VERSION ""

NS_ :

BS_:

BU_: RLPSU DPSU APSU PSB SHVU_RR vHS_B2 FCS EMCU SLB RCM CGW_CCU vDummy_HS_B ATS RLHV PFSU SGU ALBCU DSAU SWRC SHVU_FR RCS RRPSU BLTN_CAM SCM DLBCU OHCL RWPC RRHV WPC HOD ASAU

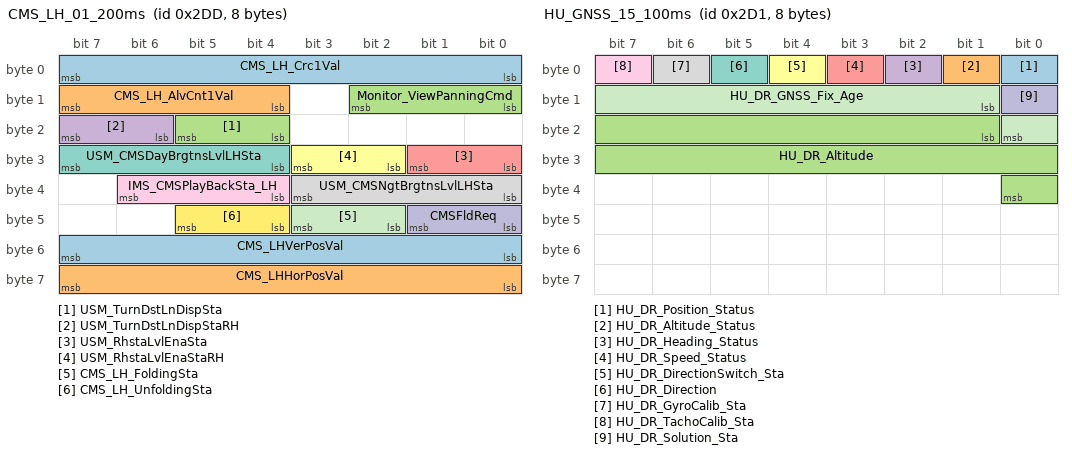
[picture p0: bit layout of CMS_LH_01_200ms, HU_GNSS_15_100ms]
BO_ 733 CMS_LH_01_200ms: 8 CGW_CCU
 SG_ CMS_LH_Crc1Val : 0|8@1+ (1,0) [0|0] ""  Vector__XXX
 SG_ CMS_LH_AlvCnt1Val : 12|4@1+ (1,0) [0|0] ""  Vector__XXX
 SG_ USM_TurnDstLnDispSta : 20|2@1+ (1,0) [0|0] ""  Vector__XXX
 SG_ USM_TurnDstLnDispStaRH : 22|2@1+ (1,0) [0|0] ""  Vector__XXX
 SG_ USM_RhstaLvlEnaSta : 24|2@1+ (1,0) [0|0] ""  Vector__XXX
 SG_ USM_RhstaLvlEnaStaRH : 26|2@1+ (1,0) [0|0] ""  Vector__XXX
 SG_ USM_CMSDayBrgtnsLvlLHSta : 28|4@1+ (1,0) [0|0] ""  Vector__XXX
 SG_ USM_CMSNgtBrgtnsLvlLHSta : 32|4@1+ (1,0) [0|0] ""  Vector__XXX
 SG_ IMS_CMSPlayBackSta_LH : 36|3@1+ (1,0) [0|0] ""  DPSU
 SG_ CMSFldReq : 40|2@1+ (1,0) [0|0] ""  Vector__XXX
 SG_ CMS_LH_FoldingSta : 42|2@1+ (1,0) [0|0] ""  Vector__XXX
 SG_ CMS_LH_UnfoldingSta : 44|2@1+ (1,0) [0|0] ""  Vector__XXX
 SG_ CMS_LHVerPosVal : 48|8@1+ (0.02,0) [0|0] "V"  Vector__XXX
 SG_ CMS_LHHorPosVal : 56|8@1+ (0.02,0) [0|0] "V"  Vector__XXX
 SG_ Monitor_ViewPanningCmd : 8|3@1+ (1,0) [0|0] ""  Vector__XXX

BO_ 721 HU_GNSS_15_100ms: 8 CGW_CCU
 SG_ HU_DR_Position_Status : 0|1@1+ (1,0) [0|0] ""  Vector__XXX
 SG_ HU_DR_Altitude_Status : 1|1@1+ (1,0) [0|0] ""  Vector__XXX
 SG_ HU_DR_Altitude : 17|16@1- (1,0) [0|0] "m"  BLTN_CAM
 SG_ HU_DR_Heading_Status : 2|1@1+ (1,0) [0|0] ""  Vector__XXX
 SG_ HU_DR_Speed_Status : 3|1@1+ (1,0) [0|0] ""  Vector__XXX
 SG_ HU_DR_DirectionSwitch_Sta : 4|1@1+ (1,0) [0|0] ""  Vector__XXX
 SG_ HU_DR_Direction : 5|1@1+ (1,0) [0|0] ""  Vector__XXX
 SG_ HU_DR_GyroCalib_Sta : 6|1@1+ (1,0) [0|0] ""  Vector__XXX
 SG_ HU_DR_TachoCalib_Sta : 7|1@1+ (1,0) [0|0] ""  Vector__XXX
 SG_ HU_DR_Solution_Sta : 8|1@1+ (1,0) [0|0] ""  Vector__XXX
 SG_ HU_DR_GNSS_Fix_Age : 9|8@1+ (1,0) [0|0] "Sec"  Vector__XXX

BO_ 722 HU_GNSS_16_100ms: 8 CGW_CCU
 SG_ HU_DR_Latitude : 0|32@1- (1,0) [0|0] "¢ª"  BLTN_CAM
 SG_ HU_DR_Longitude : 32|32@1- (1,0) [0|0] "¢ª"  BLTN_CAM

BO_ 723 HU_GNSS_17_100ms: 8 CGW_CCU
 SG_ HU_DR_Heading : 0|16@1+ (1,0) [0|0] "¢ª"  BLTN_CAM
 SG_ HU_DR_Speed : 16|16@1- (0.01,0) [0|0] "m/s"  Vector__XXX

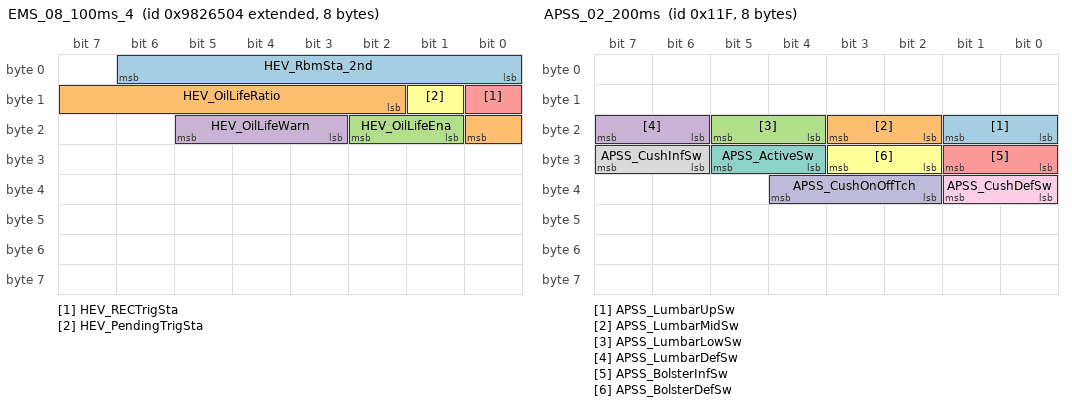
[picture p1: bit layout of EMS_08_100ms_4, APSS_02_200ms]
BO_ 2307024132 EMS_08_100ms_4: 8 CGW_CCU
 SG_ HEV_RbmSta_2nd : 0|7@1+ (1,0) [0|0] ""  Vector__XXX
 SG_ HEV_OilLifeRatio : 10|7@1+ (1,0) [0|0] "%"  Vector__XXX
 SG_ HEV_OilLifeEna : 17|2@1+ (1,0) [0|0] ""  Vector__XXX
 SG_ HEV_OilLifeWarn : 19|3@1+ (1,0) [0|0] ""  Vector__XXX
 SG_ HEV_RECTrigSta : 8|1@1+ (1,0) [0|0] ""  Vector__XXX
 SG_ HEV_PendingTrigSta : 9|1@1+ (1,0) [0|0] ""  Vector__XXX

BO_ 287 APSS_02_200ms: 8 APSU
 SG_ APSS_LumbarUpSw : 16|2@1+ (1,0) [0|0] ""  ALBCU,CGW_CCU
 SG_ APSS_LumbarMidSw : 18|2@1+ (1,0) [0|0] ""  ALBCU,CGW_CCU
 SG_ APSS_LumbarLowSw : 20|2@1+ (1,0) [0|0] ""  ALBCU,CGW_CCU
 SG_ APSS_LumbarDefSw : 22|2@1+ (1,0) [0|0] ""  ALBCU,CGW_CCU
 SG_ APSS_BolsterInfSw : 24|2@1+ (1,0) [0|0] ""  ALBCU,CGW_CCU
 SG_ APSS_BolsterDefSw : 26|2@1+ (1,0) [0|0] ""  ALBCU,CGW_CCU
 SG_ APSS_ActiveSw : 28|2@1+ (1,0) [0|0] ""  ALBCU
 SG_ APSS_CushInfSw : 30|2@1+ (1,0) [0|0] ""  ALBCU
 SG_ APSS_CushDefSw : 32|2@1+ (1,0) [0|0] ""  ALBCU
 SG_ APSS_CushOnOffTch : 34|3@1+ (1,0) [0|0] ""  ALBCU

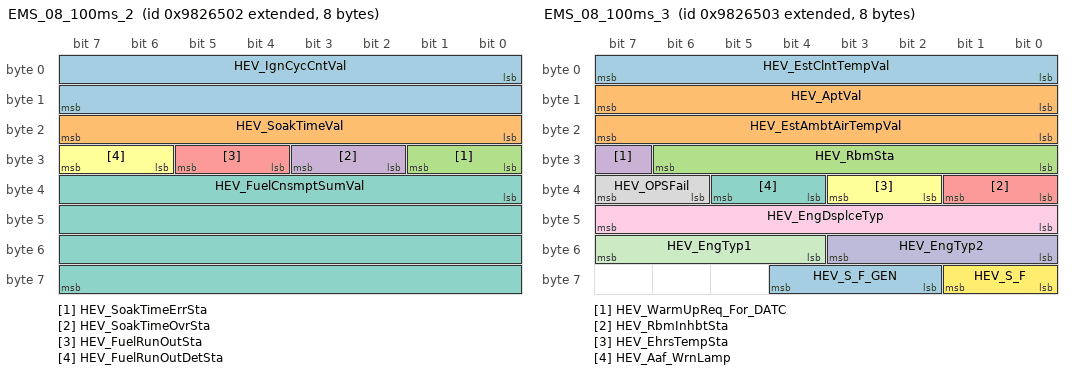
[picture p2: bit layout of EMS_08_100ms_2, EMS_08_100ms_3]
BO_ 2307024130 EMS_08_100ms_2: 8 CGW_CCU
 SG_ HEV_IgnCycCntVal : 0|16@1+ (1,0) [0|0] ""  Vector__XXX
 SG_ HEV_SoakTimeVal : 16|8@1+ (1,0) [0|0] "Min"  Vector__XXX
 SG_ HEV_SoakTimeErrSta : 24|2@1+ (1,0) [0|0] ""  Vector__XXX
 SG_ HEV_SoakTimeOvrSta : 26|2@1+ (1,0) [0|0] ""  Vector__XXX
 SG_ HEV_FuelRunOutSta : 28|2@1+ (1,0) [0|0] ""  Vector__XXX
 SG_ HEV_FuelRunOutDetSta : 30|2@1+ (1,0) [0|0] ""  Vector__XXX
 SG_ HEV_FuelCnsmptSumVal : 32|32@1+ (1.280018E-4,0) [0|0] "ml"  Vector__XXX

BO_ 2307024131 EMS_08_100ms_3: 8 CGW_CCU
 SG_ HEV_EstClntTempVal : 0|8@1+ (0.75,-48) [0|0] "¡É"  Vector__XXX
 SG_ HEV_EstAmbtAirTempVal : 16|8@1+ (0.75,-48) [0|0] "¡É"  Vector__XXX
 SG_ HEV_RbmSta : 24|7@1+ (1,0) [0|0] ""  Vector__XXX
 SG_ HEV_WarmUpReq_For_DATC : 31|1@1+ (1,0) [0|0] ""  Vector__XXX
 SG_ HEV_RbmInhbtSta : 32|2@1+ (1,0) [0|0] ""  Vector__XXX
 SG_ HEV_EhrsTempSta : 34|2@1+ (1,0) [0|0] ""  Vector__XXX
 SG_ HEV_Aaf_WrnLamp : 36|2@1+ (1,0) [0|0] ""  Vector__XXX
 SG_ HEV_OPSFail : 38|2@1+ (1,0) [0|0] ""  Vector__XXX
 SG_ HEV_EngDsplceTyp : 40|8@1+ (0.1,0) [0|0] "liter"  Vector__XXX
 SG_ HEV_EngTyp2 : 48|4@1+ (1,0) [0|0] ""  Vector__XXX
 SG_ HEV_EngTyp1 : 52|4@1+ (1,0) [0|0] ""  Vector__XXX
 SG_ HEV_S_F : 56|2@1+ (1,0) [0|0] ""  Vector__XXX
 SG_ HEV_S_F_GEN : 58|3@1+ (1,0) [0|0] ""  Vector__XXX
 SG_ HEV_AptVal : 8|8@1+ (2,0) [0|0] "PSI"  Vector__XXX

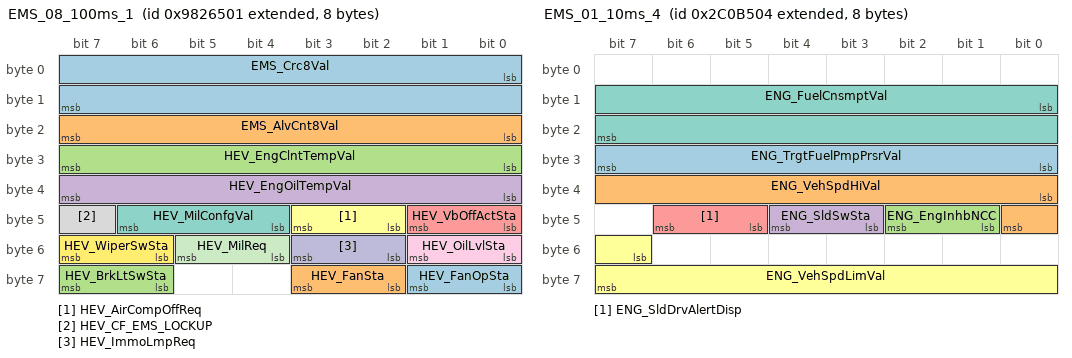
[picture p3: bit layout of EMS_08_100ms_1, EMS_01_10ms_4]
BO_ 2307024129 EMS_08_100ms_1: 8 CGW_CCU
 SG_ EMS_Crc8Val : 0|16@1+ (1,0) [0|0] ""  Vector__XXX
 SG_ EMS_AlvCnt8Val : 16|8@1+ (1,0) [0|0] ""  Vector__XXX
 SG_ HEV_EngClntTempVal : 24|8@1+ (0.75,-48) [0|0] "¡É"  Vector__XXX
 SG_ HEV_EngOilTempVal : 32|8@1+ (1,-40) [0|0] "¡É"  Vector__XXX
 SG_ HEV_VbOffActSta : 40|2@1+ (1,0) [0|0] ""  Vector__XXX
 SG_ HEV_AirCompOffReq : 42|2@1+ (1,0) [0|0] ""  Vector__XXX
 SG_ HEV_MilConfgVal : 44|3@1+ (1,0) [0|0] ""  Vector__XXX
 SG_ HEV_CF_EMS_LOCKUP : 47|1@1+ (1,0) [0|0] ""  Vector__XXX
 SG_ HEV_OilLvlSta : 48|2@1+ (1,0) [0|0] ""  Vector__XXX
 SG_ HEV_ImmoLmpReq : 50|2@1+ (1,0) [0|0] ""  Vector__XXX
 SG_ HEV_MilReq : 52|2@1+ (1,0) [0|0] ""  Vector__XXX
 SG_ HEV_WiperSwSta : 54|2@1+ (1,0) [0|0] ""  Vector__XXX
 SG_ HEV_FanOpSta : 56|2@1+ (1,0) [0|0] ""  Vector__XXX
 SG_ HEV_FanSta : 58|2@1+ (1,0) [0|0] ""  Vector__XXX
 SG_ HEV_BrkLtSwSta : 62|2@1+ (1,0) [0|0] ""  BLTN_CAM

BO_ 2193667332 EMS_01_10ms_4: 8 CGW_CCU
 SG_ ENG_TrgtFuelPmpPrsrVal : 24|8@1+ (3.137254902,0) [0|0] "kPa"  Vector__XXX
 SG_ ENG_VehSpdHiVal : 32|9@1+ (1,0) [0|0] "km/h"  Vector__XXX
 SG_ ENG_EngInhbNCC : 41|2@1+ (1,0) [0|0] ""  Vector__XXX
 SG_ ENG_SldSwSta : 43|2@1+ (1,0) [0|0] ""  Vector__XXX
 SG_ ENG_SldDrvAlertDisp : 45|2@1+ (1,0) [0|0] ""  Vector__XXX
 SG_ ENG_VehSpdLimVal : 55|9@1+ (1,0) [0|0] "km/h"  Vector__XXX
 SG_ ENG_FuelCnsmptVal : 8|16@1+ (0.128,0) [0|0] "ul"  Vector__XXX

BO_ 2193667331 EMS_01_10ms_3: 8 CGW_CCU
 SG_ ENG_TrgtIdleRpmVal : 0|8@1+ (10,0) [0|0] "rpm"  Vector__XXX
 SG_ ENG_GearShftDnDis : 10|2@1+ (1,0) [0|0] ""  Vector__XXX
 SG_ ENG_DsrGearPosDis : 12|4@1+ (1,0) [0|0] ""  Vector__XXX
 SG_ ENG_SldFuncSta : 16|2@1+ (1,0) [0|0] ""  Vector__XXX
 SG_ ENG_SldActnSta : 18|2@1+ (1,0) [0|0] ""  Vector__XXX
 SG_ ENG_FuelTnkPrsrSta : 20|2@1+ (1,0) [0|0] ""  Vector__XXX
 SG_ ENG_IsgBzrReq : 22|2@1+ (1,0) [0|0] ""  Vector__XXX
 SG_ ENG_IsgFuelCnsmptDis : 24|2@1+ (1,0) [0|0] ""  Vector__XXX
 SG_ ENG_FuelCapOpnSta : 26|2@1+ (1,0) [0|0] ""  Vector__XXX
 SG_ ENG_EcoDrvActvSta : 28|2@1+ (1,0) [0|0] ""  Vector__XXX
 SG_ ENG_EngRunSta : 30|2@1+ (1,0) [0|0] ""  Vector__XXX
 SG_ ENG_Isg2Sta : 32|2@1+ (2,0) [0|0] ""  Vector__XXX
 SG_ ENG_IgnOnSta : 34|2@1+ (1,0) [0|0] ""  Vector__XXX
 SG_ ENG_Ack4TcsSta : 36|2@1+ (1,0) [0|0] ""  Vector__XXX
 SG_ ENG_FuelCutOffSta : 38|2@1+ (1,0) [0|0] ""  Vector__XXX
 SG_ ENG_CrctTqSta : 40|2@1+ (1,0) [0|0] ""  Vector__XXX
 SG_ ENG_AirCompRlySta : 42|2@1+ (1,0) [0|0] ""  Vector__XXX
 SG_ ENG_LnchCntrlSta : 45|3@1+ (1,0) [0|0] ""  Vector__XXX
 SG_ ENG_EngSpdVal : 48|16@1+ (0.25,0) [0|0] "rpm"  EMCU
 SG_ ENG_GearShftUpDis : 8|2@1+ (1,0) [0|0] ""  Vector__XXX

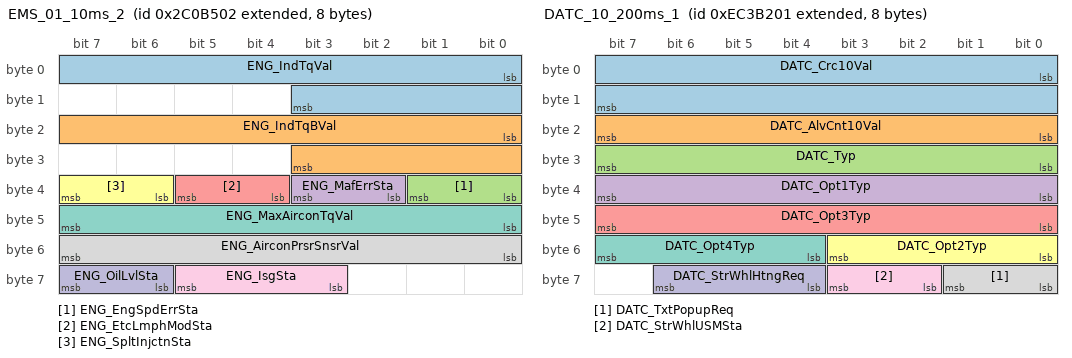
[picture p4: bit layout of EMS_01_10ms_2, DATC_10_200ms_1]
BO_ 2193667330 EMS_01_10ms_2: 8 CGW_CCU
 SG_ ENG_IndTqVal : 0|12@1- (1,0) [0|0] "Nm"  Vector__XXX
 SG_ ENG_IndTqBVal : 16|12@1- (1,0) [0|0] "Nm"  Vector__XXX
 SG_ ENG_EngSpdErrSta : 32|2@1+ (1,0) [0|0] ""  Vector__XXX
 SG_ ENG_MafErrSta : 34|2@1+ (1,0) [0|0] ""  Vector__XXX
 SG_ ENG_EtcLmphModSta : 36|2@1+ (1,0) [0|0] ""  Vector__XXX
 SG_ ENG_SpltInjctnSta : 38|2@1+ (1,0) [0|0] ""  Vector__XXX
 SG_ ENG_MaxAirconTqVal : 40|8@1+ (0.2,0) [0|0] "Nm"  Vector__XXX
 SG_ ENG_AirconPrsrSnsrVal : 48|8@1+ (125,0) [0|0] "hPa"  Vector__XXX
 SG_ ENG_IsgSta : 59|3@1+ (1,0) [0|0] ""  APSU,RLHV,RRHV,SHVU_FR,SHVU_RR,DPSU,RRPSU,RLPSU,EMCU
 SG_ ENG_OilLvlSta : 62|2@1+ (1,0) [0|0] ""  Vector__XXX

BO_ 2395189761 DATC_10_200ms_1: 8 CGW_CCU
 SG_ DATC_Crc10Val : 0|16@1+ (1,0) [0|0] ""  Vector__XXX
 SG_ DATC_AlvCnt10Val : 16|8@1+ (1,0) [0|0] ""  Vector__XXX
 SG_ DATC_Typ : 24|8@1+ (1,0) [0|0] ""  RLHV,RRHV,SHVU_FR,SHVU_RR,ATS
 SG_ DATC_Opt1Typ : 32|8@1+ (1,0) [0|0] ""  ATS
 SG_ DATC_Opt3Typ : 40|8@1+ (1,0) [0|0] ""  ATS
 SG_ DATC_Opt2Typ : 48|4@1+ (1,0) [0|0] ""  ATS
 SG_ DATC_Opt4Typ : 52|4@1+ (1,0) [0|0] ""  ATS
 SG_ DATC_TxtPopupReq : 56|2@1+ (1,0) [0|0] ""  Vector__XXX
 SG_ DATC_StrWhlUSMSta : 58|2@1+ (1,0) [0|0] ""  APSU
 SG_ DATC_StrWhlHtngReq : 60|3@1+ (1,0) [0|0] ""  Vector__XXX

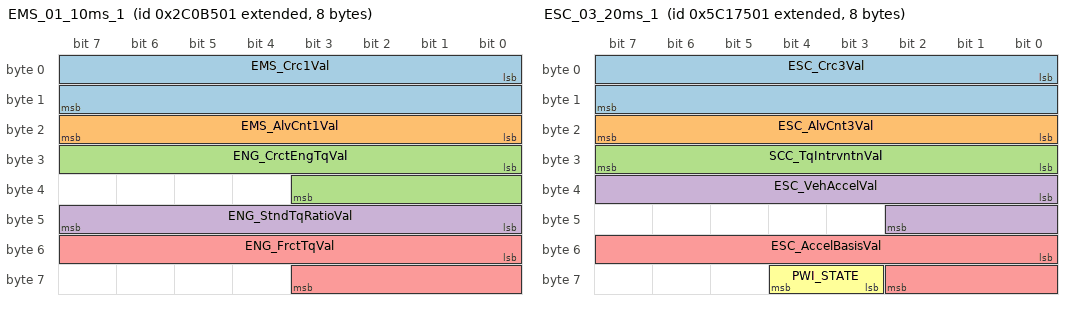
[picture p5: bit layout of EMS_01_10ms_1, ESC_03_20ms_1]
BO_ 2193667329 EMS_01_10ms_1: 8 CGW_CCU
 SG_ EMS_Crc1Val : 0|16@1+ (1,0) [0|0] ""  Vector__XXX
 SG_ EMS_AlvCnt1Val : 16|8@1+ (1,0) [0|0] ""  Vector__XXX
 SG_ ENG_CrctEngTqVal : 24|12@1- (1,0) [0|0] "Nm"  Vector__XXX
 SG_ ENG_StndTqRatioVal : 40|8@1+ (0.0078,0) [0|0] ""  Vector__XXX
 SG_ ENG_FrctTqVal : 48|12@1- (1,0) [0|0] "Nm"  Vector__XXX

BO_ 2214659332 EMS_07_10ms_4: 8 CGW_CCU

BO_ 2214659331 EMS_07_10ms_3: 8 CGW_CCU

BO_ 2244048129 ESC_03_20ms_1: 8 CGW_CCU
 SG_ ESC_Crc3Val : 0|16@1+ (1,0) [0|0] ""  Vector__XXX
 SG_ ESC_AlvCnt3Val : 16|8@1+ (1,0) [0|0] ""  Vector__XXX
 SG_ SCC_TqIntrvntnVal : 24|8@1+ (0.390625,0) [0|0] "%"  Vector__XXX
 SG_ ESC_VehAccelVal : 32|11@1+ (0.01,-10.23) [0|0] "m/s^2"  Vector__XXX
 SG_ ESC_AccelBasisVal : 48|11@1+ (0.01,-10.23) [0|0] "m/s^2"  Vector__XXX
 SG_ PWI_STATE : 59|2@1+ (1,0) [0|0] ""  Vector__XXX

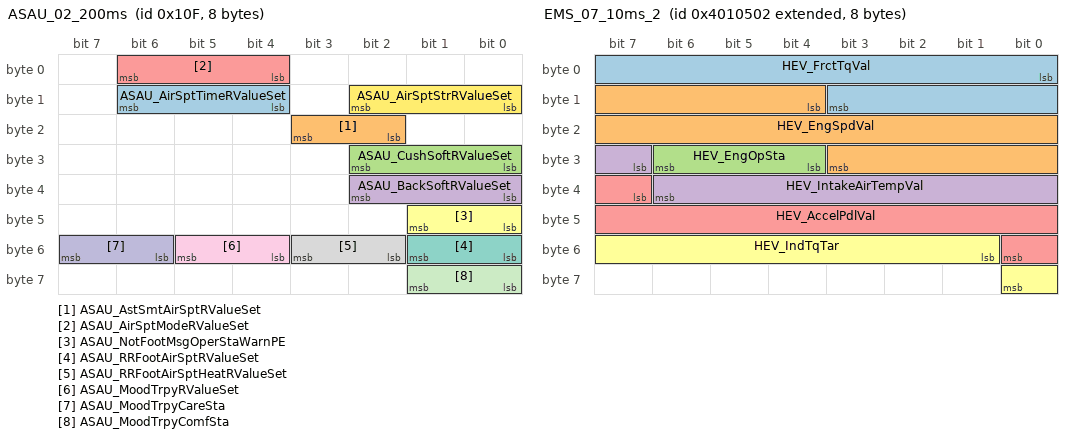
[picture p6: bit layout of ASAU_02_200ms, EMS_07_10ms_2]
BO_ 271 ASAU_02_200ms: 8 ASAU
 SG_ ASAU_AirSptTimeRValueSet : 12|3@1+ (1,0) [0|0] ""  CGW_CCU
 SG_ ASAU_AstSmtAirSptRValueSet : 18|2@1+ (1,0) [0|0] ""  CGW_CCU
 SG_ ASAU_CushSoftRValueSet : 24|3@1+ (1,0) [0|0] ""  CGW_CCU
 SG_ ASAU_BackSoftRValueSet : 32|3@1+ (1,0) [0|0] ""  CGW_CCU
 SG_ ASAU_AirSptModeRValueSet : 4|3@1+ (1,0) [0|0] ""  CGW_CCU
 SG_ ASAU_NotFootMsgOperStaWarnPE : 40|2@1+ (1,0) [0|0] ""  ATS
 SG_ ASAU_RRFootAirSptRValueSet : 48|2@1+ (1,0) [0|0] ""  ATS
 SG_ ASAU_RRFootAirSptHeatRValueSet : 50|2@1+ (1,0) [0|0] ""  ATS
 SG_ ASAU_MoodTrpyRValueSet : 52|2@1+ (1,0) [0|0] ""  CGW_CCU
 SG_ ASAU_MoodTrpyCareSta : 54|2@1+ (1,0) [0|0] ""  CGW_CCU
 SG_ ASAU_MoodTrpyComfSta : 56|2@1+ (1,0) [0|0] ""  CGW_CCU
 SG_ ASAU_AirSptStrRValueSet : 8|3@1+ (1,0) [0|0] ""  CGW_CCU

BO_ 2214659330 EMS_07_10ms_2: 8 CGW_CCU
 SG_ HEV_FrctTqVal : 0|12@1+ (0.1,0) [0|0] "Nm"  Vector__XXX
 SG_ HEV_EngSpdVal : 12|16@1+ (0.25,0) [0|0] "rpm"  Vector__XXX
 SG_ HEV_EngOpSta : 28|3@1+ (1,0) [0|0] ""  WPC,RWPC,PFSU
 SG_ HEV_IntakeAirTempVal : 31|8@1+ (0.75,-48) [0|0] "¡É"  Vector__XXX
 SG_ HEV_AccelPdlVal : 39|10@1+ (0.09784,0) [0|0] "%"  BLTN_CAM
 SG_ HEV_IndTqTar : 49|8@1+ (0.3906,0) [0|0] "%"  Vector__XXX

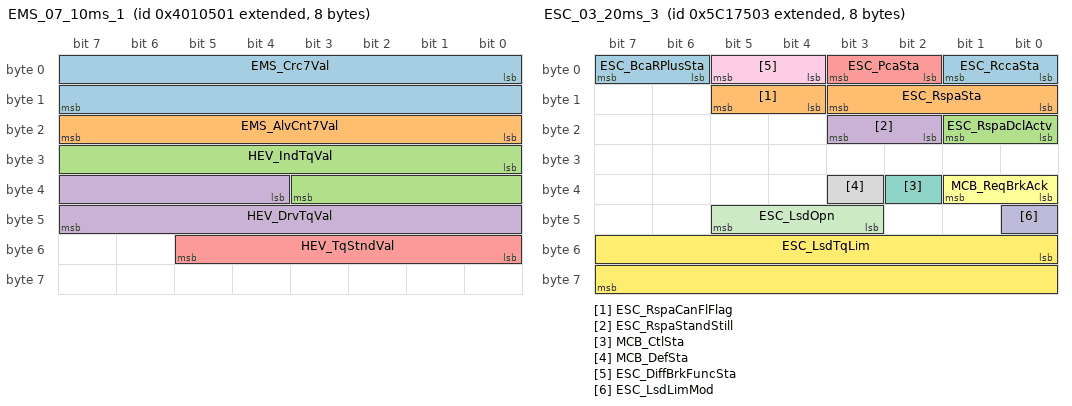
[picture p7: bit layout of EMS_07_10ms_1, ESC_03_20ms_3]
BO_ 2214659329 EMS_07_10ms_1: 8 CGW_CCU
 SG_ EMS_Crc7Val : 0|16@1+ (1,0) [0|0] ""  Vector__XXX
 SG_ EMS_AlvCnt7Val : 16|8@1+ (1,0) [0|0] ""  Vector__XXX
 SG_ HEV_IndTqVal : 24|12@1+ (0.1,0) [0|0] "Nm"  Vector__XXX
 SG_ HEV_DrvTqVal : 36|12@1+ (0.390625,0) [0|0] "%"  Vector__XXX
 SG_ HEV_TqStndVal : 48|6@1+ (10,0) [0|0] "Nm"  Vector__XXX

BO_ 2244048131 ESC_03_20ms_3: 8 CGW_CCU
 SG_ ESC_RccaSta : 0|2@1+ (1,0) [0|0] ""  Vector__XXX
 SG_ ESC_RspaCanFlFlag : 12|2@1+ (1,0) [0|0] ""  Vector__XXX
 SG_ ESC_RspaDclActv : 16|2@1+ (1,0) [0|0] ""  Vector__XXX
 SG_ ESC_RspaStandStill : 18|2@1+ (1,0) [0|0] ""  Vector__XXX
 SG_ ESC_PcaSta : 2|2@1+ (1,0) [0|0] ""  Vector__XXX
 SG_ MCB_ReqBrkAck : 32|2@1+ (1,0) [0|0] ""  Vector__XXX
 SG_ MCB_CtlSta : 34|1@1+ (1,0) [0|0] ""  Vector__XXX
 SG_ MCB_DefSta : 35|1@1+ (1,0) [0|0] ""  Vector__XXX
 SG_ ESC_DiffBrkFuncSta : 4|2@1+ (1,0) [0|0] ""  Vector__XXX
 SG_ ESC_LsdLimMod : 40|1@1+ (1,0) [0|0] ""  Vector__XXX
 SG_ ESC_LsdOpn : 43|3@1+ (1,0) [0|0] ""  Vector__XXX
 SG_ ESC_LsdTqLim : 48|16@1+ (1,0) [0|0] "Nm"  Vector__XXX
 SG_ ESC_BcaRPlusSta : 6|2@1+ (1,0) [0|0] ""  Vector__XXX
 SG_ ESC_RspaSta : 8|4@1+ (1,0) [0|0] ""  Vector__XXX

BO_ 2244048130 ESC_03_20ms_2: 8 CGW_CCU
 SG_ SCC_OptTyp : 0|2@1+ (1,0) [0|0] ""  Vector__XXX
 SG_ ESC_BrkLtReq : 10|2@1+ (1,0) [0|0] ""  Vector__XXX
 SG_ ESC_DclEnblReq : 12|2@1+ (1,0) [0|0] ""  Vector__XXX
 SG_ ESC_DrvOvrdSta : 16|2@1+ (1,0) [0|0] ""  Vector__XXX
 SG_ ESC_DrvBrkSta : 18|2@1+ (1,0) [0|0] ""  Vector__XXX
 SG_ SCC_EnblReq : 2|2@1+ (1,0) [0|0] ""  Vector__XXX
 SG_ ESC_DrvBrkActvSta : 20|2@1+ (1,0) [0|0] ""  Vector__XXX
 SG_ ESC_PrkBrkActvSta : 22|2@1+ (1,0) [0|0] ""  Vector__XXX
 SG_ ESC_HDP_FltMonSta : 24|3@1+ (1,0) [0|0] ""  PSB
 SG_ FCA_EquipSta : 32|2@1+ (1,0) [0|0] ""  Vector__XXX
 SG_ FCA_AvlblSta : 34|2@1+ (1,0) [0|0] ""  Vector__XXX
 SG_ ESC_FCA_ActvSta : 36|2@1+ (1,0) [0|0] ""  Vector__XXX
 SG_ ESC_DBS_ActvSta : 38|2@1+ (1,0) [0|0] ""  Vector__XXX
 SG_ SCC_TqReq : 4|2@1+ (1,0) [0|0] ""  Vector__XXX
 SG_ ESC_HDP_EgSta : 40|3@1+ (1,0) [0|0] ""  Vector__XXX
 SG_ ESC_HDP_EnblReq : 43|3@1+ (1,0) [0|0] ""  Vector__XXX
 SG_ ESC_BrkdFltStndstill : 56|2@1+ (1,0) [0|0] ""  Vector__XXX
 SG_ SCC_ReqLimSta : 6|2@1+ (1,0) [0|0] ""  Vector__XXX
 SG_ ESC_StdStillVal : 8|2@1+ (1,0) [0|0] ""  Vector__XXX

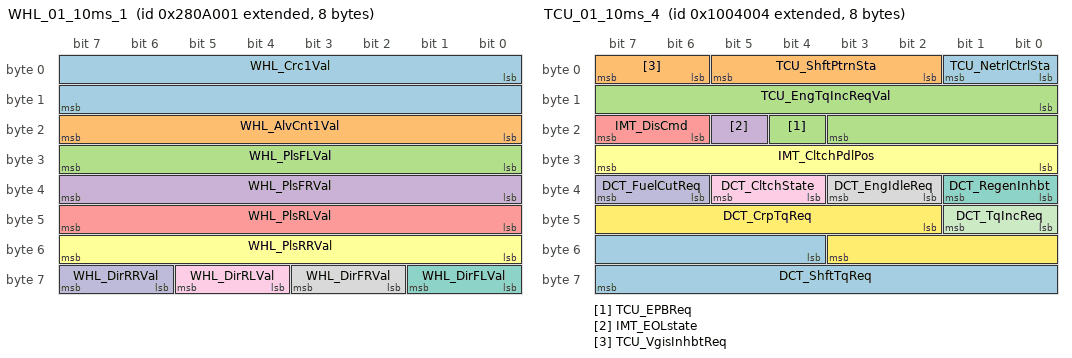
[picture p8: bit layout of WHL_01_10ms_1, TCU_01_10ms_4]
BO_ 2189467649 WHL_01_10ms_1: 8 CGW_CCU
 SG_ WHL_Crc1Val : 0|16@1+ (1,0) [0|0] ""  Vector__XXX
 SG_ WHL_AlvCnt1Val : 16|8@1+ (1,0) [0|0] ""  Vector__XXX
 SG_ WHL_PlsFLVal : 24|8@1+ (0.5,0) [0|0] "pulse count"  Vector__XXX
 SG_ WHL_PlsFRVal : 32|8@1+ (0.5,0) [0|0] "pulse count"  Vector__XXX
 SG_ WHL_PlsRLVal : 40|8@1+ (0.5,0) [0|0] "pulse count"  Vector__XXX
 SG_ WHL_PlsRRVal : 48|8@1+ (0.5,0) [0|0] "pulse count"  Vector__XXX
 SG_ WHL_DirFLVal : 56|2@1+ (1,0) [0|0] ""  Vector__XXX
 SG_ WHL_DirFRVal : 58|2@1+ (1,0) [0|0] ""  Vector__XXX
 SG_ WHL_DirRLVal : 60|2@1+ (1,0) [0|0] ""  Vector__XXX
 SG_ WHL_DirRRVal : 62|2@1+ (1,0) [0|0] ""  Vector__XXX

BO_ 2164277252 TCU_01_10ms_4: 8 CGW_CCU
 SG_ TCU_NetrlCtrlSta : 0|2@1+ (1,0) [0|0] ""  Vector__XXX
 SG_ TCU_ShftPtrnSta : 2|4@1+ (1,0) [0|0] ""  Vector__XXX
 SG_ TCU_EPBReq : 20|1@1+ (1,0) [0|0] ""  Vector__XXX
 SG_ IMT_EOLstate : 21|1@1+ (1,0) [0|0] ""  Vector__XXX
 SG_ IMT_DisCmd : 22|2@1+ (1,0) [0|0] ""  Vector__XXX
 SG_ IMT_CltchPdlPos : 24|8@1+ (0.390625,0) [0|0] "%"  Vector__XXX
 SG_ DCT_RegenInhbt : 32|2@1+ (1,0) [0|0] ""  Vector__XXX
 SG_ DCT_EngIdleReq : 34|2@1+ (1,0) [0|0] ""  Vector__XXX
 SG_ DCT_CltchState : 36|2@1+ (1,0) [0|0] ""  Vector__XXX
 SG_ DCT_FuelCutReq : 38|2@1+ (1,0) [0|0] ""  Vector__XXX
 SG_ DCT_TqIncReq : 40|2@1+ (1,0) [0|0] ""  Vector__XXX
 SG_ DCT_CrpTqReq : 42|10@1+ (1,-512) [0|0] "Nm"  Vector__XXX
 SG_ DCT_ShftTqReq : 52|12@1- (1,0) [0|0] "Nm"  Vector__XXX
 SG_ TCU_VgisInhbtReq : 6|2@1+ (1,0) [0|0] ""  Vector__XXX
 SG_ TCU_EngTqIncReqVal : 8|12@1- (1,0) [0|0] "Nm"  Vector__XXX

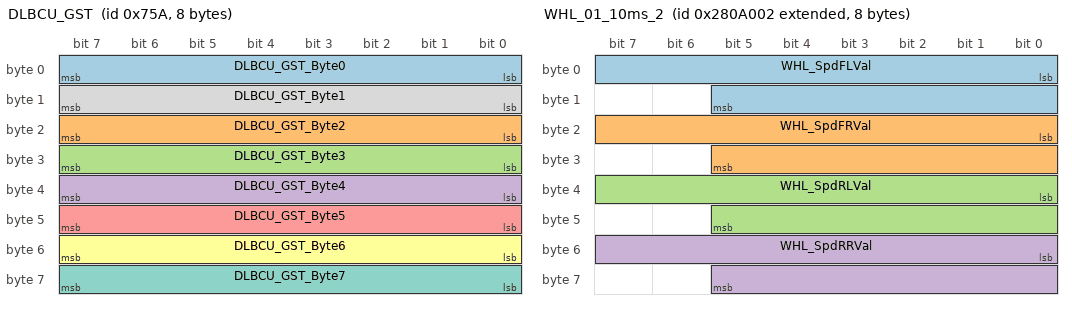
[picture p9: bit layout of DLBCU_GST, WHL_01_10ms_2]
BO_ 1882 DLBCU_GST: 8 DLBCU
 SG_ DLBCU_GST_Byte0 : 0|8@1+ (1,0) [0|0] ""  CGW_CCU
 SG_ DLBCU_GST_Byte2 : 16|8@1+ (1,0) [0|0] ""  CGW_CCU
 SG_ DLBCU_GST_Byte3 : 24|8@1+ (1,0) [0|0] ""  CGW_CCU
 SG_ DLBCU_GST_Byte4 : 32|8@1+ (1,0) [0|0] ""  CGW_CCU
 SG_ DLBCU_GST_Byte5 : 40|8@1+ (1,0) [0|0] ""  CGW_CCU
 SG_ DLBCU_GST_Byte6 : 48|8@1+ (1,0) [0|0] ""  CGW_CCU
 SG_ DLBCU_GST_Byte7 : 56|8@1+ (1,0) [0|0] ""  CGW_CCU
 SG_ DLBCU_GST_Byte1 : 8|8@1+ (1,0) [0|0] ""  CGW_CCU

BO_ 2189467650 WHL_01_10ms_2: 8 CGW_CCU
 SG_ WHL_SpdFLVal : 0|14@1+ (0.03125,0) [0|0] "km^h"  PSB
 SG_ WHL_SpdFRVal : 16|14@1+ (0.03125,0) [0|0] "km^h"  PSB
 SG_ WHL_SpdRLVal : 32|14@1+ (0.03125,0) [0|0] "km^h"  PSB,APSU
 SG_ WHL_SpdRRVal : 48|14@1+ (0.03125,0) [0|0] "km^h"  PSB,APSU

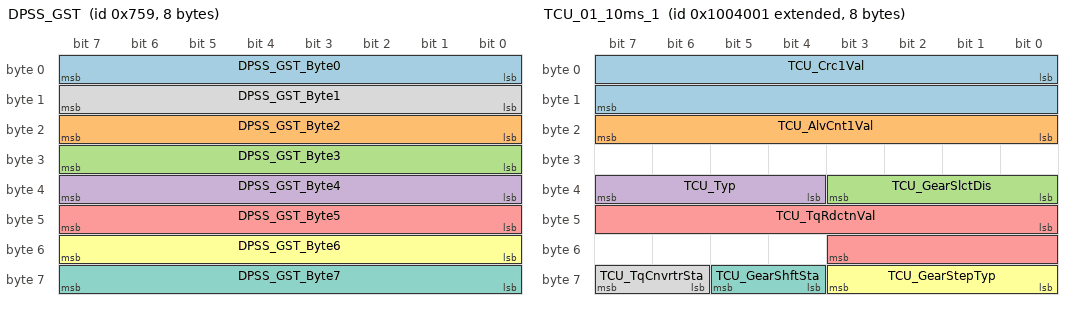
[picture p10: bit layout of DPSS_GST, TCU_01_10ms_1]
BO_ 1881 DPSS_GST: 8 DPSU
 SG_ DPSS_GST_Byte0 : 0|8@1+ (1,0) [0|0] ""  CGW_CCU
 SG_ DPSS_GST_Byte2 : 16|8@1+ (1,0) [0|0] ""  CGW_CCU
 SG_ DPSS_GST_Byte3 : 24|8@1+ (1,0) [0|0] ""  CGW_CCU
 SG_ DPSS_GST_Byte4 : 32|8@1+ (1,0) [0|0] ""  CGW_CCU
 SG_ DPSS_GST_Byte5 : 40|8@1+ (1,0) [0|0] ""  CGW_CCU
 SG_ DPSS_GST_Byte6 : 48|8@1+ (1,0) [0|0] ""  CGW_CCU
 SG_ DPSS_GST_Byte7 : 56|8@1+ (1,0) [0|0] ""  CGW_CCU
 SG_ DPSS_GST_Byte1 : 8|8@1+ (1,0) [0|0] ""  CGW_CCU

BO_ 2189467651 WHL_01_10ms_3: 8 CGW_CCU
 SG_ WHL_SpdCalParmtr : 8|9@1+ (0.5,200) [0|0] "mm"  Vector__XXX

BO_ 2164277249 TCU_01_10ms_1: 8 CGW_CCU
 SG_ TCU_Crc1Val : 0|16@1+ (1,0) [0|0] ""  Vector__XXX
 SG_ TCU_AlvCnt1Val : 16|8@1+ (1,0) [0|0] ""  EMCU
 SG_ TCU_GearSlctDis : 32|4@1+ (1,0) [0|0] ""  APSU,RLHV,RRHV,PFSU,RRPSU,RLPSU,BLTN_CAM
 SG_ TCU_Typ : 36|4@1+ (1,0) [0|0] ""  APSU,PFSU
 SG_ TCU_TqRdctnVal : 40|12@1- (1,0) [0|0] "Nm"  Vector__XXX
 SG_ TCU_GearStepTyp : 56|4@1+ (1,0) [0|0] ""  Vector__XXX
 SG_ TCU_GearShftSta : 60|2@1+ (1,0) [0|0] ""  Vector__XXX
 SG_ TCU_TqCnvrtrSta : 62|2@1+ (1,0) [0|0] ""  EMCU

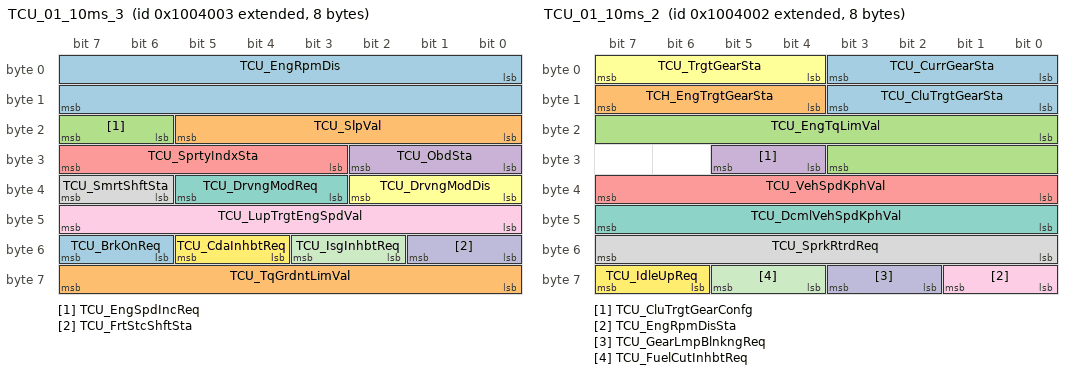
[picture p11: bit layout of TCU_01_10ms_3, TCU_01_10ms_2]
BO_ 2164277251 TCU_01_10ms_3: 8 CGW_CCU
 SG_ TCU_EngRpmDis : 0|16@1+ (0.25,0) [0|0] "rpm"  Vector__XXX
 SG_ TCU_SlpVal : 16|6@1+ (0.5,-16) [0|0] "%"  Vector__XXX
 SG_ TCU_EngSpdIncReq : 22|2@1+ (1,0) [0|0] ""  Vector__XXX
 SG_ TCU_ObdSta : 24|3@1+ (1,0) [0|0] ""  Vector__XXX
 SG_ TCU_SprtyIndxSta : 27|5@1+ (1,0) [0|0] ""  Vector__XXX
 SG_ TCU_DrvngModDis : 32|3@1+ (1,0) [0|0] ""  Vector__XXX
 SG_ TCU_DrvngModReq : 35|3@1+ (1,0) [0|0] ""  Vector__XXX
 SG_ TCU_SmrtShftSta : 38|2@1+ (1,0) [0|0] ""  Vector__XXX
 SG_ TCU_LupTrgtEngSpdVal : 40|8@1+ (10,500) [0|0] "rpm"  Vector__XXX
 SG_ TCU_FrtStcShftSta : 48|2@1+ (1,0) [0|0] ""  Vector__XXX
 SG_ TCU_IsgInhbtReq : 50|2@1+ (1,0) [0|0] ""  Vector__XXX
 SG_ TCU_CdaInhbtReq : 52|2@1+ (1,0) [0|0] ""  Vector__XXX
 SG_ TCU_BrkOnReq : 54|2@1+ (1,0) [0|0] ""  Vector__XXX
 SG_ TCU_TqGrdntLimVal : 56|8@1+ (10,0) [0|0] "Nm/s"  Vector__XXX

BO_ 2164277250 TCU_01_10ms_2: 8 CGW_CCU
 SG_ TCU_CurrGearSta : 0|4@1+ (1,0) [0|0] ""  EMCU
 SG_ TCH_EngTrgtGearSta : 12|4@1+ (1,0) [0|0] ""  Vector__XXX
 SG_ TCU_EngTqLimVal : 16|12@1- (1,0) [0|0] "Nm"  Vector__XXX
 SG_ TCU_CluTrgtGearConfg : 28|2@1+ (1,0) [0|0] ""  Vector__XXX
 SG_ TCU_VehSpdKphVal : 32|8@1+ (1,0) [0|0] "km/h"  Vector__XXX
 SG_ TCU_TrgtGearSta : 4|4@1+ (1,0) [0|0] ""  Vector__XXX
 SG_ TCU_DcmlVehSpdKphVal : 40|8@1+ (0.0078125,0) [0|0] "km/h"  Vector__XXX
 SG_ TCU_SprkRtrdReq : 48|8@1+ (0.375,-23.625) [0|0] "¢ª"  Vector__XXX
 SG_ TCU_EngRpmDisSta : 56|2@1+ (1,0) [0|0] ""  Vector__XXX
 SG_ TCU_GearLmpBlnkngReq : 58|2@1+ (1,0) [0|0] ""  Vector__XXX
 SG_ TCU_FuelCutInhbtReq : 60|2@1+ (1,0) [0|0] ""  Vector__XXX
 SG_ TCU_IdleUpReq : 62|2@1+ (1,0) [0|0] ""  Vector__XXX
 SG_ TCU_CluTrgtGearSta : 8|4@1+ (1,0) [0|0] ""  Vector__XXX

CM_ BO_ 287 "[PE] Periodic and On Event";
CM_ SG_ 287 APSS_LumbarUpSw "APSS_LumbarUpMoveSwitch";
CM_ SG_ 287 APSS_LumbarMidSw "APSS_LumbarMiddleSwitch";
CM_ SG_ 287 APSS_LumbarLowSw "APSS_LumbarLowerSwitch";
CM_ SG_ 287 APSS_LumbarDefSw "APSS_LumbarDeflationSwitch";
CM_ SG_ 287 APSS_BolsterInfSw "APSS_BolsterInflationSwitch";
CM_ SG_ 287 APSS_BolsterDefSw "APSS_BolsterDeflationSwitch";
CM_ SG_ 287 APSS_ActiveSw "APSS_ActiveSwitch";
CM_ SG_ 287 APSS_CushInfSw "APSS_Cush Support Inflation Switch";
CM_ SG_ 287 APSS_CushDefSw "APSS_Cush Support Deflation Switch";
CM_ SG_ 287 APSS_CushOnOffTch "APSS_CushOnOffTouch";
CM_ BO_ 271 "[PE] Periodic and On Event";
CM_ SG_ 271 ASAU_AirSptTimeRValueSet "Air Support Time(Massage Time) USM R Value";
CM_ SG_ 271 ASAU_AstSmtAirSptRValueSet "Seat Smart Air Support Function USM R Value";
CM_ SG_ 271 ASAU_CushSoftRValueSet "Cushion Soft R Value";
CM_ SG_ 271 ASAU_BackSoftRValueSet "Back Soft USM R Value";
CM_ SG_ 271 ASAU_AirSptModeRValueSet "Air Support Mode(Massage Mode) USM R Value";
CM_ SG_ 271 ASAU_NotFootMsgOperStaWarnPE "Passenger Foot Massage Operation Disable Mode";
CM_ SG_ 271 ASAU_RRFootAirSptRValueSet "Foot Air Support USM R Value";
CM_ SG_ 271 ASAU_RRFootAirSptHeatRValueSet "Foot Air Support Heat USM R Value";
CM_ SG_ 271 ASAU_MoodTrpyRValueSet "Passenger Seat Mood Therapy R Value";
CM_ SG_ 271 ASAU_MoodTrpyCareSta "Passenger Seat Mood Therapy Care Mode R Value";
CM_ SG_ 271 ASAU_MoodTrpyComfSta "Passenger Seat Mood Therapy Comfort Mode R Value";
CM_ SG_ 271 ASAU_AirSptStrRValueSet "Air Support Strenth(Massage Strenth) USM R Value";
CM_ BO_ 733 "[PE] Periodic and On Event";
CM_ SG_ 733 CMS_LH_Crc1Val "CMS_LH_CyclicRedundancyCheck1Value";
CM_ SG_ 733 CMS_LH_AlvCnt1Val "CMS_LH_AliveCounter1Value";
CM_ SG_ 733 CMS_LHVerPosVal "LH Outside Mirror Vertical Position sensor value";
CM_ SG_ 733 CMS_LHHorPosVal "LH Outside Mirror Horizontal Position Sensor Voltage";
CM_ SG_ 733 Monitor_ViewPanningCmd "Monitor_ViewPanningCommand";
CM_ BO_ 2395189761 "[PE] Periodic and On Event";
CM_ SG_ 2395189761 DATC_Crc10Val "DATC_CyclicRedundancyCheck10Value";
CM_ SG_ 2395189761 DATC_AlvCnt10Val "DATC_AliveCounter10Value";
CM_ SG_ 2395189761 DATC_Typ "DATC_Type";
CM_ SG_ 2395189761 DATC_Opt1Typ "DATC_Option1Type";
CM_ SG_ 2395189761 DATC_Opt3Typ "DATC_Option3Type";
CM_ SG_ 2395189761 DATC_Opt2Typ "DATC_Option2Type";
CM_ SG_ 2395189761 DATC_Opt4Typ "HTR CONTROL OPTION";
CM_ SG_ 2395189761 DATC_TxtPopupReq "DATC_TextPopupReq";
CM_ SG_ 2395189761 DATC_StrWhlUSMSta "DATC_SteeringWheelUSMState";
CM_ SG_ 2395189761 DATC_StrWhlHtngReq "DATC_SteeringWheelHeatReq";
CM_ BO_ 1882 "[TP] Transport Protocol";
CM_ BO_ 1881 "[TP] Transport Protocol";
CM_ BO_ 2193667329 "[P] Periodic";
CM_ SG_ 2193667329 EMS_Crc1Val "EMS_CyclicRedundancyCheck1Value";
CM_ SG_ 2193667329 EMS_AlvCnt1Val "EMS_AliveCounter1Value";
CM_ SG_ 2193667329 ENG_CrctEngTqVal "ENG_CorrectedEngineTorqueValue ##2G##EMS - EMS11 - TQI_ACOR";
CM_ SG_ 2193667329 ENG_StndTqRatioVal "ENG_StandardTorqueRatioValue ##2G##EMS - EMS11 - RATIO_TQI_BAS_MAX_STND";
CM_ SG_ 2193667329 ENG_FrctTqVal "ENG_FrictionTorqueValue ##2G##EMS - EMS11 - TQFR";
CM_ BO_ 2193667330 "[P] Periodic";
CM_ SG_ 2193667330 ENG_IndTqVal "ENG_IndicatedTorqueValue ##2G##EMS - EMS11 - TQI";
CM_ SG_ 2193667330 ENG_IndTqBVal "ENG_IndicatedTorqueBValue ##2G##EMS - EMS_H12 - TQI_B";
CM_ SG_ 2193667330 ENG_EngSpdErrSta "ENG_EngineSpeedErrorStatus ##2G##EMS - EMS11 - F_N_ENG";
CM_ SG_ 2193667330 ENG_MafErrSta "ENG_MassAirFlowErrorStatus ##2G##EMS - EMS11 - F_SUB_TQI";
CM_ SG_ 2193667330 ENG_EtcLmphModSta "ENG_EtcLimphomeModeStatus ##2G##EMS - EMS_H12 - CF_Ems_EtcLimpMod";
CM_ SG_ 2193667330 ENG_SpltInjctnSta "ENG_SplitInjectionStatus";
CM_ SG_ 2193667330 ENG_MaxAirconTqVal "ENG_MaximumAirconTorqueValue ##2G##EMS - EMS_H12 - R_TqAcnApvC";
CM_ SG_ 2193667330 ENG_AirconPrsrSnsrVal "ENG_AirconPressureSensorValue ##2G##EMS - EMS_H12 - R_PAcnC";
CM_ SG_ 2193667330 ENG_IsgSta "ENG_IsgStatus ##2G##EMS - EMS_H12 - CF_Ems_IsgStat";
CM_ SG_ 2193667330 ENG_OilLvlSta "ENG_OilLevelStatus ##2G##EMS - EMS_H12 - CF_Ems_OilChg";
CM_ BO_ 2193667331 "[P] Periodic";
CM_ SG_ 2193667331 ENG_TrgtIdleRpmVal "ENG_TargetIdleRpmValue ##2G##EMS - EMS_H12 - R_NEngIdlTgC";
CM_ SG_ 2193667331 ENG_GearShftDnDis "ENG_GearShiftDownDisplay ##2G##EMS - EMS_H12 - CF_Ems_DownTarGr";
CM_ SG_ 2193667331 ENG_DsrGearPosDis "ENG_DesirableGearPositionDisplay ##2G##EMS - EMS_H12 - CF_Ems_DesCurGr";
CM_ SG_ 2193667331 ENG_SldFuncSta "ENG_SpeedLimitFunctionStatus ##2G##EMS - EMS_H12 - CF_Ems_SldAct";
CM_ SG_ 2193667331 ENG_SldActnSta "ENG_SpeedLimitActionStatus ##2G##EMS - EMS_H12 - CF_Ems_SldPosAct";
CM_ SG_ 2193667331 ENG_FuelTnkPrsrSta "ENG_FuelTankPressureStatus ##2G##EMS - EMS_H12 - CF_Ems_HPresStat";
CM_ SG_ 2193667331 ENG_IsgBzrReq "ENG_IsgBuzzerRequest ##2G##EMS - EMS_H12 - CF_Ems_IsgBuz";
CM_ SG_ 2193667331 ENG_IsgFuelCnsmptDis "ENG_IsgFuelConsumptionDisplay ##2G##EMS - EMS_H12 - CF_Ems_IdlStpFCO";
CM_ SG_ 2193667331 ENG_FuelCapOpnSta "ENG_FuelCapOpenStatus ##2G##EMS - EMS_H12 - CF_Ems_FCopen";
CM_ SG_ 2193667331 ENG_EcoDrvActvSta "ENG_EcoDriveActiveStatus ##2G##EMS - EMS_H12 - CF_Ems_ActEcoAct";
CM_ SG_ 2193667331 ENG_EngRunSta "ENG_EngineRunningStatus ##2G##EMS - EMS_H12 - CF_Ems_EngRunNorm";
CM_ SG_ 2193667331 ENG_Isg2Sta "ENG_Isg2Status ##2G##EMS - EMS_H12 - CF_Ems_IsgStat2";
CM_ SG_ 2193667331 ENG_IgnOnSta "ENG_IgnitionOnStatus ##2G##EMS - EMS11 - SWI_IGK";
CM_ SG_ 2193667331 ENG_Ack4TcsSta "ENG_AcknowledgeForTcsStatus ##2G##EMS - EMS11 - ACK_TCS";
CM_ SG_ 2193667331 ENG_FuelCutOffSta "ENG_FuelCutOffStatus ##2G##EMS - EMS11 - PUC_STAT";
CM_ SG_ 2193667331 ENG_CrctTqSta "ENG_CorrectedTorqueStatus ##2G##EMS - EMS11 - TQ_COR_STAT";
CM_ SG_ 2193667331 ENG_AirCompRlySta "ENG_AirCompressorRelayStatus ##2G##EMS - EMS11 - RLY_AC";
CM_ SG_ 2193667331 ENG_LnchCntrlSta "ENG_LaunchControlStatus";
CM_ SG_ 2193667331 ENG_EngSpdVal "ENG_EngineSpeedValue ##2G##EMS - EMS11 - N";
CM_ SG_ 2193667331 ENG_GearShftUpDis "ENG_GearShiftUpDisplay ##2G##EMS - EMS_H12 - CF_Ems_UpTarGr";
CM_ BO_ 2193667332 "[P] Periodic";
CM_ SG_ 2193667332 ENG_TrgtFuelPmpPrsrVal "ENG_TargetFuelPumpPressureValue ##2G##EMS - EMS20 - CF_Ems_PumpTPres";
CM_ SG_ 2193667332 ENG_VehSpdHiVal "ENG_VehicleSpeedHighValue";
CM_ SG_ 2193667332 ENG_EngInhbNCC "This signal indicates the Inhibition of NCC MODE";
CM_ SG_ 2193667332 ENG_SldSwSta "The status of Speed limiter function.";
CM_ SG_ 2193667332 ENG_SldDrvAlertDisp "The status of No Sld Engaged or Sld Disengaged.";
CM_ SG_ 2193667332 ENG_VehSpdLimVal "ENG_VehicleSpeedLimitValue ##2G##EMS - EMS_H12 - SLD_VS, EMS20-SLD_VS_EXT";
CM_ SG_ 2193667332 ENG_FuelCnsmptVal "ENG_FuelConsumptionValue ##2G##EMS - EMS20 - FCO";
CM_ BO_ 2214659329 "[P] Periodic";
CM_ SG_ 2214659329 EMS_Crc7Val "EMS_CyclicRedundancyCheck7Value";
CM_ SG_ 2214659329 EMS_AlvCnt7Val "EMS_AliveCounter7Value";
CM_ SG_ 2214659329 HEV_IndTqVal "HEV_IndicatedTorqueValue";
CM_ SG_ 2214659329 HEV_DrvTqVal "HEV_DriverTorqueValue";
CM_ SG_ 2214659329 HEV_TqStndVal "HEV_TorqueStandardValue";
CM_ BO_ 2214659330 "[P] Periodic";
CM_ SG_ 2214659330 HEV_FrctTqVal "HEV_FrictionTorqueValue";
CM_ SG_ 2214659330 HEV_EngSpdVal "HEV_EngineSpeedValue";
CM_ SG_ 2214659330 HEV_EngOpSta "HEV_EngineOperatingStatus";
CM_ SG_ 2214659330 HEV_IntakeAirTempVal "HEV_IntakeAirTemperatureValue";
CM_ SG_ 2214659330 HEV_AccelPdlVal "HEV_AcceleratorPedalValue";
CM_ SG_ 2214659330 HEV_IndTqTar "HEV_IndicatedTorqueTarget";
CM_ BO_ 2214659331 "[P] Periodic";
CM_ BO_ 2214659332 "[P] Periodic";
CM_ BO_ 2307024129 "[P] Periodic";
CM_ SG_ 2307024129 EMS_Crc8Val "EMS_CyclicRedundancyCheck8Value";
CM_ SG_ 2307024129 EMS_AlvCnt8Val "EMS_AliveCounter8Value";
CM_ SG_ 2307024129 HEV_EngClntTempVal "HEV_EngineCoolantTemperatureValue";
CM_ SG_ 2307024129 HEV_EngOilTempVal "HEV_EngineOilTemperatureValue";
CM_ SG_ 2307024129 HEV_VbOffActSta "HEV_VbOffActStatus";
CM_ SG_ 2307024129 HEV_AirCompOffReq "HEV_AirCompressorOffRequest";
CM_ SG_ 2307024129 HEV_MilConfgVal "HEV_MilConfigurationValue";
CM_ SG_ 2307024129 HEV_CF_EMS_LOCKUP "Engine lock up mainentance request state";
CM_ SG_ 2307024129 HEV_OilLvlSta "HEV_OilLevelStatus";
CM_ SG_ 2307024129 HEV_ImmoLmpReq "HEV_ImmobilizerLampRequest";
CM_ SG_ 2307024129 HEV_MilReq "HEV_MalfunctionIndicationLampRequest";
CM_ SG_ 2307024129 HEV_WiperSwSta "HEV_WiperSwitchStatus";
CM_ SG_ 2307024129 HEV_FanOpSta "HEV_CoolingFanOperatingStatus";
CM_ SG_ 2307024129 HEV_FanSta "HEV_CoolingFanStatus";
CM_ SG_ 2307024129 HEV_BrkLtSwSta "HEV_BrakeLightSwitchStatus";
CM_ BO_ 2307024130 "[P] Periodic";
CM_ SG_ 2307024130 HEV_IgnCycCntVal "HEV_IgnitionCycleCounterValue";
CM_ SG_ 2307024130 HEV_SoakTimeVal "HEV_SoakTimeValue";
CM_ SG_ 2307024130 HEV_SoakTimeErrSta "HEV_SoakTimeErrorStatus";
CM_ SG_ 2307024130 HEV_SoakTimeOvrSta "HEV_SoakTimeOverStatus";
CM_ SG_ 2307024130 HEV_FuelRunOutSta "HEV_FuelRunOutStatus";
CM_ SG_ 2307024130 HEV_FuelRunOutDetSta "HEV_FuelRunOutDetectStatus";
CM_ SG_ 2307024130 HEV_FuelCnsmptSumVal "HEV_FuelConsumptionSumValue";
CM_ BO_ 2307024131 "[P] Periodic";
CM_ SG_ 2307024131 HEV_EstClntTempVal "HEV_EstimatedCoolantTemperatureValue";
CM_ SG_ 2307024131 HEV_EstAmbtAirTempVal "HEV_EstimatedAmbientAirTemperatureValue";
CM_ SG_ 2307024131 HEV_RbmSta "HEV_RateBasedMonitoringStatus";
CM_ SG_ 2307024131 HEV_WarmUpReq_For_DATC "HEV_WarmUpRequest";
CM_ SG_ 2307024131 HEV_RbmInhbtSta "HEV_RbmInhibitionStatus";
CM_ SG_ 2307024131 HEV_EhrsTempSta "HEV_EhrsTemperatureStatus";
CM_ SG_ 2307024131 HEV_Aaf_WrnLamp "Air Flap Warning Lamp/Message Request Signal indicates whether Warning Lamp/Message should be displayed in the display screen in order to warn AAF System failure to customer.";
CM_ SG_ 2307024131 HEV_OPSFail "Oil Pressure Warning Lamp Status";
CM_ SG_ 2307024131 HEV_EngDsplceTyp "HEV_EngineDisplacementType ##2G##EMS - EMS12 - ENG_VOL";
CM_ SG_ 2307024131 HEV_EngTyp2 "HEV_EngineType2 ##2G##EMS - EMS23 - ENG_TYPE";
CM_ SG_ 2307024131 HEV_EngTyp1 "HEV_EngineType1 ##2G##EMS - EMS12 - ENG_CHR";
CM_ SG_ 2307024131 HEV_S_F "AMS/ISG system type indicator";
CM_ SG_ 2307024131 HEV_S_F_GEN "system generation type indicator";
CM_ SG_ 2307024131 HEV_AptVal "HEV_AptValue";
CM_ BO_ 2307024132 "[P] Periodic";
CM_ SG_ 2307024132 HEV_RbmSta_2nd "HEV_RateBasedMonitoringStatus";
CM_ SG_ 2307024132 HEV_OilLifeRatio "Remaining engine oil life with % unit";
CM_ SG_ 2307024132 HEV_OilLifeEna "Enabling information if engine oil life monitoring from EMS is applied or not";
CM_ SG_ 2307024132 HEV_OilLifeWarn "Request to activate engine oil life warning";
CM_ SG_ 2307024132 HEV_RECTrigSta "VCRM trigger bit by REC";
CM_ SG_ 2307024132 HEV_PendingTrigSta "VCRM trigger bit by pending DTC";
CM_ BO_ 2244048129 "[P] Periodic";
CM_ SG_ 2244048129 ESC_Crc3Val "ESC_CyclicRedundancyCheck3Value";
CM_ SG_ 2244048129 ESC_AlvCnt3Val "ESC_AliveCounter3Value";
CM_ SG_ 2244048129 SCC_TqIntrvntnVal "SCC_TorqueInterventionValue ##2G##ESC - TCS13 - TQI_ACC";
CM_ SG_ 2244048129 ESC_VehAccelVal "ESC_VehicleAccelerationValue ##2G##ESC - TCS13 - ACCEL_REF_ACC";
CM_ SG_ 2244048129 ESC_AccelBasisVal "ESC_AccelerationBasisValue ##2G##ESC - TCS13 - aBasis";
CM_ BO_ 2244048130 "[P] Periodic";
CM_ SG_ 2244048130 SCC_OptTyp "SCC_OptionType ##2G##ESC - TCS13 - ACC_EQUIP";
CM_ SG_ 2244048130 ESC_BrkLtReq "ESC_BrakeLightRequest ##2G##ESC - TCS13 - BrakeLight";
CM_ SG_ 2244048130 ESC_DclEnblReq "ESC_DecelerationEnableRequest ##2G##ESC - TCS13 - DCEnable";
CM_ SG_ 2244048130 ESC_DrvOvrdSta "ESC_OverrideRequest ##2G##ESC - TCS13 - DriverOverride";
CM_ SG_ 2244048130 ESC_DrvBrkSta "ESC_DriverBrakingStatus ##2G##ESC - TCS13 - CF_DriBkeStat";
CM_ SG_ 2244048130 SCC_EnblReq "SCC_EnableRequest ##2G##ESC - TCS13 - ACCEnable";
CM_ SG_ 2244048130 ESC_DrvBrkActvSta "ESC_DriverBrakingActiveStatus ##2G##ESC - TCS13 - DriverBraking";
CM_ SG_ 2244048130 ESC_PrkBrkActvSta "ESC_ParkingBrakeActiveStatus ##2G##ESC - TCS13 - PBRAKE_ACT";
CM_ SG_ 2244048130 ESC_HDP_FltMonSta "ESC_HDP_FaultStatus";
CM_ SG_ 2244048130 FCA_EquipSta "FCA_EquipmentStatus ##2G##ESC - TCS13 - FCA_EQUIP";
CM_ SG_ 2244048130 FCA_AvlblSta "VSM_AvailableStatus ##2G##ESC - TCS13 - CF_VSM_Avail";
CM_ SG_ 2244048130 ESC_FCA_ActvSta "Status of control for FCA control request flag";
CM_ SG_ 2244048130 ESC_DBS_ActvSta "ESC_DBS_ActvSta ##2G## ESC - TCS11 - DBS_ACK";
CM_ SG_ 2244048130 SCC_TqReq "SCC_TorqueRequest ##2G##ESC - TCS13 - ACC_REQ";
CM_ SG_ 2244048130 ESC_HDP_EgSta "ESC_HDP_EngagedStatus";
CM_ SG_ 2244048130 ESC_HDP_EnblReq "ESC_HDP_EnableRequest";
CM_ SG_ 2244048130 ESC_BrkdFltStndstill "Detect Indication of braked, flatland and standstill state";
CM_ SG_ 2244048130 SCC_ReqLimSta "SCC_RequestLimitedStatus ##2G##ESC - TCS13 - ACCReqLim";
CM_ SG_ 2244048130 ESC_StdStillVal "ESC_StandStillValue ##2G##ESC - TCS13 - StandStill";
CM_ BO_ 2244048131 "[P] Periodic";
CM_ SG_ 2244048131 ESC_RccaSta "ESC_RccaStatus ##2G##ESC - ESP11 - ESP_RCCA_STAT";
CM_ SG_ 2244048131 ESC_RspaCanFlFlag "##2G##ESC - ESP11 - ESC_RspaCanfailflag";
CM_ SG_ 2244048131 ESC_RspaDclActv "##2G##ESC - ESP11 - ESC_RSPA_DEC_ACT";
CM_ SG_ 2244048131 ESC_RspaStandStill "##2G##ESC - ESP11 - ESC_RSPA_STANDSTILL";
CM_ SG_ 2244048131 ESC_PcaSta "ESC_PcaStatus";
CM_ SG_ 2244048131 MCB_ReqBrkAck "Acknowledge Status for MCB Brake Request";
CM_ SG_ 2244048131 MCB_CtlSta "Status for MCB Activation";
CM_ SG_ 2244048131 MCB_DefSta "Status for MCB defect";
CM_ SG_ 2244048131 ESC_DiffBrkFuncSta "ESC_DifferentialBrakeFunctionStatus ##2G##ESC - TCS13 - DF_BF_STAT";
CM_ SG_ 2244048131 ESC_LsdLimMod "eLSD torque limit mode ##2G##ESC - ESP_LSD11 - LSD_LIM_MODE";
CM_ SG_ 2244048131 ESC_LsdOpn "eLSD clutch open mode ##2G##ESC - ESP_LSD11 - LSD_OPEN";
CM_ SG_ 2244048131 ESC_LsdTqLim "value of the torquel limit of eLSD ##2G##ESC - ESP_LSD11 - LSD_TQC_LIM";
CM_ SG_ 2244048131 ESC_BcaRPlusSta "ESC_BcaRPlusStatus";
CM_ SG_ 2244048131 ESC_RspaSta "ESC_RspaStatus ##2G##ESC - ESP11 - ESP_RSPA_STAT";
CM_ BO_ 721 "[P] Periodic";
CM_ SG_ 721 HU_DR_Position_Status "DR Position status";
CM_ SG_ 721 HU_DR_Altitude_Status "DR Altitude Status";
CM_ SG_ 721 HU_DR_Altitude "range [-400,10000]";
CM_ SG_ 721 HU_DR_Heading_Status "DR Heading Status";
CM_ SG_ 721 HU_DR_Speed_Status "DR Speed status";
CM_ SG_ 721 HU_DR_DirectionSwitch_Sta "DR DirectionSwitch Status";
CM_ SG_ 721 HU_DR_Direction "DR Direction, Backward";
CM_ SG_ 721 HU_DR_GyroCalib_Sta "DR Gyro Calibration Status";
CM_ SG_ 721 HU_DR_TachoCalib_Sta "DR Tacho Calibration Status";
CM_ SG_ 721 HU_DR_GNSS_Fix_Age "Time since last GNSS fix";
CM_ BO_ 722 "[P] Periodic";
CM_ SG_ 722 HU_DR_Latitude "1sc(semi-cicle)= pi rad=180  /   unit : 2^-31sc  /  range [-1/2~1/2] sc";
CM_ SG_ 722 HU_DR_Longitude "1sc(semi-circle)=pi rad=180 / unit:2^-31sc / range:[-1, 1]sc";
CM_ BO_ 723 "[P] Periodic";
CM_ SG_ 723 HU_DR_Heading "1sc(semi-circle)=pi rad=180 / unit=2^-15sc / range:[0,2]SC";
CM_ SG_ 723 HU_DR_Speed "unit : 1cm/s";
CM_ BO_ 2164277249 "[P] Periodic";
CM_ SG_ 2164277249 TCU_Crc1Val "TCU_CyclicRedundancyCheck1Value";
CM_ SG_ 2164277249 TCU_AlvCnt1Val "TCU_AliveCounter1Value";
CM_ SG_ 2164277249 TCU_GearSlctDis "TCU_GearSelectDisplay";
CM_ SG_ 2164277249 TCU_Typ "TCU_Type";
CM_ SG_ 2164277249 TCU_TqRdctnVal "TCU_TorqueReductionValue";
CM_ SG_ 2164277249 TCU_GearStepTyp "TCU_GearStepType";
CM_ SG_ 2164277249 TCU_GearShftSta "TCU_GearShiftStatus";
CM_ SG_ 2164277249 TCU_TqCnvrtrSta "TCU_TorqueConverterStatus";
CM_ BO_ 2164277250 "[P] Periodic";
CM_ SG_ 2164277250 TCU_CurrGearSta "TCU_CurrentGearStatus";
CM_ SG_ 2164277250 TCH_EngTrgtGearSta "TCU_EngineTargetGear";
CM_ SG_ 2164277250 TCU_EngTqLimVal "TCU_EngineTorqueLimitValue";
CM_ SG_ 2164277250 TCU_CluTrgtGearConfg "Signal source Configuration of  Target gear for CLU";
CM_ SG_ 2164277250 TCU_VehSpdKphVal "TCU_VehicleSpeedKphValue";
CM_ SG_ 2164277250 TCU_TrgtGearSta "TCU_TargetGearStatus";
CM_ SG_ 2164277250 TCU_DcmlVehSpdKphVal "TCU_VehicleSpeedDecimalKphValue";
CM_ SG_ 2164277250 TCU_SprkRtrdReq "TCU_SparkRetardAngleValue";
CM_ SG_ 2164277250 TCU_EngRpmDisSta "TCU_EngineRpmDisplayStatus";
CM_ SG_ 2164277250 TCU_GearLmpBlnkngReq "TCU_GearLampBlinkingRequest";
CM_ SG_ 2164277250 TCU_FuelCutInhbtReq "TCU_FuelCutInhibitionRequest";
CM_ SG_ 2164277250 TCU_IdleUpReq "TCU_IdleUpRequest";
CM_ SG_ 2164277250 TCU_CluTrgtGearSta "TCU_ClusterTargetGear";
CM_ BO_ 2164277251 "[P] Periodic";
CM_ SG_ 2164277251 TCU_EngRpmDis "TCU_EngineRpmDisplay";
CM_ SG_ 2164277251 TCU_SlpVal "TCU_SlopeValue";
CM_ SG_ 2164277251 TCU_EngSpdIncReq "TCU_EngineSpeedIncreaseRequest";
CM_ SG_ 2164277251 TCU_ObdSta "TCU_ObdStatus";
CM_ SG_ 2164277251 TCU_SprtyIndxSta "TCU_SportyIndexStatus";
CM_ SG_ 2164277251 TCU_DrvngModDis "TCU_DrivingModeDisplay";
CM_ SG_ 2164277251 TCU_DrvngModReq "TCU_DrivingModeRequest";
CM_ SG_ 2164277251 TCU_SmrtShftSta "TCU_SmartShiftStatus";
CM_ SG_ 2164277251 TCU_LupTrgtEngSpdVal "TCU_LupTargetEngineSpeedValue";
CM_ SG_ 2164277251 TCU_FrtStcShftSta "TCU_FirstStaticShiftStatus";
CM_ SG_ 2164277251 TCU_IsgInhbtReq "TCU_IsgInhibitRequest";
CM_ SG_ 2164277251 TCU_CdaInhbtReq "TCU_CdaInhibitRequest";
CM_ SG_ 2164277251 TCU_BrkOnReq "TCU_BrakeOnRequest";
CM_ SG_ 2164277251 TCU_TqGrdntLimVal "TCU_TorqueGradientLimitationValue";
CM_ BO_ 2164277252 "[P] Periodic";
CM_ SG_ 2164277252 TCU_NetrlCtrlSta "TCU_NeutralControlStatus";
CM_ SG_ 2164277252 TCU_ShftPtrnSta "TCU_ShiftPatternStatus";
CM_ SG_ 2164277252 TCU_EPBReq "EPB Request signal for prevent P-D Shock on hill";
CM_ SG_ 2164277252 IMT_EOLstate "Gear Display for EOL mode to cluster. This signal is for IMT system only.";
CM_ SG_ 2164277252 IMT_DisCmd "Gear Display type command to cluster . this signal is for IMT system only.";
CM_ SG_ 2164277252 IMT_CltchPdlPos "Clutch Pedal Position. This signal is for IMT system only.";
CM_ SG_ 2164277252 DCT_RegenInhbt "The regen inhibit request from TCU";
CM_ SG_ 2164277252 DCT_EngIdleReq "Engine Idle Request";
CM_ SG_ 2164277252 DCT_CltchState "DCT clutch status";
CM_ SG_ 2164277252 DCT_FuelCutReq "TCU require ECU to perform ¡®Fuel Cut¡¯";
CM_ SG_ 2164277252 DCT_TqIncReq "Request for Torque Increase";
CM_ SG_ 2164277252 DCT_CrpTqReq "Pre-control torque for creeping";
CM_ SG_ 2164277252 DCT_ShftTqReq "Pre-control torque for shifting";
CM_ SG_ 2164277252 TCU_VgisInhbtReq "TCU_VgisInhibitionRequest";
CM_ SG_ 2164277252 TCU_EngTqIncReqVal "TCU_EngineTorqueIncreaseReqValue";
CM_ BO_ 2189467649 "[P] Periodic";
CM_ SG_ 2189467649 WHL_Crc1Val "WHL_CyclicRedundancyCheck1Value";
CM_ SG_ 2189467649 WHL_AlvCnt1Val "WHL_AliveCounter1Value";
CM_ SG_ 2189467649 WHL_PlsFLVal "WHL_PulseFrontLeftValue ##2G##ESC - WHL_PUL11 - WHL_PUL_FL";
CM_ SG_ 2189467649 WHL_PlsFRVal "WHL_PulseFrontRightValue ##2G##ESC - WHL_PUL11 - WHL_PUL_FR";
CM_ SG_ 2189467649 WHL_PlsRLVal "WHL_PulseRearLeftValue ##2G##ESC - WHL_PUL11 - WHL_PUL_RL";
CM_ SG_ 2189467649 WHL_PlsRRVal "WHL_PulseRearRightValue ##2G##ESC - WHL_PUL11 - WHL_PUL_RR";
CM_ SG_ 2189467649 WHL_DirFLVal "WHL_DirectionFrontLeftValue ##2G##ESC - WHL_PUL11 - WHL_DIR_FL";
CM_ SG_ 2189467649 WHL_DirFRVal "WHL_DirectionFrontRightValue ##2G##ESC - WHL_PUL11 - WHL_DIR_FR";
CM_ SG_ 2189467649 WHL_DirRLVal "WHL_DirectionRearLeftValue ##2G##ESC - WHL_PUL11 - WHL_DIR_RL";
CM_ SG_ 2189467649 WHL_DirRRVal "WHL_DirectionRearRightValue ##2G##ESC - WHL_PUL11 - WHL_DIR_RR";
CM_ BO_ 2189467650 "[P] Periodic";
CM_ SG_ 2189467650 WHL_SpdFLVal "WHL_SpeedFrontLeftValue ##2G##ESC - WHL_SPD11 - WHL_SPD_FL";
CM_ SG_ 2189467650 WHL_SpdFRVal "WHL_SpeedFrontRightValue ##2G##ESC - WHL_SPD11 - WHL_SPD_FR";
CM_ SG_ 2189467650 WHL_SpdRLVal "WHL_SpeedRearLeftValue ##2G##ESC - WHL_SPD11 - WHL_SPD_RL";
CM_ SG_ 2189467650 WHL_SpdRRVal "WHL_SpeedRearRightValue ##2G##ESC - WHL_SPD11 - WHL_SPD_RR";
CM_ BO_ 2189467651 "[P] Periodic";
CM_ SG_ 2189467651 WHL_SpdCalParmtr "WHL_SpeedCalculationParameter";
BA_DEF_ BO_ "DiagState" ENUM "No","Yes" ;
BA_DEF_ BO_ "DiagResponse" ENUM "No","Yes" ;
BA_DEF_ BO_ "DiagRequest" ENUM "No","Yes" ;
BA_DEF_ BO_ "TpMessage" ENUM "No","Yes" ;
BA_DEF_ BO_ "UsrMsgIDSforwardDeviation" INT 0 100 ;
BA_DEF_ BO_ "UsrMsgIDSbackwardDeviation" INT 50 1000 ;
BA_DEF_ BO_ "GenMsgCycleTime" INT 0 2000 ;
BA_DEF_ BO_ "GenMsgStartDelayTime" INT 0 2000 ;
BA_DEF_ BO_ "GenMsgSendType" ENUM "Cyclic","NoMsgSendType" ;
BA_DEF_ BO_ "GenMsgCycleTimeFast" INT 0 500 ;
BA_DEF_ BO_ "GenMsgDelayTime" INT 0 20 ;
BA_DEF_ BO_ "GenMsgILSupport" ENUM "No","Yes" ;
BA_DEF_ BO_ "GenMsgNrOfRepetition" INT 0 3 ;
BA_DEF_ BO_ "NmMessage" ENUM "No","Yes" ;
BA_DEF_ BO_ "NWM-Botschaft" ENUM "No","Yes" ;
BA_DEF_ BO_ "TpTxIndex" INT 0 255 ;
BA_DEF_ BO_ "VFrameFormat" ENUM "StandardCAN","ExtendedCAN","reserved","reserved","reserved","reserved","reserved","reserved","reserved","reserved","reserved","reserved","reserved","reserved","StandardCAN_FD","ExtendedCAN_FD" ;
BA_DEF_ SG_ "UserSigValidity" ENUM "B+","ACC","IG","IG1","IG2","IG3","IG1 or IG2","IG1 or IG3","Undef" ;
BA_DEF_ SG_ "TimeoutValue" STRING ;
BA_DEF_ SG_ "UsrSigPurpose" ENUM "Undef","FN","DIAG","DIAG(Req)","DIAG(Res)","DIAG(Phy)","DEV","CCP(Req)","CCP(Res)","NM","TP" ;
BA_DEF_ SG_ "GenSigStartValue" INT 0 1215752192 ;
BA_DEF_ SG_ "NetworkRequest" ENUM "Yes","No" ;
BA_DEF_ SG_ "NetworkRequestHoldingTime" INT 0 65535 ;
BA_DEF_ SG_ "Description" STRING ;
BA_DEF_ SG_ "Version" STRING ;
BA_DEF_ SG_ "GenSigEnvVarType" ENUM "Int","Float","Undef" ;
BA_DEF_ SG_ "GenSigSendType" ENUM "Cyclic","OnWrite","OnWriteWithRepetition","OnChange","OnChangeWithRepetition","IfActive","IfActiveWithRepetition","NoSigSendType","OnChangeAndIfActive","OnChangeAndIfActiveWithRepetition" ;
BA_DEF_ SG_ "GwSigLatencyTime" INT 0 65536 ;
BA_DEF_ SG_ "GwSigMissingSourceType" ENUM "Undef","OldValue","DefaultValue","InitialValue" ;
BA_DEF_ SG_ "NWM-WakeupAllowed" ENUM "<n.a.>" ;
BA_DEF_ SG_ "RoutingFactor" INT 1 1215752192 ;
BA_DEF_REL_ BU_SG_REL_ "GenSigTimeoutTime" INT 0 7000 ;
BA_DEF_DEF_ "DiagState" "No" ;
BA_DEF_DEF_ "DiagResponse" "No" ;
BA_DEF_DEF_ "DiagRequest" "No" ;
BA_DEF_DEF_ "TpMessage" "No" ;
BA_DEF_DEF_ "UsrMsgIDSforwardDeviation" 10 ;
BA_DEF_DEF_ "UsrMsgIDSbackwardDeviation" 100 ;
BA_DEF_DEF_ "GenMsgCycleTime" 200 ;
BA_DEF_DEF_ "GenMsgStartDelayTime" 0 ;
BA_DEF_DEF_ "GenMsgSendType" "NoMsgSendType" ;
BA_DEF_DEF_ "GenMsgCycleTimeFast" 40 ;
BA_DEF_DEF_ "GenMsgDelayTime" 20 ;
BA_DEF_DEF_ "GenMsgILSupport" "Yes" ;
BA_DEF_DEF_ "GenMsgNrOfRepetition" 3 ;
BA_DEF_DEF_ "NmMessage" "No" ;
BA_DEF_DEF_ "NWM-Botschaft" "No" ;
BA_DEF_DEF_ "TpTxIndex" 0 ;
BA_DEF_DEF_ "VFrameFormat" "StandardCAN" ;
BA_DEF_DEF_ "UserSigValidity" "IG" ;
BA_DEF_DEF_ "TimeoutValue" "" ;
BA_DEF_DEF_ "UsrSigPurpose" "FN" ;
BA_DEF_DEF_ "GenSigStartValue" 0 ;
BA_DEF_DEF_ "NetworkRequest" "No" ;
BA_DEF_DEF_ "NetworkRequestHoldingTime" 0 ;
BA_DEF_DEF_ "Description" "" ;
BA_DEF_DEF_ "Version" "" ;
BA_DEF_DEF_ "GenSigEnvVarType" "Undef" ;
BA_DEF_DEF_ "GenSigSendType" "NoSigSendType" ;
BA_DEF_DEF_ "GwSigLatencyTime" 40 ;
BA_DEF_DEF_ "GwSigMissingSourceType" "Undef" ;
BA_DEF_DEF_ "NWM-WakeupAllowed" "<n.a.>" ;
BA_DEF_DEF_ "RoutingFactor" 1 ;
BA_DEF_DEF_REL_ "GenSigTimeoutTime" 500 ;
BA_ "GenMsgSendType" BO_ 287 0;
BA_ "Description" SG_ 287 APSS_LumbarUpSw "APSS_LumbarUpMoveSwitch";
BA_ "GenSigSendType" SG_ 287 APSS_LumbarUpSw 4;
BA_ "UserSigValidity" SG_ 287 APSS_LumbarUpSw 0;
BA_REL_ "GenSigTimeoutTime" BU_SG_REL_ ALBCU SG_ 287 APSS_LumbarUpSw 1500;
BA_REL_ "GenSigTimeoutTime" BU_SG_REL_ CGW_CCU SG_ 287 APSS_LumbarUpSw 1500;
BA_ "NetworkRequest" SG_ 287 APSS_LumbarUpSw 0;
BA_ "NetworkRequestHoldingTime" SG_ 287 APSS_LumbarUpSw 5000;
BA_ "Version" SG_ 287 APSS_LumbarUpSw "19.11.06";
BA_ "Description" SG_ 287 APSS_LumbarMidSw "APSS_LumbarMiddleSwitch";
BA_ "GenSigSendType" SG_ 287 APSS_LumbarMidSw 4;
BA_ "UserSigValidity" SG_ 287 APSS_LumbarMidSw 0;
BA_REL_ "GenSigTimeoutTime" BU_SG_REL_ ALBCU SG_ 287 APSS_LumbarMidSw 1500;
BA_REL_ "GenSigTimeoutTime" BU_SG_REL_ CGW_CCU SG_ 287 APSS_LumbarMidSw 1500;
BA_ "NetworkRequest" SG_ 287 APSS_LumbarMidSw 0;
BA_ "NetworkRequestHoldingTime" SG_ 287 APSS_LumbarMidSw 5000;
BA_ "Version" SG_ 287 APSS_LumbarMidSw "19.11.06";
BA_ "Description" SG_ 287 APSS_LumbarLowSw "APSS_LumbarLowerSwitch";
BA_ "GenSigSendType" SG_ 287 APSS_LumbarLowSw 4;
BA_ "UserSigValidity" SG_ 287 APSS_LumbarLowSw 0;
BA_REL_ "GenSigTimeoutTime" BU_SG_REL_ ALBCU SG_ 287 APSS_LumbarLowSw 1500;
BA_REL_ "GenSigTimeoutTime" BU_SG_REL_ CGW_CCU SG_ 287 APSS_LumbarLowSw 1500;
BA_ "NetworkRequest" SG_ 287 APSS_LumbarLowSw 0;
BA_ "NetworkRequestHoldingTime" SG_ 287 APSS_LumbarLowSw 5000;
BA_ "Version" SG_ 287 APSS_LumbarLowSw "19.11.06";
BA_ "Description" SG_ 287 APSS_LumbarDefSw "APSS_LumbarDeflationSwitch";
BA_ "GenSigSendType" SG_ 287 APSS_LumbarDefSw 4;
BA_ "UserSigValidity" SG_ 287 APSS_LumbarDefSw 0;
BA_REL_ "GenSigTimeoutTime" BU_SG_REL_ ALBCU SG_ 287 APSS_LumbarDefSw 1500;
BA_REL_ "GenSigTimeoutTime" BU_SG_REL_ CGW_CCU SG_ 287 APSS_LumbarDefSw 1500;
BA_ "NetworkRequest" SG_ 287 APSS_LumbarDefSw 0;
BA_ "NetworkRequestHoldingTime" SG_ 287 APSS_LumbarDefSw 5000;
BA_ "Version" SG_ 287 APSS_LumbarDefSw "19.11.06";
BA_ "Description" SG_ 287 APSS_BolsterInfSw "APSS_BolsterInflationSwitch";
BA_ "GenSigSendType" SG_ 287 APSS_BolsterInfSw 4;
BA_ "UserSigValidity" SG_ 287 APSS_BolsterInfSw 0;
BA_REL_ "GenSigTimeoutTime" BU_SG_REL_ ALBCU SG_ 287 APSS_BolsterInfSw 1500;
BA_REL_ "GenSigTimeoutTime" BU_SG_REL_ CGW_CCU SG_ 287 APSS_BolsterInfSw 1500;
BA_ "NetworkRequest" SG_ 287 APSS_BolsterInfSw 0;
BA_ "NetworkRequestHoldingTime" SG_ 287 APSS_BolsterInfSw 5000;
BA_ "Version" SG_ 287 APSS_BolsterInfSw "19.11.06";
BA_ "Description" SG_ 287 APSS_BolsterDefSw "APSS_BolsterDeflationSwitch";
BA_ "GenSigSendType" SG_ 287 APSS_BolsterDefSw 4;
BA_ "UserSigValidity" SG_ 287 APSS_BolsterDefSw 0;
BA_REL_ "GenSigTimeoutTime" BU_SG_REL_ ALBCU SG_ 287 APSS_BolsterDefSw 1500;
BA_REL_ "GenSigTimeoutTime" BU_SG_REL_ CGW_CCU SG_ 287 APSS_BolsterDefSw 1500;
BA_ "NetworkRequest" SG_ 287 APSS_BolsterDefSw 0;
BA_ "NetworkRequestHoldingTime" SG_ 287 APSS_BolsterDefSw 5000;
BA_ "Version" SG_ 287 APSS_BolsterDefSw "19.11.06";
BA_ "Description" SG_ 287 APSS_ActiveSw "Á¶¼ö¼® Äí¼Ç º¼½ºÅÍ Á¶Àý ½ºÀ§Ä¡";
BA_ "GenSigSendType" SG_ 287 APSS_ActiveSw 4;
BA_ "UserSigValidity" SG_ 287 APSS_ActiveSw 0;
BA_REL_ "GenSigTimeoutTime" BU_SG_REL_ ALBCU SG_ 287 APSS_ActiveSw 1500;
BA_ "NetworkRequest" SG_ 287 APSS_ActiveSw 0;
BA_ "NetworkRequestHoldingTime" SG_ 287 APSS_ActiveSw 5000;
BA_ "Version" SG_ 287 APSS_ActiveSw "20.11.02";
BA_ "Description" SG_ 287 APSS_CushInfSw "Á¶¼ö¼® Äí¼Ç°ø¾ÐÁ¶Àý Èí±â ¹öÆ°";
BA_ "GenSigSendType" SG_ 287 APSS_CushInfSw 4;
BA_ "UserSigValidity" SG_ 287 APSS_CushInfSw 0;
BA_REL_ "GenSigTimeoutTime" BU_SG_REL_ ALBCU SG_ 287 APSS_CushInfSw 1500;
BA_ "NetworkRequest" SG_ 287 APSS_CushInfSw 0;
BA_ "NetworkRequestHoldingTime" SG_ 287 APSS_CushInfSw 5000;
BA_ "Version" SG_ 287 APSS_CushInfSw "20.11.02";
BA_ "Description" SG_ 287 APSS_CushDefSw "Á¶¼ö¼® Äí¼Ç °ø¾Ð Á¶Àý ¹è±â ¹öÆ°";
BA_ "GenSigSendType" SG_ 287 APSS_CushDefSw 4;
BA_ "UserSigValidity" SG_ 287 APSS_CushDefSw 0;
BA_REL_ "GenSigTimeoutTime" BU_SG_REL_ ALBCU SG_ 287 APSS_CushDefSw 1500;
BA_ "NetworkRequest" SG_ 287 APSS_CushDefSw 0;
BA_ "NetworkRequestHoldingTime" SG_ 287 APSS_CushDefSw 5000;
BA_ "Version" SG_ 287 APSS_CushDefSw "20.11.02";
BA_ "Description" SG_ 287 APSS_CushOnOffTch "ÅÍÄ¡ ½ºÀ§Ä¡ Á¤º¸";
BA_ "GenSigSendType" SG_ 287 APSS_CushOnOffTch 4;
BA_ "UserSigValidity" SG_ 287 APSS_CushOnOffTch 3;
BA_REL_ "GenSigTimeoutTime" BU_SG_REL_ ALBCU SG_ 287 APSS_CushOnOffTch 1500;
BA_ "NetworkRequest" SG_ 287 APSS_CushOnOffTch 0;
BA_ "NetworkRequestHoldingTime" SG_ 287 APSS_CushOnOffTch 5000;
BA_ "Version" SG_ 287 APSS_CushOnOffTch "20.11.02";
BA_ "GenMsgSendType" BO_ 271 0;
BA_ "Description" SG_ 271 ASAU_AirSptTimeRValueSet "Air Support Time(Massage Time) USM R Value";
BA_ "GenSigSendType" SG_ 271 ASAU_AirSptTimeRValueSet 4;
BA_ "UserSigValidity" SG_ 271 ASAU_AirSptTimeRValueSet 3;
BA_REL_ "GenSigTimeoutTime" BU_SG_REL_ CGW_CCU SG_ 271 ASAU_AirSptTimeRValueSet 1500;
BA_ "NetworkRequest" SG_ 271 ASAU_AirSptTimeRValueSet 0;
BA_ "NetworkRequestHoldingTime" SG_ 271 ASAU_AirSptTimeRValueSet 5000;
BA_ "Version" SG_ 271 ASAU_AirSptTimeRValueSet "19.11.06";
BA_ "Description" SG_ 271 ASAU_AstSmtAirSptRValueSet "Seat Smart Air Support Function USM R Value";
BA_ "GenSigSendType" SG_ 271 ASAU_AstSmtAirSptRValueSet 4;
BA_ "UserSigValidity" SG_ 271 ASAU_AstSmtAirSptRValueSet 3;
BA_REL_ "GenSigTimeoutTime" BU_SG_REL_ CGW_CCU SG_ 271 ASAU_AstSmtAirSptRValueSet 1500;
BA_ "NetworkRequest" SG_ 271 ASAU_AstSmtAirSptRValueSet 0;
BA_ "NetworkRequestHoldingTime" SG_ 271 ASAU_AstSmtAirSptRValueSet 5000;
BA_ "Version" SG_ 271 ASAU_AstSmtAirSptRValueSet "19.12.00";
BA_ "Description" SG_ 271 ASAU_CushSoftRValueSet "Cushion Soft R Value";
BA_ "GenSigSendType" SG_ 271 ASAU_CushSoftRValueSet 4;
BA_ "UserSigValidity" SG_ 271 ASAU_CushSoftRValueSet 3;
BA_REL_ "GenSigTimeoutTime" BU_SG_REL_ CGW_CCU SG_ 271 ASAU_CushSoftRValueSet 1500;
BA_ "NetworkRequest" SG_ 271 ASAU_CushSoftRValueSet 0;
BA_ "NetworkRequestHoldingTime" SG_ 271 ASAU_CushSoftRValueSet 5000;
BA_ "Version" SG_ 271 ASAU_CushSoftRValueSet "20.04.02";
BA_ "Description" SG_ 271 ASAU_BackSoftRValueSet "Back Soft USM R Value";
BA_ "GenSigSendType" SG_ 271 ASAU_BackSoftRValueSet 4;
BA_ "UserSigValidity" SG_ 271 ASAU_BackSoftRValueSet 3;
BA_REL_ "GenSigTimeoutTime" BU_SG_REL_ CGW_CCU SG_ 271 ASAU_BackSoftRValueSet 1500;
BA_ "NetworkRequest" SG_ 271 ASAU_BackSoftRValueSet 0;
BA_ "NetworkRequestHoldingTime" SG_ 271 ASAU_BackSoftRValueSet 5000;
BA_ "Version" SG_ 271 ASAU_BackSoftRValueSet "20.04.02";
BA_ "Description" SG_ 271 ASAU_AirSptModeRValueSet "Air Support Mode(Massage Mode) USM R Value";
BA_ "GenSigSendType" SG_ 271 ASAU_AirSptModeRValueSet 4;
BA_ "UserSigValidity" SG_ 271 ASAU_AirSptModeRValueSet 3;
BA_REL_ "GenSigTimeoutTime" BU_SG_REL_ CGW_CCU SG_ 271 ASAU_AirSptModeRValueSet 1500;
BA_ "NetworkRequest" SG_ 271 ASAU_AirSptModeRValueSet 0;
BA_ "NetworkRequestHoldingTime" SG_ 271 ASAU_AirSptModeRValueSet 5000;
BA_ "Version" SG_ 271 ASAU_AirSptModeRValueSet "19.11.06";
BA_ "Description" SG_ 271 ASAU_NotFootMsgOperStaWarnPE "Passenger Foot Massage Operation Disable Mode";
BA_ "GenSigSendType" SG_ 271 ASAU_NotFootMsgOperStaWarnPE 4;
BA_ "UserSigValidity" SG_ 271 ASAU_NotFootMsgOperStaWarnPE 3;
BA_REL_ "GenSigTimeoutTime" BU_SG_REL_ ATS SG_ 271 ASAU_NotFootMsgOperStaWarnPE 1500;
BA_ "NetworkRequest" SG_ 271 ASAU_NotFootMsgOperStaWarnPE 0;
BA_ "NetworkRequestHoldingTime" SG_ 271 ASAU_NotFootMsgOperStaWarnPE 5000;
BA_ "Version" SG_ 271 ASAU_NotFootMsgOperStaWarnPE "20.08.00";
BA_ "Description" SG_ 271 ASAU_RRFootAirSptRValueSet "Foot Air Support USM R Value";
BA_ "GenSigSendType" SG_ 271 ASAU_RRFootAirSptRValueSet 4;
BA_ "UserSigValidity" SG_ 271 ASAU_RRFootAirSptRValueSet 3;
BA_REL_ "GenSigTimeoutTime" BU_SG_REL_ ATS SG_ 271 ASAU_RRFootAirSptRValueSet 1500;
BA_ "NetworkRequest" SG_ 271 ASAU_RRFootAirSptRValueSet 0;
BA_ "NetworkRequestHoldingTime" SG_ 271 ASAU_RRFootAirSptRValueSet 5000;
BA_ "Version" SG_ 271 ASAU_RRFootAirSptRValueSet "19.12.00";
BA_ "Description" SG_ 271 ASAU_RRFootAirSptHeatRValueSet "Foot Air Support Heat USM R Value";
BA_ "GenSigSendType" SG_ 271 ASAU_RRFootAirSptHeatRValueSet 4;
BA_ "UserSigValidity" SG_ 271 ASAU_RRFootAirSptHeatRValueSet 3;
BA_REL_ "GenSigTimeoutTime" BU_SG_REL_ ATS SG_ 271 ASAU_RRFootAirSptHeatRValueSet 1500;
BA_ "NetworkRequest" SG_ 271 ASAU_RRFootAirSptHeatRValueSet 0;
BA_ "NetworkRequestHoldingTime" SG_ 271 ASAU_RRFootAirSptHeatRValueSet 5000;
BA_ "Version" SG_ 271 ASAU_RRFootAirSptHeatRValueSet "20.01.02";
BA_ "Description" SG_ 271 ASAU_MoodTrpyRValueSet "Passenger Seat Mood Therapy R Value";
BA_ "GenSigSendType" SG_ 271 ASAU_MoodTrpyRValueSet 4;
BA_ "UserSigValidity" SG_ 271 ASAU_MoodTrpyRValueSet 3;
BA_REL_ "GenSigTimeoutTime" BU_SG_REL_ CGW_CCU SG_ 271 ASAU_MoodTrpyRValueSet 1500;
BA_ "NetworkRequest" SG_ 271 ASAU_MoodTrpyRValueSet 0;
BA_ "NetworkRequestHoldingTime" SG_ 271 ASAU_MoodTrpyRValueSet 5000;
BA_ "Version" SG_ 271 ASAU_MoodTrpyRValueSet "20.07.03";
BA_ "Description" SG_ 271 ASAU_MoodTrpyCareSta "Passenger Seat Mood Therapy Care Mode R Value";
BA_ "GenSigSendType" SG_ 271 ASAU_MoodTrpyCareSta 4;
BA_ "UserSigValidity" SG_ 271 ASAU_MoodTrpyCareSta 3;
BA_REL_ "GenSigTimeoutTime" BU_SG_REL_ CGW_CCU SG_ 271 ASAU_MoodTrpyCareSta 1500;
BA_ "NetworkRequest" SG_ 271 ASAU_MoodTrpyCareSta 0;
BA_ "NetworkRequestHoldingTime" SG_ 271 ASAU_MoodTrpyCareSta 5000;
BA_ "Version" SG_ 271 ASAU_MoodTrpyCareSta "20.07.12";
BA_ "Description" SG_ 271 ASAU_MoodTrpyComfSta "Passenger Seat Mood Therapy Comfort Mode R Value";
BA_ "GenSigSendType" SG_ 271 ASAU_MoodTrpyComfSta 4;
BA_ "UserSigValidity" SG_ 271 ASAU_MoodTrpyComfSta 3;
BA_REL_ "GenSigTimeoutTime" BU_SG_REL_ CGW_CCU SG_ 271 ASAU_MoodTrpyComfSta 1500;
BA_ "NetworkRequest" SG_ 271 ASAU_MoodTrpyComfSta 0;
BA_ "NetworkRequestHoldingTime" SG_ 271 ASAU_MoodTrpyComfSta 5000;
BA_ "Version" SG_ 271 ASAU_MoodTrpyComfSta "20.07.12";
BA_ "Description" SG_ 271 ASAU_AirSptStrRValueSet "Air Support Strenth(Massage Strenth) USM R Value";
BA_ "GenSigSendType" SG_ 271 ASAU_AirSptStrRValueSet 4;
BA_ "UserSigValidity" SG_ 271 ASAU_AirSptStrRValueSet 3;
BA_REL_ "GenSigTimeoutTime" BU_SG_REL_ CGW_CCU SG_ 271 ASAU_AirSptStrRValueSet 1500;
BA_ "NetworkRequest" SG_ 271 ASAU_AirSptStrRValueSet 0;
BA_ "NetworkRequestHoldingTime" SG_ 271 ASAU_AirSptStrRValueSet 5000;
BA_ "Version" SG_ 271 ASAU_AirSptStrRValueSet "20.07.11";
BA_ "GenMsgSendType" BO_ 733 0;
BA_ "Description" SG_ 733 CMS_LH_Crc1Val "The data area for CRC calculation is based on the data length (DLC) of the message DB.

The CRC shall be calculated over the entire data block (excluding the CRC bytes) including the user data, alive counter and Data ID 

 

- CRC Polynomial (0x1D) , Initial Value : 0x00, XOR value : 0xFF, Data ID Mode : Both, Data ID : Message ID + 0xF800 

- The initial value is for CRC calculation and the message should be sent with the calculated result value. 

The mathematical expression to 8 bit CRC polynomial is given here. G(x) = x8 + x4 + x3 + x2 + 1";
BA_ "GenSigSendType" SG_ 733 CMS_LH_Crc1Val 4;
BA_ "GenSigStartValue" SG_ 733 CMS_LH_Crc1Val 255;
BA_ "UserSigValidity" SG_ 733 CMS_LH_Crc1Val 0;
BA_ "RoutingFactor" SG_ 733 CMS_LH_Crc1Val 0;
BA_ "Version" SG_ 733 CMS_LH_Crc1Val "19.09.06";
BA_ "Description" SG_ 733 CMS_LH_AlvCnt1Val "For the first transmission request for a data element the counter shall be initialized with 0 and shall be incremented by 1

for every subsequent send request. When the counter reaches the maximum value(0xE), then it shall restart with 0 for the next send request";
BA_ "GenSigSendType" SG_ 733 CMS_LH_AlvCnt1Val 4;
BA_ "UserSigValidity" SG_ 733 CMS_LH_AlvCnt1Val 0;
BA_ "RoutingFactor" SG_ 733 CMS_LH_AlvCnt1Val 0;
BA_ "Version" SG_ 733 CMS_LH_AlvCnt1Val "19.09.06";
BA_ "GenSigSendType" SG_ 733 USM_TurnDstLnDispSta 4;
BA_ "UserSigValidity" SG_ 733 USM_TurnDstLnDispSta 0;
BA_ "NetworkRequest" SG_ 733 USM_TurnDstLnDispSta 0;
BA_ "NetworkRequestHoldingTime" SG_ 733 USM_TurnDstLnDispSta 5;
BA_ "RoutingFactor" SG_ 733 USM_TurnDstLnDispSta 0;
BA_ "Version" SG_ 733 USM_TurnDstLnDispSta "19.12.00";
BA_ "GenSigSendType" SG_ 733 USM_TurnDstLnDispStaRH 4;
BA_ "UserSigValidity" SG_ 733 USM_TurnDstLnDispStaRH 0;
BA_ "NetworkRequest" SG_ 733 USM_TurnDstLnDispStaRH 0;
BA_ "NetworkRequestHoldingTime" SG_ 733 USM_TurnDstLnDispStaRH 5;
BA_ "RoutingFactor" SG_ 733 USM_TurnDstLnDispStaRH 0;
BA_ "Version" SG_ 733 USM_TurnDstLnDispStaRH "19.12.00";
BA_ "GenSigSendType" SG_ 733 USM_RhstaLvlEnaSta 4;
BA_ "UserSigValidity" SG_ 733 USM_RhstaLvlEnaSta 0;
BA_ "NetworkRequest" SG_ 733 USM_RhstaLvlEnaSta 0;
BA_ "NetworkRequestHoldingTime" SG_ 733 USM_RhstaLvlEnaSta 5;
BA_ "RoutingFactor" SG_ 733 USM_RhstaLvlEnaSta 0;
BA_ "Version" SG_ 733 USM_RhstaLvlEnaSta "19.12.00";
BA_ "GenSigSendType" SG_ 733 USM_RhstaLvlEnaStaRH 4;
BA_ "UserSigValidity" SG_ 733 USM_RhstaLvlEnaStaRH 0;
BA_ "NetworkRequest" SG_ 733 USM_RhstaLvlEnaStaRH 0;
BA_ "NetworkRequestHoldingTime" SG_ 733 USM_RhstaLvlEnaStaRH 5;
BA_ "RoutingFactor" SG_ 733 USM_RhstaLvlEnaStaRH 0;
BA_ "Version" SG_ 733 USM_RhstaLvlEnaStaRH "19.12.00";
BA_ "GenSigSendType" SG_ 733 USM_CMSDayBrgtnsLvlLHSta 4;
BA_ "GenSigStartValue" SG_ 733 USM_CMSDayBrgtnsLvlLHSta 5;
BA_ "UserSigValidity" SG_ 733 USM_CMSDayBrgtnsLvlLHSta 0;
BA_ "NetworkRequest" SG_ 733 USM_CMSDayBrgtnsLvlLHSta 0;
BA_ "NetworkRequestHoldingTime" SG_ 733 USM_CMSDayBrgtnsLvlLHSta 5;
BA_ "RoutingFactor" SG_ 733 USM_CMSDayBrgtnsLvlLHSta 0;
BA_ "Version" SG_ 733 USM_CMSDayBrgtnsLvlLHSta "19.12.00";
BA_ "GenSigSendType" SG_ 733 USM_CMSNgtBrgtnsLvlLHSta 4;
BA_ "GenSigStartValue" SG_ 733 USM_CMSNgtBrgtnsLvlLHSta 5;
BA_ "UserSigValidity" SG_ 733 USM_CMSNgtBrgtnsLvlLHSta 0;
BA_ "NetworkRequest" SG_ 733 USM_CMSNgtBrgtnsLvlLHSta 0;
BA_ "NetworkRequestHoldingTime" SG_ 733 USM_CMSNgtBrgtnsLvlLHSta 5;
BA_ "RoutingFactor" SG_ 733 USM_CMSNgtBrgtnsLvlLHSta 0;
BA_ "Version" SG_ 733 USM_CMSNgtBrgtnsLvlLHSta "19.12.00";
BA_ "GenSigSendType" SG_ 733 IMS_CMSPlayBackSta_LH 4;
BA_ "UserSigValidity" SG_ 733 IMS_CMSPlayBackSta_LH 0;
BA_REL_ "GenSigTimeoutTime" BU_SG_REL_ DPSU SG_ 733 IMS_CMSPlayBackSta_LH 1500;
BA_ "NetworkRequest" SG_ 733 IMS_CMSPlayBackSta_LH 0;
BA_ "NetworkRequestHoldingTime" SG_ 733 IMS_CMSPlayBackSta_LH 5;
BA_ "RoutingFactor" SG_ 733 IMS_CMSPlayBackSta_LH 0;
BA_ "Version" SG_ 733 IMS_CMSPlayBackSta_LH "20.08.07";
BA_ "GenSigSendType" SG_ 733 CMSFldReq 4;
BA_ "UserSigValidity" SG_ 733 CMSFldReq 0;
BA_ "NetworkRequest" SG_ 733 CMSFldReq 0;
BA_ "NetworkRequestHoldingTime" SG_ 733 CMSFldReq 5;
BA_ "RoutingFactor" SG_ 733 CMSFldReq 0;
BA_ "Version" SG_ 733 CMSFldReq "20.08.07";
BA_ "GenSigSendType" SG_ 733 CMS_LH_FoldingSta 4;
BA_ "UserSigValidity" SG_ 733 CMS_LH_FoldingSta 0;
BA_ "NetworkRequest" SG_ 733 CMS_LH_FoldingSta 0;
BA_ "NetworkRequestHoldingTime" SG_ 733 CMS_LH_FoldingSta 5000;
BA_ "RoutingFactor" SG_ 733 CMS_LH_FoldingSta 0;
BA_ "Version" SG_ 733 CMS_LH_FoldingSta "20.11.04";
BA_ "GenSigSendType" SG_ 733 CMS_LH_UnfoldingSta 4;
BA_ "UserSigValidity" SG_ 733 CMS_LH_UnfoldingSta 0;
BA_ "NetworkRequest" SG_ 733 CMS_LH_UnfoldingSta 0;
BA_ "NetworkRequestHoldingTime" SG_ 733 CMS_LH_UnfoldingSta 5000;
BA_ "RoutingFactor" SG_ 733 CMS_LH_UnfoldingSta 0;
BA_ "Version" SG_ 733 CMS_LH_UnfoldingSta "20.11.04";
BA_ "Description" SG_ 733 CMS_LHVerPosVal "This signal indicates LH Outside Mirror Vertical Position Sensor Voltage";
BA_ "GenSigSendType" SG_ 733 CMS_LHVerPosVal 4;
BA_ "UserSigValidity" SG_ 733 CMS_LHVerPosVal 0;
BA_ "NetworkRequest" SG_ 733 CMS_LHVerPosVal 0;
BA_ "NetworkRequestHoldingTime" SG_ 733 CMS_LHVerPosVal 5000;
BA_ "RoutingFactor" SG_ 733 CMS_LHVerPosVal 0;
BA_ "Version" SG_ 733 CMS_LHVerPosVal "20.08.07";
BA_ "Description" SG_ 733 CMS_LHHorPosVal "This signal indicates LH Outside Mirror Horizontal Position Sensor Voltage";
BA_ "GenSigSendType" SG_ 733 CMS_LHHorPosVal 4;
BA_ "UserSigValidity" SG_ 733 CMS_LHHorPosVal 0;
BA_ "NetworkRequest" SG_ 733 CMS_LHHorPosVal 0;
BA_ "NetworkRequestHoldingTime" SG_ 733 CMS_LHHorPosVal 5000;
BA_ "RoutingFactor" SG_ 733 CMS_LHHorPosVal 0;
BA_ "Version" SG_ 733 CMS_LHHorPosVal "20.08.07";
BA_ "GenSigSendType" SG_ 733 Monitor_ViewPanningCmd 4;
BA_ "UserSigValidity" SG_ 733 Monitor_ViewPanningCmd 0;
BA_ "NetworkRequest" SG_ 733 Monitor_ViewPanningCmd 0;
BA_ "NetworkRequestHoldingTime" SG_ 733 Monitor_ViewPanningCmd 5000;
BA_ "RoutingFactor" SG_ 733 Monitor_ViewPanningCmd 0;
BA_ "Version" SG_ 733 Monitor_ViewPanningCmd "19.09.06";
BA_ "GenMsgSendType" BO_ 2395189761 0;
BA_ "VFrameFormat" BO_ 2395189761 1;
BA_ "Description" SG_ 2395189761 DATC_Crc10Val "The data area for CRC calculation is based on the data length (DLC) of the message DB.

The CRC shall be calculated over the entire data block (excluding the CRC bytes) including the user data, alive counter and Data ID

 

- CRC Polynomial (0x1021) , Initial Value : 0xFFFF, XOR value : 0x0000, Data ID : Message ID + 0xF800 

- The initial value is for CRC calculation and the message should be sent with the calculated result value. 

- The mathematical expression to 16 bit CRC polynomial is given here. G(x) = x16 + x12 + x5 + 1";
BA_ "GenSigSendType" SG_ 2395189761 DATC_Crc10Val 4;
BA_ "GenSigStartValue" SG_ 2395189761 DATC_Crc10Val 65535;
BA_ "UserSigValidity" SG_ 2395189761 DATC_Crc10Val 3;
BA_ "Version" SG_ 2395189761 DATC_Crc10Val "18.11.08";
BA_ "Description" SG_ 2395189761 DATC_AlvCnt10Val "For the first transmission request for a data element the counter shall be initialized with 0 and shall be incremented by 1 for every subsequent send request. 

When the counter reaches the maximum value(0xFF), then it shall restart with 0 for the next send request";
BA_ "GenSigSendType" SG_ 2395189761 DATC_AlvCnt10Val 4;
BA_ "UserSigValidity" SG_ 2395189761 DATC_AlvCnt10Val 3;
BA_ "Version" SG_ 2395189761 DATC_AlvCnt10Val "18.11.08";
BA_ "Description" SG_ 2395189761 DATC_Typ "HTR CONTROL TYPE

Bit0 (FR Control) : 0 ? ATC / 1 ? MTC

Bit1~2 (Temp) : 0 ? Single / 1 ? Dual / 2 ? 3Zone / 3 ? 4Zone

Bit3~4 (Mode) : 0 ? Single / 1 ? Dual / 2 ? 3Zone / 3 ? 4Zone

Bit5 (Rear Control) : 0 ? None or MTC / 1- ATC

Bit6 (RHD) : 0 ? LHD / 1 ? RHD

Bit7 (EU) : 0 ? Others / 1 ? EU";
BA_ "GenSigSendType" SG_ 2395189761 DATC_Typ 4;
BA_ "UserSigValidity" SG_ 2395189761 DATC_Typ 3;
BA_REL_ "GenSigTimeoutTime" BU_SG_REL_ RLHV SG_ 2395189761 DATC_Typ 1500;
BA_REL_ "GenSigTimeoutTime" BU_SG_REL_ RRHV SG_ 2395189761 DATC_Typ 1500;
BA_REL_ "GenSigTimeoutTime" BU_SG_REL_ SHVU_FR SG_ 2395189761 DATC_Typ 1500;
BA_REL_ "GenSigTimeoutTime" BU_SG_REL_ SHVU_RR SG_ 2395189761 DATC_Typ 1500;
BA_REL_ "GenSigTimeoutTime" BU_SG_REL_ ATS SG_ 2395189761 DATC_Typ 1500;
BA_ "Version" SG_ 2395189761 DATC_Typ "20.03.01";
BA_ "Description" SG_ 2395189761 DATC_Opt1Typ "Bit0 : (ADS) : 0 - Non ADS / 1 - ADS

Bit1 : (AQS) : 0 - Non AQS / 1 ? AQS

Bit2 : (MAX AC) : 0 - Non MAX AC / 1 - MAX AC

Bit3 : (SYNC) : 0 - Non SYNC / 1 - SYNC

Bit4 : (DUST) : 0 - Non AIR PURIFIER / 1 - AIR PURIFIER

Bit5 : (Smart_Vent) : 0 - Non SMART VENT / 1 ? SMART VENT

Bit6 : (CO2) : 0 - Non CO2 / 1 - CO2

Bit7 : (REAR LOCK) : 0 - NON REAR LOCK / 1 - REAR LOCK

HTR CONTROL OPTION";
BA_ "GenSigSendType" SG_ 2395189761 DATC_Opt1Typ 4;
BA_ "UserSigValidity" SG_ 2395189761 DATC_Opt1Typ 3;
BA_REL_ "GenSigTimeoutTime" BU_SG_REL_ ATS SG_ 2395189761 DATC_Opt1Typ 1500;
BA_ "Version" SG_ 2395189761 DATC_Opt1Typ "18.05.00";
BA_ "Description" SG_ 2395189761 DATC_Opt3Typ "This signal indicates Option of HTR Control.



Bit0~1 (Button Type)  : 0 ? Not Display in AVN /

                              1 ? Single (Blower-Temp-Mode) /

                              2 ? Single (Temp-Mode-Blower) / 

                              3 ? Dual ¡¤ 3zone ¡¤ 4zone / 

Bit2 : 0 - Defogging USM Not Apply / 1 - Defogging USM Apply 

Bit3 : 0 - Automatic Ventilation USM Not Apply / 1 - Automatic Ventilation USM Apply

Bit4 : 0 ? Auto AirCleaningSystem USM Not Apply / 1 - Auto AirCleaningSystem USM Apply

Bit5 : 0 ? Washer fluid Control USM Not Apply / 1 - Washer fluid Control USM Apply

Bit6~7 : 0 - Haptic Intensity USM Not Apply 

              1 - Haptic Intensity USM Apply (3-Level)

              2 - Haptic Intensity USM Apply (5-Level)

              3 - Reserved

0xFF : Invalid";
BA_ "GenSigSendType" SG_ 2395189761 DATC_Opt3Typ 4;
BA_ "UserSigValidity" SG_ 2395189761 DATC_Opt3Typ 3;
BA_REL_ "GenSigTimeoutTime" BU_SG_REL_ ATS SG_ 2395189761 DATC_Opt3Typ 1500;
BA_ "Version" SG_ 2395189761 DATC_Opt3Typ "18.11.00";
BA_ "Description" SG_ 2395189761 DATC_Opt2Typ "Bit0 : (FRONT BLOWER) : 0 - SINGLE BLOWER / 1 ? DUAL BLOWER

Bit1 : (FRONT AUTO ZONE) : 0 - SINGLE AUTO / 1 - DUAL AUTO

Bit2 : (LCD / NON LCD TYPE) : 0 - NON LCD /  1 - LCD TYPE

Bit3 : (INDIRECT VENT) : 0 - NON INDIRECT VENT /  1 - INDIRECT VENT

HTR CONTROL OPTION";
BA_ "GenSigSendType" SG_ 2395189761 DATC_Opt2Typ 4;
BA_ "UserSigValidity" SG_ 2395189761 DATC_Opt2Typ 3;
BA_REL_ "GenSigTimeoutTime" BU_SG_REL_ ATS SG_ 2395189761 DATC_Opt2Typ 1500;
BA_ "Version" SG_ 2395189761 DATC_Opt2Typ "19.04.06";
BA_ "Description" SG_ 2395189761 DATC_Opt4Typ "This signal indicates Option of HTR Control.



Bit0 (Driver Only Button) :  0 ? NOT Apply / 1 ? Apply

Bit1 (HEAT Button) :  0 ? NOT Apply / 1 ? Apply

Bit2 (Multi-Air Mode) : 0 ? Not Apply / 1 - Apply

Bit3 : (Scheduled Ventilation) : 0 ? Not Apply / 1 ? Apply

0xF : invalid";
BA_ "GenSigSendType" SG_ 2395189761 DATC_Opt4Typ 4;
BA_ "UserSigValidity" SG_ 2395189761 DATC_Opt4Typ 7;
BA_REL_ "GenSigTimeoutTime" BU_SG_REL_ ATS SG_ 2395189761 DATC_Opt4Typ 1500;
BA_ "Version" SG_ 2395189761 DATC_Opt4Typ "19.08.08";
BA_ "Description" SG_ 2395189761 DATC_TxtPopupReq "DATC TEXT Pop-up";
BA_ "GenSigSendType" SG_ 2395189761 DATC_TxtPopupReq 4;
BA_ "UserSigValidity" SG_ 2395189761 DATC_TxtPopupReq 3;
BA_ "Version" SG_ 2395189761 DATC_TxtPopupReq "17.11.00";
BA_ "Description" SG_ 2395189761 DATC_StrWhlUSMSta "DATC and Steering Wheel heat Control Display request signal";
BA_ "GenSigSendType" SG_ 2395189761 DATC_StrWhlUSMSta 4;
BA_ "UserSigValidity" SG_ 2395189761 DATC_StrWhlUSMSta 3;
BA_REL_ "GenSigTimeoutTime" BU_SG_REL_ APSU SG_ 2395189761 DATC_StrWhlUSMSta 1500;
BA_ "Version" SG_ 2395189761 DATC_StrWhlUSMSta "18.03.05";
BA_ "Description" SG_ 2395189761 DATC_StrWhlHtngReq "Steering Wheel heat function on/off request";
BA_ "GenSigSendType" SG_ 2395189761 DATC_StrWhlHtngReq 4;
BA_ "UserSigValidity" SG_ 2395189761 DATC_StrWhlHtngReq 3;
BA_ "Version" SG_ 2395189761 DATC_StrWhlHtngReq "18.01.07";
BA_ "GenMsgCycleTime" BO_ 1882 0;
BA_ "GenMsgCycleTimeFast" BO_ 1882 0;
BA_ "GenMsgNrOfRepetition" BO_ 1882 0;
BA_ "DiagResponse" BO_ 1882 1;
BA_ "GenMsgILSupport" BO_ 1882 0;
BA_ "TpMessage" BO_ 1882 1;
BA_ "TpTxIndex" BO_ 1882 121;
BA_ "Description" SG_ 1882 DLBCU_GST_Byte0 "TP Index : 121";
BA_ "UsrSigPurpose" SG_ 1882 DLBCU_GST_Byte0 4;
BA_ "UserSigValidity" SG_ 1882 DLBCU_GST_Byte0 0;
BA_REL_ "GenSigTimeoutTime" BU_SG_REL_ CGW_CCU SG_ 1882 DLBCU_GST_Byte0 0;
BA_ "NetworkRequest" SG_ 1882 DLBCU_GST_Byte0 0;
BA_ "NetworkRequestHoldingTime" SG_ 1882 DLBCU_GST_Byte0 5000;
BA_ "Version" SG_ 1882 DLBCU_GST_Byte0 "21.02.04";
BA_ "Description" SG_ 1882 DLBCU_GST_Byte2 "TP Index : 121";
BA_ "UsrSigPurpose" SG_ 1882 DLBCU_GST_Byte2 4;
BA_ "UserSigValidity" SG_ 1882 DLBCU_GST_Byte2 0;
BA_REL_ "GenSigTimeoutTime" BU_SG_REL_ CGW_CCU SG_ 1882 DLBCU_GST_Byte2 0;
BA_ "NetworkRequest" SG_ 1882 DLBCU_GST_Byte2 0;
BA_ "NetworkRequestHoldingTime" SG_ 1882 DLBCU_GST_Byte2 5000;
BA_ "Version" SG_ 1882 DLBCU_GST_Byte2 "21.02.04";
BA_ "Description" SG_ 1882 DLBCU_GST_Byte3 "TP Index : 121";
BA_ "UsrSigPurpose" SG_ 1882 DLBCU_GST_Byte3 4;
BA_ "UserSigValidity" SG_ 1882 DLBCU_GST_Byte3 0;
BA_REL_ "GenSigTimeoutTime" BU_SG_REL_ CGW_CCU SG_ 1882 DLBCU_GST_Byte3 0;
BA_ "NetworkRequest" SG_ 1882 DLBCU_GST_Byte3 0;
BA_ "NetworkRequestHoldingTime" SG_ 1882 DLBCU_GST_Byte3 5000;
BA_ "Version" SG_ 1882 DLBCU_GST_Byte3 "21.02.04";
BA_ "Description" SG_ 1882 DLBCU_GST_Byte4 "TP Index : 121";
BA_ "UsrSigPurpose" SG_ 1882 DLBCU_GST_Byte4 4;
BA_ "UserSigValidity" SG_ 1882 DLBCU_GST_Byte4 0;
BA_REL_ "GenSigTimeoutTime" BU_SG_REL_ CGW_CCU SG_ 1882 DLBCU_GST_Byte4 0;
BA_ "NetworkRequest" SG_ 1882 DLBCU_GST_Byte4 0;
BA_ "NetworkRequestHoldingTime" SG_ 1882 DLBCU_GST_Byte4 5000;
BA_ "Version" SG_ 1882 DLBCU_GST_Byte4 "21.02.04";
BA_ "Description" SG_ 1882 DLBCU_GST_Byte5 "TP Index : 121";
BA_ "UsrSigPurpose" SG_ 1882 DLBCU_GST_Byte5 4;
BA_ "UserSigValidity" SG_ 1882 DLBCU_GST_Byte5 0;
BA_REL_ "GenSigTimeoutTime" BU_SG_REL_ CGW_CCU SG_ 1882 DLBCU_GST_Byte5 0;
BA_ "NetworkRequest" SG_ 1882 DLBCU_GST_Byte5 0;
BA_ "NetworkRequestHoldingTime" SG_ 1882 DLBCU_GST_Byte5 5000;
BA_ "Version" SG_ 1882 DLBCU_GST_Byte5 "21.02.04";
BA_ "Description" SG_ 1882 DLBCU_GST_Byte6 "TP Index : 121";
BA_ "UsrSigPurpose" SG_ 1882 DLBCU_GST_Byte6 4;
BA_ "UserSigValidity" SG_ 1882 DLBCU_GST_Byte6 0;
BA_REL_ "GenSigTimeoutTime" BU_SG_REL_ CGW_CCU SG_ 1882 DLBCU_GST_Byte6 0;
BA_ "NetworkRequest" SG_ 1882 DLBCU_GST_Byte6 0;
BA_ "NetworkRequestHoldingTime" SG_ 1882 DLBCU_GST_Byte6 5000;
BA_ "Version" SG_ 1882 DLBCU_GST_Byte6 "21.02.04";
BA_ "Description" SG_ 1882 DLBCU_GST_Byte7 "TP Index : 121";
BA_ "UsrSigPurpose" SG_ 1882 DLBCU_GST_Byte7 4;
BA_ "UserSigValidity" SG_ 1882 DLBCU_GST_Byte7 0;
BA_REL_ "GenSigTimeoutTime" BU_SG_REL_ CGW_CCU SG_ 1882 DLBCU_GST_Byte7 0;
BA_ "NetworkRequest" SG_ 1882 DLBCU_GST_Byte7 0;
BA_ "NetworkRequestHoldingTime" SG_ 1882 DLBCU_GST_Byte7 5000;
BA_ "Version" SG_ 1882 DLBCU_GST_Byte7 "21.02.04";
BA_ "Description" SG_ 1882 DLBCU_GST_Byte1 "TP Index : 121";
BA_ "UsrSigPurpose" SG_ 1882 DLBCU_GST_Byte1 4;
BA_ "UserSigValidity" SG_ 1882 DLBCU_GST_Byte1 0;
BA_REL_ "GenSigTimeoutTime" BU_SG_REL_ CGW_CCU SG_ 1882 DLBCU_GST_Byte1 0;
BA_ "NetworkRequest" SG_ 1882 DLBCU_GST_Byte1 0;
BA_ "NetworkRequestHoldingTime" SG_ 1882 DLBCU_GST_Byte1 5000;
BA_ "Version" SG_ 1882 DLBCU_GST_Byte1 "21.02.04";
BA_ "GenMsgCycleTime" BO_ 1881 0;
BA_ "GenMsgCycleTimeFast" BO_ 1881 0;
BA_ "GenMsgNrOfRepetition" BO_ 1881 0;
BA_ "DiagResponse" BO_ 1881 1;
BA_ "GenMsgILSupport" BO_ 1881 0;
BA_ "TpMessage" BO_ 1881 1;
BA_ "TpTxIndex" BO_ 1881 122;
BA_ "Description" SG_ 1881 DPSS_GST_Byte0 "TP Index : 122";
BA_ "UsrSigPurpose" SG_ 1881 DPSS_GST_Byte0 4;
BA_ "UserSigValidity" SG_ 1881 DPSS_GST_Byte0 0;
BA_REL_ "GenSigTimeoutTime" BU_SG_REL_ CGW_CCU SG_ 1881 DPSS_GST_Byte0 0;
BA_ "NetworkRequest" SG_ 1881 DPSS_GST_Byte0 0;
BA_ "NetworkRequestHoldingTime" SG_ 1881 DPSS_GST_Byte0 5000;
BA_ "Version" SG_ 1881 DPSS_GST_Byte0 "21.02.04";
BA_ "Description" SG_ 1881 DPSS_GST_Byte2 "TP Index : 122";
BA_ "UsrSigPurpose" SG_ 1881 DPSS_GST_Byte2 4;
BA_ "UserSigValidity" SG_ 1881 DPSS_GST_Byte2 0;
BA_REL_ "GenSigTimeoutTime" BU_SG_REL_ CGW_CCU SG_ 1881 DPSS_GST_Byte2 0;
BA_ "NetworkRequest" SG_ 1881 DPSS_GST_Byte2 0;
BA_ "NetworkRequestHoldingTime" SG_ 1881 DPSS_GST_Byte2 5000;
BA_ "Version" SG_ 1881 DPSS_GST_Byte2 "21.02.04";
BA_ "Description" SG_ 1881 DPSS_GST_Byte3 "TP Index : 122";
BA_ "UsrSigPurpose" SG_ 1881 DPSS_GST_Byte3 4;
BA_ "UserSigValidity" SG_ 1881 DPSS_GST_Byte3 0;
BA_REL_ "GenSigTimeoutTime" BU_SG_REL_ CGW_CCU SG_ 1881 DPSS_GST_Byte3 0;
BA_ "NetworkRequest" SG_ 1881 DPSS_GST_Byte3 0;
BA_ "NetworkRequestHoldingTime" SG_ 1881 DPSS_GST_Byte3 5000;
BA_ "Version" SG_ 1881 DPSS_GST_Byte3 "21.02.04";
BA_ "Description" SG_ 1881 DPSS_GST_Byte4 "TP Index : 122";
BA_ "UsrSigPurpose" SG_ 1881 DPSS_GST_Byte4 4;
BA_ "UserSigValidity" SG_ 1881 DPSS_GST_Byte4 0;
BA_REL_ "GenSigTimeoutTime" BU_SG_REL_ CGW_CCU SG_ 1881 DPSS_GST_Byte4 0;
BA_ "NetworkRequest" SG_ 1881 DPSS_GST_Byte4 0;
BA_ "NetworkRequestHoldingTime" SG_ 1881 DPSS_GST_Byte4 5000;
BA_ "Version" SG_ 1881 DPSS_GST_Byte4 "21.02.04";
BA_ "Description" SG_ 1881 DPSS_GST_Byte5 "TP Index : 122";
BA_ "UsrSigPurpose" SG_ 1881 DPSS_GST_Byte5 4;
BA_ "UserSigValidity" SG_ 1881 DPSS_GST_Byte5 0;
BA_REL_ "GenSigTimeoutTime" BU_SG_REL_ CGW_CCU SG_ 1881 DPSS_GST_Byte5 0;
BA_ "NetworkRequest" SG_ 1881 DPSS_GST_Byte5 0;
BA_ "NetworkRequestHoldingTime" SG_ 1881 DPSS_GST_Byte5 5000;
BA_ "Version" SG_ 1881 DPSS_GST_Byte5 "21.02.04";
BA_ "Description" SG_ 1881 DPSS_GST_Byte6 "TP Index : 122";
BA_ "UsrSigPurpose" SG_ 1881 DPSS_GST_Byte6 4;
BA_ "UserSigValidity" SG_ 1881 DPSS_GST_Byte6 0;
BA_REL_ "GenSigTimeoutTime" BU_SG_REL_ CGW_CCU SG_ 1881 DPSS_GST_Byte6 0;
BA_ "NetworkRequest" SG_ 1881 DPSS_GST_Byte6 0;
BA_ "NetworkRequestHoldingTime" SG_ 1881 DPSS_GST_Byte6 5000;
BA_ "Version" SG_ 1881 DPSS_GST_Byte6 "21.02.04";
BA_ "Description" SG_ 1881 DPSS_GST_Byte7 "TP Index : 122";
BA_ "UsrSigPurpose" SG_ 1881 DPSS_GST_Byte7 4;
BA_ "UserSigValidity" SG_ 1881 DPSS_GST_Byte7 0;
BA_REL_ "GenSigTimeoutTime" BU_SG_REL_ CGW_CCU SG_ 1881 DPSS_GST_Byte7 0;
BA_ "NetworkRequest" SG_ 1881 DPSS_GST_Byte7 0;
BA_ "NetworkRequestHoldingTime" SG_ 1881 DPSS_GST_Byte7 5000;
BA_ "Version" SG_ 1881 DPSS_GST_Byte7 "21.02.04";
BA_ "Description" SG_ 1881 DPSS_GST_Byte1 "TP Index : 122";
BA_ "UsrSigPurpose" SG_ 1881 DPSS_GST_Byte1 4;
BA_ "UserSigValidity" SG_ 1881 DPSS_GST_Byte1 0;
BA_REL_ "GenSigTimeoutTime" BU_SG_REL_ CGW_CCU SG_ 1881 DPSS_GST_Byte1 0;
BA_ "NetworkRequest" SG_ 1881 DPSS_GST_Byte1 0;
BA_ "NetworkRequestHoldingTime" SG_ 1881 DPSS_GST_Byte1 5000;
BA_ "Version" SG_ 1881 DPSS_GST_Byte1 "21.02.04";
BA_ "GenMsgSendType" BO_ 2193667329 0;
BA_ "GenMsgCycleTime" BO_ 2193667329 50;
BA_ "GenMsgCycleTimeFast" BO_ 2193667329 0;
BA_ "GenMsgNrOfRepetition" BO_ 2193667329 0;
BA_ "VFrameFormat" BO_ 2193667329 1;
BA_ "Description" SG_ 2193667329 EMS_Crc1Val "The data area for CRC calculation is based on the data length (DLC) of the message DB.

The CRC shall be calculated over the entire data block (excluding the CRC bytes) including the user data, alive counter and Data ID

 

- CRC Polynomial (0x1021) , Initial Value : 0xFFFF, XOR value : 0x0000, Data ID : Message ID + 0xF800 

- The initial value is for CRC calculation and the message should be sent with the calculated result value. 

- The mathematical expression to 16 bit CRC polynomial is given here. G(x) = x16 + x12 + x5 + 1";
BA_ "GenSigStartValue" SG_ 2193667329 EMS_Crc1Val 65535;
BA_ "UserSigValidity" SG_ 2193667329 EMS_Crc1Val 3;
BA_ "RoutingFactor" SG_ 2193667329 EMS_Crc1Val 5;
BA_ "Version" SG_ 2193667329 EMS_Crc1Val "18.11.08";
BA_ "Description" SG_ 2193667329 EMS_AlvCnt1Val "For the first transmission request for a data element the counter shall be initialized with 0 and shall be incremented by 1 for every subsequent send request. 

When the counter reaches the maximum value(0xFF), then it shall restart with 0 for the next send request";
BA_ "UserSigValidity" SG_ 2193667329 EMS_AlvCnt1Val 3;
BA_ "RoutingFactor" SG_ 2193667329 EMS_AlvCnt1Val 5;
BA_ "Version" SG_ 2193667329 EMS_AlvCnt1Val "18.11.08";
BA_ "Description" SG_ 2193667329 ENG_CrctEngTqVal "This signal comprises the actual indicated engine torque (determined by calculation within the engine management system) (lambda control, knock control, catalyst overheating prevention function, temperature influences, TCS, TCU torque intervention etc. being taken into account).



If MSB is 1, this signal is - value.

else, this signal is +value.

0~10bit is used for absolute value.";
BA_ "UserSigValidity" SG_ 2193667329 ENG_CrctEngTqVal 3;
BA_ "RoutingFactor" SG_ 2193667329 ENG_CrctEngTqVal 5;
BA_ "Version" SG_ 2193667329 ENG_CrctEngTqVal "18.01.03";
BA_ "Description" SG_ 2193667329 ENG_StndTqRatioVal "This factor is calculated inside the ECU to express the long-term changes of the engine torque capabilities due to special operating conditions. It takes into consideration mainly the ambient pressure, the ambient air temperature, and the fuel quality. It is defined as follows :



Torque reduction factor = Possible indicated torque for current conditions / Possible indicated torque at standard conditions 



It is used by the TCU to adapt the gearshift strategy.";
BA_ "GenSigStartValue" SG_ 2193667329 ENG_StndTqRatioVal 127;
BA_ "UserSigValidity" SG_ 2193667329 ENG_StndTqRatioVal 3;
BA_ "RoutingFactor" SG_ 2193667329 ENG_StndTqRatioVal 5;
BA_ "Version" SG_ 2193667329 ENG_StndTqRatioVal "17.12.00";
BA_ "Description" SG_ 2193667329 ENG_FrctTqVal "This signal identifies the current engine friction loss torque. It is stored as a function of 'EngClntTempVal' and 'EngSpdVal' (FrctTqVal = f(EngClntTempVal, EngSpdVal)) in terms of an index table.

The index table is corrected depending on the current load under idle conditions.

The signal comprises the following influencing variables:

- Engine friction = f(EngClntTempVal, EngSpdVal, m)

- m= friction coefficient = f(oil,...)

- Charge cycle work

- Valve actuator

- Air conditioner compressor - interference compensation (intermittent)

- Accessories (e.g. water pump, generator, power-steering pump).

The engine friction losses are dominant in conjunction with the following influencing variables.

Peak loads are not included in the calculation.

Consequently, the engine output torque (flywheel torque) is calculated as follows:

TQ = CrctEngTqVal - FrctTqVal



If MSB is 1, this signal is - value.

else, this signal is +value.

0~10bit is used for absolute value.";
BA_ "UserSigValidity" SG_ 2193667329 ENG_FrctTqVal 3;
BA_ "RoutingFactor" SG_ 2193667329 ENG_FrctTqVal 5;
BA_ "Version" SG_ 2193667329 ENG_FrctTqVal "18.01.01";
BA_ "GenMsgSendType" BO_ 2193667330 0;
BA_ "GenMsgCycleTime" BO_ 2193667330 50;
BA_ "GenMsgCycleTimeFast" BO_ 2193667330 0;
BA_ "GenMsgNrOfRepetition" BO_ 2193667330 0;
BA_ "VFrameFormat" BO_ 2193667330 1;
BA_ "Description" SG_ 2193667330 ENG_IndTqVal "1) In cars equipped with gasoline engines with ETC system, the signal TQI is determined on the driver¡¯s demand including cruise control and other functions and corresponds to the theoretical

engine torque. The signal comprises influences, such as the ambient temperature, the atmospheric pressure, knock control, the catalyst overheating prevention function and other corrections but it does not depend on TCS/ESC and TCU interventions realised due to reduction of airflow into the

engine cylinders and due to ignition angle adjustment or injection/cylinder shut off.



TQI = f (drivers demand [with the influence of cruise control and other functions without the

influence of TCS/ESC and TCU interventions], ignition angle [without the influence of TCS/

ESC and TCU interventions])



2) In cars equipped with gasoline engines without ETC system, the signal TQI is determined on the basis of the measured air mass flow (MAF) which corresponds to the theoretical engine. The signal comprises influences, such as the ambient temperature, atmospheric pressure, knock control, the catalyst overheating prevention function and other corrections but it does not depend on TCS/ESC and TCU interventions realised due to ignition angle adjustment or injection/cylinder shut off.



TQI = f (MAF, ignition angle [without the influence of TCS/ESC and TCU interventions])



3) In cars equipped with Diesel engines, the signal TQI is determined on the basis of the

driver¡¯s demanding injected Diesel amount including cruise control and other functions but does not including the influence of TCS/ESC and TCU interventions. It corresponds to the theoretical engine torque and comprises influences such as the ambient temperature, the atmospheric pressure and

other corrections.



TQI = f (injected Diesel amount [without TCS/ESC and TCU interventions])



In case of failures of the load signal (either MAF error or other errors depending on the system configuration), a backup value is generated from specific index tables. The backup value mode is identified by the signal F_SUB_TQI.



There is a specific phase relationship between the signals TQI and F_SUB_TQI.



If MSB is 1, this signal is - value.

else, this signal is +value.

0~10bit is used for absolute value.";
BA_ "UserSigValidity" SG_ 2193667330 ENG_IndTqVal 3;
BA_ "RoutingFactor" SG_ 2193667330 ENG_IndTqVal 5;
BA_ "Version" SG_ 2193667330 ENG_IndTqVal "18.01.01";
BA_ "Description" SG_ 2193667330 ENG_IndTqBVal "TQI_B = f (actual torque + with the influence of TCS/ESC [without the influence of TCU interventions])

In cars equipped with gasoline engines with ETC system, the signal TQI is determined on actual torque.

The signal comprises influences, such as the ambient temperature, the atmospheric pressure, knock control, the catalyst overheating prevention function and other corrections but it does not include TCU interventions realised due to reduction of airflow into the engine cylinders and due to ignition angle adjustment or injection/cylinder shut off. But the signal does include TCS/ESC interventions.



If MSB is 1, this signal is - value.

else, this signal is +value.

0~10bit is used for absolute value.";
BA_ "UserSigValidity" SG_ 2193667330 ENG_IndTqBVal 3;
BA_ "RoutingFactor" SG_ 2193667330 ENG_IndTqBVal 5;
BA_ "Version" SG_ 2193667330 ENG_IndTqBVal "18.01.01";
BA_ "Description" SG_ 2193667330 ENG_EngSpdErrSta "This signal identifies an error on searching for a long tooth or on engine speed sensing.

Note : in some cases a limp-home function can be activated in the ECU (the engine speed signal is then based on the camshaft signal), and the engine may run even if an error is present on the crankshaft signal.



There is a specific phase relationship between the signals EngSpdVal and EngSpdErrSta.";
BA_ "UserSigValidity" SG_ 2193667330 ENG_EngSpdErrSta 3;
BA_ "RoutingFactor" SG_ 2193667330 ENG_EngSpdErrSta 5;
BA_ "Version" SG_ 2193667330 ENG_EngSpdErrSta "17.12.00";
BA_ "Description" SG_ 2193667330 ENG_MafErrSta "This signal indicates error on MAF signal";
BA_ "UserSigValidity" SG_ 2193667330 ENG_MafErrSta 3;
BA_ "RoutingFactor" SG_ 2193667330 ENG_MafErrSta 5;
BA_ "Version" SG_ 2193667330 ENG_MafErrSta "17.12.00";
BA_ "Description" SG_ 2193667330 ENG_EtcLmphModSta "When ETC Mal-function occurred, EMS requests Cluster to indicate limphome mode driving and inform driver to go to AS center as soon as possible.

- In case of ETC malfunction, EMS finishes ETC control so that a vehicle goes to limphome mode driving (Forced idle). Since sudden vehicle speed decrease can cause uncomfortable feeling to driver, EMS needs to indicate limphome mode condition on Cluster to induce driver to go to AS center as soon as possible.";
BA_ "UserSigValidity" SG_ 2193667330 ENG_EtcLmphModSta 3;
BA_ "RoutingFactor" SG_ 2193667330 ENG_EtcLmphModSta 5;
BA_ "Version" SG_ 2193667330 ENG_EtcLmphModSta "17.12.00";
BA_ "Description" SG_ 2193667330 ENG_SpltInjctnSta "The signal Split_Stat identifies the split injection status. 

 * Note This message is for the GDI Delphi engine applied vehicle only.";
BA_ "UserSigValidity" SG_ 2193667330 ENG_SpltInjctnSta 3;
BA_ "RoutingFactor" SG_ 2193667330 ENG_SpltInjctnSta 5;
BA_ "Version" SG_ 2193667330 ENG_SpltInjctnSta "17.11.00";
BA_ "Description" SG_ 2193667330 ENG_MaxAirconTqVal "EMS defines the maximum allowed A/C compressor torque for drivability and engine safety.

This signal offered to A/C ECU unit only in case of the external variable A/C system installed vehicle.";
BA_ "UserSigValidity" SG_ 2193667330 ENG_MaxAirconTqVal 3;
BA_ "RoutingFactor" SG_ 2193667330 ENG_MaxAirconTqVal 5;
BA_ "Version" SG_ 2193667330 ENG_MaxAirconTqVal "17.12.00";
BA_ "Description" SG_ 2193667330 ENG_AirconPrsrSnsrVal "An EMS senses A/C pitot-tube pressure (between compressor & evaporator) directly with APT sensor.

This signal offered to A/C ECU only in case of the external variable A/C system installed vehicle.";
BA_ "UserSigValidity" SG_ 2193667330 ENG_AirconPrsrSnsrVal 3;
BA_ "RoutingFactor" SG_ 2193667330 ENG_AirconPrsrSnsrVal 5;
BA_ "Version" SG_ 2193667330 ENG_AirconPrsrSnsrVal "17.12.00";
BA_ "Description" SG_ 2193667330 ENG_IsgSta "1. ISG Status expressing CAN message divided by CF_EMS_IsgStat and CF_EMS_IsgStat2 

2. In EMS , CF_EMS_IsgStat and CF_EMS_IsgStat2 do not duplicate the output condition

(EX: If CF_EMS_IsgStat is 01h~07h, CF_EMS_IsgStat2 is 00h)



0x0:ISG is not operating Normal engine operating without ISG/0x1:Idle stop is activated Idle is stopped by ECU during driving/0x2:Automatically started by ECU Engine is automatically started by ECU regardless driver¡¯s volition during idle stop because the condition that ISG function to be prohibited is satisfied, for example SOC is too low./0x3:ISG is prohibited Driver prohibits to activate ISG in order to avoid start lag when he met traffic jam for example./0x4:Fault is existing in ISG There is fault, which is related with ISG. So, idle stop is prohibited and engine started automatically if it is idle stop condition. But for the vehicles that use CF_EMS_ISGStat2, the condition for not-activated battery sensor can be ignored./0x5:Idle stop is inhibited by system automatically for safety and  convenient condition related with battery SOC, brake vacuum pressure etc. ISG function check for EOL./0x6:Auto start is deactivated system automatically to keep safety, Such as door open, hood open and seat belt unlock./0x7:If driver shift gear N to D range without braking to make auto starting. (Economy ISG Only)";
BA_ "UserSigValidity" SG_ 2193667330 ENG_IsgSta 3;
BA_ "RoutingFactor" SG_ 2193667330 ENG_IsgSta 5;
BA_ "Version" SG_ 2193667330 ENG_IsgSta "17.12.02";
BA_ "Description" SG_ 2193667330 ENG_OilLvlSta "This signal indicates the replace time of engine oil.";
BA_ "UserSigValidity" SG_ 2193667330 ENG_OilLvlSta 3;
BA_ "RoutingFactor" SG_ 2193667330 ENG_OilLvlSta 5;
BA_ "Version" SG_ 2193667330 ENG_OilLvlSta "17.12.00";
BA_ "GenMsgSendType" BO_ 2193667331 0;
BA_ "GenMsgCycleTime" BO_ 2193667331 50;
BA_ "GenMsgCycleTimeFast" BO_ 2193667331 0;
BA_ "GenMsgNrOfRepetition" BO_ 2193667331 0;
BA_ "VFrameFormat" BO_ 2193667331 1;
BA_ "Description" SG_ 2193667331 ENG_TrgtIdleRpmVal "The stationary target speed depends principally of the engine coolant temperature.

There is a difference between the target speed for manual transmission MT and automatic transmission (AT) in ¡¯neutral¡¯ and AT in ¡¯drive¡¯. 

- Immediately after start the catalyst heating function may increase the target speed 

- The battery charge monitoring increase the target speed.

- For A/C use the target speed may be increased";
BA_ "UserSigValidity" SG_ 2193667331 ENG_TrgtIdleRpmVal 3;
BA_ "RoutingFactor" SG_ 2193667331 ENG_TrgtIdleRpmVal 5;
BA_ "Version" SG_ 2193667331 ENG_TrgtIdleRpmVal "17.12.00";
BA_ "Description" SG_ 2193667331 ENG_GearShftDnDis "This signal represents gear shift down display status. EMS transmits gear shift down status to the cluster.";
BA_ "UserSigValidity" SG_ 2193667331 ENG_GearShftDnDis 3;
BA_ "RoutingFactor" SG_ 2193667331 ENG_GearShftDnDis 5;
BA_ "Version" SG_ 2193667331 ENG_GearShftDnDis "17.12.00";
BA_ "Description" SG_ 2193667331 ENG_DsrGearPosDis "This signal represents desirable gear position of current driving condition.

EMS transmits desirable gear position to the cluster.";
BA_ "UserSigValidity" SG_ 2193667331 ENG_DsrGearPosDis 3;
BA_ "RoutingFactor" SG_ 2193667331 ENG_DsrGearPosDis 5;
BA_ "Version" SG_ 2193667331 ENG_DsrGearPosDis "17.12.00";
BA_ "Description" SG_ 2193667331 ENG_SldFuncSta "This signal indicates that if speed limiter function is active or not.

If the speed limiter function is activated then CF_Ems_SldAct = 1. Although ¡°SLD Main¡± switch is on, if the Speed limiter function is deactivated then CF_Ems_SldAct should be set to ¡®0¡¯.";
BA_ "UserSigValidity" SG_ 2193667331 ENG_SldFuncSta 3;
BA_ "RoutingFactor" SG_ 2193667331 ENG_SldFuncSta 5;
BA_ "Version" SG_ 2193667331 ENG_SldFuncSta "17.12.00";
BA_ "Description" SG_ 2193667331 ENG_SldActnSta "This signal indicates that if positive action of a driver at speed limiter function is active or not. If the positive action is activated then CF_Ems_SldPosAct = 1, which let the current vehicle speed to exceed the limit speed set from a driver.

If kick-down switch isn¡¯t connected to engine ECU directly, ECU can recognize the positive action of a driver from accel pedal position indirectly.

When current vehicle speed exceeds the limit speed, vehicle reaction should be distinguished (e.g. lamp reaction or audio warning signal reaction) depending on the status of ¡°CF_Ems_SldPosAct¡±";
BA_ "UserSigValidity" SG_ 2193667331 ENG_SldActnSta 3;
BA_ "RoutingFactor" SG_ 2193667331 ENG_SldActnSta 5;
BA_ "Version" SG_ 2193667331 ENG_SldActnSta "17.12.00";
BA_ "Description" SG_ 2193667331 ENG_FuelTnkPrsrSta "This signal indicates that if fuel tank is high Pressure or not.

If the fuel tank is in high pressure status then CF_Ems_HPresStat = ¡®1¡¯.

If the fuel tank isn¡¯t in high pressure status then CF_Ems_HPresStat should be set to ¡®0¡¯.";
BA_ "UserSigValidity" SG_ 2193667331 ENG_FuelTnkPrsrSta 3;
BA_ "RoutingFactor" SG_ 2193667331 ENG_FuelTnkPrsrSta 5;
BA_ "Version" SG_ 2193667331 ENG_FuelTnkPrsrSta "17.12.00";
BA_ "Description" SG_ 2193667331 ENG_IsgBzrReq "This signal is for Economy Type ISG. This signal is reminding for preventing sudden starting immediately just after engine restarted or driver shift gear N to D range without braking to make auto starting.

 It transfer first 3 times why if valid one is missing.



In the case of 0x1,

Cluster Action : Buzzer on";
BA_ "UserSigValidity" SG_ 2193667331 ENG_IsgBzrReq 3;
BA_ "RoutingFactor" SG_ 2193667331 ENG_IsgBzrReq 5;
BA_ "Version" SG_ 2193667331 ENG_IsgBzrReq "17.12.00";
BA_ "Description" SG_ 2193667331 ENG_IsgFuelCnsmptDis "This signal is the fuel consumption during Idle stop for display to cluster. 

It transfer first 3 times during 0.001L why if valid one is missing, other valid signals are used for extra signals. So, cluster displays 0.001L at only one among three signals.";
BA_ "UserSigValidity" SG_ 2193667331 ENG_IsgFuelCnsmptDis 3;
BA_ "RoutingFactor" SG_ 2193667331 ENG_IsgFuelCnsmptDis 5;
BA_ "Version" SG_ 2193667331 ENG_IsgFuelCnsmptDis "17.12.00";
BA_ "Description" SG_ 2193667331 ENG_FuelCapOpnSta "This signal indicates that if fuel cap is opened or not.

If the fuel cap is opened then CF_Ems_FCopen = 1.

If the fuel tank isn¡¯t opened then CF_Ems_FCopen should be set to ¡®0¡¯.";
BA_ "UserSigValidity" SG_ 2193667331 ENG_FuelCapOpnSta 3;
BA_ "RoutingFactor" SG_ 2193667331 ENG_FuelCapOpnSta 5;
BA_ "Version" SG_ 2193667331 ENG_FuelCapOpnSta "17.12.00";
BA_ "Description" SG_ 2193667331 ENG_EcoDrvActvSta "This signal indicates if Active Eco Drive function is active or not.

If Active Eco Drive function is active, then CF_Ems_ActEcoAct =1.";
BA_ "UserSigValidity" SG_ 2193667331 ENG_EcoDrvActvSta 3;
BA_ "RoutingFactor" SG_ 2193667331 ENG_EcoDrvActvSta 5;
BA_ "Version" SG_ 2193667331 ENG_EcoDrvActvSta "17.12.00";
BA_ "Description" SG_ 2193667331 ENG_EngRunSta "This signal is indicating normal engine running status. When engine is normal engine running state out of start, the signal turns to 1, otherwise 0 including engine stop & starting phase(cranking).";
BA_ "UserSigValidity" SG_ 2193667331 ENG_EngRunSta 3;
BA_ "RoutingFactor" SG_ 2193667331 ENG_EngRunSta 5;
BA_ "Version" SG_ 2193667331 ENG_EngRunSta "17.12.00";
BA_ "Description" SG_ 2193667331 ENG_Isg2Sta "1. ISG Status CAN message is divided by CF_EMS_IsgStat and CF_EMS_IsgStat2 

2. CF_EMS_IsgStat and CF_EMS_IsgStat2 do not duplicate the output condition

(EX: If CF_EMS_IsgStat2 is 01h~03h, CF_EMS_IsgStat is 00h)";
BA_ "UserSigValidity" SG_ 2193667331 ENG_Isg2Sta 3;
BA_ "RoutingFactor" SG_ 2193667331 ENG_Isg2Sta 5;
BA_ "Version" SG_ 2193667331 ENG_Isg2Sta "17.12.00";
BA_ "Description" SG_ 2193667331 ENG_IgnOnSta "Status of ignition lock.";
BA_ "GenSigStartValue" SG_ 2193667331 ENG_IgnOnSta 1;
BA_ "UserSigValidity" SG_ 2193667331 ENG_IgnOnSta 3;
BA_ "RoutingFactor" SG_ 2193667331 ENG_IgnOnSta 5;
BA_ "Version" SG_ 2193667331 ENG_IgnOnSta "17.12.00";
BA_ "Description" SG_ 2193667331 ENG_Ack4TcsSta "Monitoring of TCS message; the EMS checks whether at least one new message has been transferred within 500 ms, and whether there is no plausibility error in conjunction with a torque intervention. If this case occurs, the bit is set; otherwise it is reset.



Plausibility check - torque intervention:

- Test criteria:

TCS mode, criteria C1:

(TCS_REQ=1) & (TQI_TCS<FFH) & (MSR_C_REQ = 0) & (TQI_MSR = 00H)

MSR mode, criteria C2:

(TCS_REQ=0) & (TQI_TCS=1¡¯s complement of TQI_MSR) & (MSR_C_REQ = 1) & (TQI_MSR > 00H)

No intervention, criteria C3 :

(TCS_REQ=0) & (TQI_TCS=FFH) & (MSR_C_REQ = 0) & (TQI_MSR = 00H)



- Criterion for error setting:

C1 v C2 v C3 ¡Á 1 (none of C1,C2 and C3 is true) for n message transmissions TCS1 (n=10)



- Criterion for remedying an error:

Ignition OFF; transmission is re-started if plausibility is OK for at least one CAN transmission.";
BA_ "UserSigValidity" SG_ 2193667331 ENG_Ack4TcsSta 3;
BA_ "RoutingFactor" SG_ 2193667331 ENG_Ack4TcsSta 5;
BA_ "Version" SG_ 2193667331 ENG_Ack4TcsSta "17.12.00";
BA_ "Description" SG_ 2193667331 ENG_FuelCutOffSta "If the PUC_STAT - bit = 1 then the engine is in fuel cut off state, i.e. e. no injection is applied.";
BA_ "UserSigValidity" SG_ 2193667331 ENG_FuelCutOffSta 3;
BA_ "RoutingFactor" SG_ 2193667331 ENG_FuelCutOffSta 5;
BA_ "Version" SG_ 2193667331 ENG_FuelCutOffSta "17.12.00";
BA_ "Description" SG_ 2193667331 ENG_CrctTqSta "The information TQ_COR_STAT informs the TCS or the TCU whether and to which extent injection and ignition interventions are admitted.



0x0:The desired intervention regarding ignition angle retardation and cylinder shut-off is executed. (Default value)/0x1:The desired intervention regarding ignition angle retardation and cylinder shut-off is executed; however, the requested target torque can not be adjusted precisely (torque steps)/0x2:The torque reduction regarding the ignition angle retardation cannot be completely executed. A cylinder shut-off is not possible at this time. Therefore a remaining torque (as difference between TQI_ASR/GS_REQ and TQI_INTV) is present and cannot be reduced./0x3:Due to a failure detected by a diagnosis function of the engine management system, the desired torque intervention for TCS regarding the ignition angle and cylinder shut-off is no longer executed.The torque intervention is terminated, the engine management system resets the requested engine torque to the TQI value using a ramp.";
BA_ "UserSigValidity" SG_ 2193667331 ENG_CrctTqSta 3;
BA_ "RoutingFactor" SG_ 2193667331 ENG_CrctTqSta 5;
BA_ "Version" SG_ 2193667331 ENG_CrctTqSta "17.12.02";
BA_ "Description" SG_ 2193667331 ENG_AirCompRlySta "The signal RLY_AC identifies the activation of the air conditioner compressor relay.";
BA_ "UserSigValidity" SG_ 2193667331 ENG_AirCompRlySta 3;
BA_ "RoutingFactor" SG_ 2193667331 ENG_AirCompRlySta 5;
BA_ "Version" SG_ 2193667331 ENG_AirCompRlySta "17.12.00";
BA_ "Description" SG_ 2193667331 ENG_LnchCntrlSta "State of Launch Control";
BA_ "UserSigValidity" SG_ 2193667331 ENG_LnchCntrlSta 3;
BA_ "RoutingFactor" SG_ 2193667331 ENG_LnchCntrlSta 5;
BA_ "Version" SG_ 2193667331 ENG_LnchCntrlSta "17.11.00";
BA_ "Description" SG_ 2193667331 ENG_EngSpdVal "This signal is generated by crankshaft segment period measurement (in case of an six-cylinder engine, this corresponds to a crankshaft angle of 120¡Æ) and measured with a resolution of 4 us.

This signal is represented as a 16 bit value.



The signal is no";
BA_ "UserSigValidity" SG_ 2193667331 ENG_EngSpdVal 3;
BA_ "RoutingFactor" SG_ 2193667331 ENG_EngSpdVal 5;
BA_ "Version" SG_ 2193667331 ENG_EngSpdVal "17.12.00";
BA_ "Description" SG_ 2193667331 ENG_GearShftUpDis "This signal represents gear shift up display status. EMS transmits gear shift up status to the cluster.";
BA_ "UserSigValidity" SG_ 2193667331 ENG_GearShftUpDis 3;
BA_ "RoutingFactor" SG_ 2193667331 ENG_GearShftUpDis 5;
BA_ "Version" SG_ 2193667331 ENG_GearShftUpDis "17.12.00";
BA_ "GenMsgSendType" BO_ 2193667332 0;
BA_ "GenMsgCycleTime" BO_ 2193667332 50;
BA_ "GenMsgCycleTimeFast" BO_ 2193667332 0;
BA_ "GenMsgNrOfRepetition" BO_ 2193667332 0;
BA_ "VFrameFormat" BO_ 2193667332 1;
BA_ "Description" SG_ 2193667332 ENG_TrgtFuelPmpPrsrVal "This signal indicates the Target Pressure of Fuel Pump";
BA_ "UserSigValidity" SG_ 2193667332 ENG_TrgtFuelPmpPrsrVal 3;
BA_ "RoutingFactor" SG_ 2193667332 ENG_TrgtFuelPmpPrsrVal 5;
BA_ "Version" SG_ 2193667332 ENG_TrgtFuelPmpPrsrVal "17.12.00";
BA_ "Description" SG_ 2193667332 ENG_VehSpdHiVal "This signal provides the one wheel velocity with resolution of 1 km/h,

and have 9 bits lengh.

In case of failure of sheel speed sensor, the value 1FF is used as error identifier";
BA_ "UserSigValidity" SG_ 2193667332 ENG_VehSpdHiVal 3;
BA_ "RoutingFactor" SG_ 2193667332 ENG_VehSpdHiVal 5;
BA_ "Version" SG_ 2193667332 ENG_VehSpdHiVal "18.01.01";
BA_ "Description" SG_ 2193667332 ENG_EngInhbNCC "This signal indicates the Inhibition of NCC MODE";
BA_ "GenSigStartValue" SG_ 2193667332 ENG_EngInhbNCC 1;
BA_ "UserSigValidity" SG_ 2193667332 ENG_EngInhbNCC 3;
BA_ "RoutingFactor" SG_ 2193667332 ENG_EngInhbNCC 5;
BA_ "Version" SG_ 2193667332 ENG_EngInhbNCC "18.04.02";
BA_ "Description" SG_ 2193667332 ENG_SldSwSta "This signal indicates the status of Speed limiter function.";
BA_ "TimeoutValue" SG_ 2193667332 ENG_SldSwSta "0x0";
BA_ "UserSigValidity" SG_ 2193667332 ENG_SldSwSta 3;
BA_ "RoutingFactor" SG_ 2193667332 ENG_SldSwSta 5;
BA_ "Version" SG_ 2193667332 ENG_SldSwSta "19.12.08";
BA_ "Description" SG_ 2193667332 ENG_SldDrvAlertDisp "If EMS sends the No Sld engaged status or Sld Disengaged status, 

Cluster shall display the status of Sld.";
BA_ "TimeoutValue" SG_ 2193667332 ENG_SldDrvAlertDisp "0x0";
BA_ "UserSigValidity" SG_ 2193667332 ENG_SldDrvAlertDisp 3;
BA_ "RoutingFactor" SG_ 2193667332 ENG_SldDrvAlertDisp 5;
BA_ "Version" SG_ 2193667332 ENG_SldDrvAlertDisp "19.12.08";
BA_ "Description" SG_ 2193667332 ENG_VehSpdLimVal "The vehicle speed which is measured by the EMS has to be sent to CLUSTER. This value is used for limiting speed of EMS. 

EMS limite vehicle speed as this value.";
BA_ "UserSigValidity" SG_ 2193667332 ENG_VehSpdLimVal 3;
BA_ "RoutingFactor" SG_ 2193667332 ENG_VehSpdLimVal 5;
BA_ "Version" SG_ 2193667332 ENG_VehSpdLimVal "18.01.01";
BA_ "Description" SG_ 2193667332 ENG_FuelCnsmptVal "The EMS uses the signal 'FCO' (FUEL CONSUMPTION) to inform other ECUs about the current consumption.";
BA_ "UserSigValidity" SG_ 2193667332 ENG_FuelCnsmptVal 3;
BA_ "RoutingFactor" SG_ 2193667332 ENG_FuelCnsmptVal 5;
BA_ "Version" SG_ 2193667332 ENG_FuelCnsmptVal "17.12.00";
BA_ "GenMsgSendType" BO_ 2214659329 0;
BA_ "GenMsgCycleTime" BO_ 2214659329 50;
BA_ "GenMsgCycleTimeFast" BO_ 2214659329 0;
BA_ "GenMsgNrOfRepetition" BO_ 2214659329 0;
BA_ "VFrameFormat" BO_ 2214659329 1;
BA_ "Description" SG_ 2214659329 EMS_Crc7Val "The data area for CRC calculation is based on the data length (DLC) of the message DB.

The CRC shall be calculated over the entire data block (excluding the CRC bytes) including the user data, alive counter and Data ID

 

- CRC Polynomial (0x1021) , Initial Value : 0xFFFF, XOR value : 0x0000, Data ID : Message ID + 0xF800 

- The initial value is for CRC calculation and the message should be sent with the calculated result value. 

- The mathematical expression to 16 bit CRC polynomial is given here. G(x) = x16 + x12 + x5 + 1";
BA_ "GenSigStartValue" SG_ 2214659329 EMS_Crc7Val 65535;
BA_ "UserSigValidity" SG_ 2214659329 EMS_Crc7Val 3;
BA_ "RoutingFactor" SG_ 2214659329 EMS_Crc7Val 5;
BA_ "Version" SG_ 2214659329 EMS_Crc7Val "18.11.08";
BA_ "Description" SG_ 2214659329 EMS_AlvCnt7Val "For the first transmission request for a data element the counter shall be initialized with 0 and shall be incremented by 1 for every subsequent send request. 

When the counter reaches the maximum value(0xFF), then it shall restart with 0 for the next send request";
BA_ "UserSigValidity" SG_ 2214659329 EMS_AlvCnt7Val 3;
BA_ "RoutingFactor" SG_ 2214659329 EMS_AlvCnt7Val 5;
BA_ "Version" SG_ 2214659329 EMS_AlvCnt7Val "18.11.08";
BA_ "Description" SG_ 2214659329 HEV_IndTqVal "Indicated engine torque after torque coordination(intervention)";
BA_ "UserSigValidity" SG_ 2214659329 HEV_IndTqVal 3;
BA_ "RoutingFactor" SG_ 2214659329 HEV_IndTqVal 5;
BA_ "Version" SG_ 2214659329 HEV_IndTqVal "18.10.07";
BA_ "Description" SG_ 2214659329 HEV_DrvTqVal "Driver's demand torque";
BA_ "UserSigValidity" SG_ 2214659329 HEV_DrvTqVal 3;
BA_ "RoutingFactor" SG_ 2214659329 HEV_DrvTqVal 5;
BA_ "Version" SG_ 2214659329 HEV_DrvTqVal "18.05.04";
BA_ "Description" SG_ 2214659329 HEV_TqStndVal "Standard value for torque scaling in torque interface";
BA_ "UserSigValidity" SG_ 2214659329 HEV_TqStndVal 3;
BA_ "RoutingFactor" SG_ 2214659329 HEV_TqStndVal 5;
BA_ "Version" SG_ 2214659329 HEV_TqStndVal "18.05.04";
BA_ "GenMsgSendType" BO_ 2214659330 0;
BA_ "GenMsgCycleTime" BO_ 2214659330 50;
BA_ "GenMsgCycleTimeFast" BO_ 2214659330 0;
BA_ "GenMsgNrOfRepetition" BO_ 2214659330 0;
BA_ "VFrameFormat" BO_ 2214659330 1;
BA_ "Description" SG_ 2214659330 HEV_FrctTqVal "Friction Loss Torque";
BA_ "UserSigValidity" SG_ 2214659330 HEV_FrctTqVal 3;
BA_ "RoutingFactor" SG_ 2214659330 HEV_FrctTqVal 5;
BA_ "Version" SG_ 2214659330 HEV_FrctTqVal "18.10.07";
BA_ "Description" SG_ 2214659330 HEV_EngSpdVal "Engine Speed";
BA_ "UserSigValidity" SG_ 2214659330 HEV_EngSpdVal 3;
BA_ "RoutingFactor" SG_ 2214659330 HEV_EngSpdVal 5;
BA_ "Version" SG_ 2214659330 HEV_EngSpdVal "18.05.04";
BA_ "Description" SG_ 2214659330 HEV_EngOpSta "Engine Operating State";
BA_ "UserSigValidity" SG_ 2214659330 HEV_EngOpSta 3;
BA_ "RoutingFactor" SG_ 2214659330 HEV_EngOpSta 5;
BA_ "Version" SG_ 2214659330 HEV_EngOpSta "18.05.04";
BA_ "Description" SG_ 2214659330 HEV_IntakeAirTempVal "Intake air temperature";
BA_ "UserSigValidity" SG_ 2214659330 HEV_IntakeAirTempVal 3;
BA_ "RoutingFactor" SG_ 2214659330 HEV_IntakeAirTempVal 5;
BA_ "Version" SG_ 2214659330 HEV_IntakeAirTempVal "18.05.04";
BA_ "Description" SG_ 2214659330 HEV_AccelPdlVal "The signal is a measure of the Accelerator Pedal value.

The accelerator pedal value is determined via 2 pedal sensors, which are connected mechanically to the accelerator pedal. If the EMS-ECU recognizes that the accelerator pedal is not activated, then the value 00 H is carried over on the CAN. If the EMS-ECU detects that the accelerator pedal is fully activated, then 3FE H is carried over on the CAN bus.

If an error is detected on both pedal sensor channels, this is identified by the value 3FFH";
BA_ "UserSigValidity" SG_ 2214659330 HEV_AccelPdlVal 3;
BA_ "RoutingFactor" SG_ 2214659330 HEV_AccelPdlVal 5;
BA_ "Version" SG_ 2214659330 HEV_AccelPdlVal "19.11.11";
BA_ "Description" SG_ 2214659330 HEV_IndTqTar "Indicated Engine (Desired) Torque";
BA_ "UserSigValidity" SG_ 2214659330 HEV_IndTqTar 3;
BA_ "RoutingFactor" SG_ 2214659330 HEV_IndTqTar 5;
BA_ "Version" SG_ 2214659330 HEV_IndTqTar "18.05.04";
BA_ "GenMsgSendType" BO_ 2214659331 0;
BA_ "GenMsgCycleTime" BO_ 2214659331 50;
BA_ "GenMsgCycleTimeFast" BO_ 2214659331 0;
BA_ "GenMsgNrOfRepetition" BO_ 2214659331 0;
BA_ "VFrameFormat" BO_ 2214659331 1;
BA_ "GenMsgSendType" BO_ 2214659332 0;
BA_ "GenMsgCycleTime" BO_ 2214659332 50;
BA_ "GenMsgCycleTimeFast" BO_ 2214659332 0;
BA_ "GenMsgNrOfRepetition" BO_ 2214659332 0;
BA_ "VFrameFormat" BO_ 2214659332 1;
BA_ "GenMsgSendType" BO_ 2307024129 0;
BA_ "GenMsgCycleTimeFast" BO_ 2307024129 0;
BA_ "GenMsgNrOfRepetition" BO_ 2307024129 0;
BA_ "VFrameFormat" BO_ 2307024129 1;
BA_ "Description" SG_ 2307024129 EMS_Crc8Val "The data area for CRC calculation is based on the data length (DLC) of the message DB.

The CRC shall be calculated over the entire data block (excluding the CRC bytes) including the user data, alive counter and Data ID

 

- CRC Polynomial (0x1021) , Initial Value : 0xFFFF, XOR value : 0x0000, Data ID : Message ID + 0xF800 

- The initial value is for CRC calculation and the message should be sent with the calculated result value. 

- The mathematical expression to 16 bit CRC polynomial is given here. G(x) = x16 + x12 + x5 + 1";
BA_ "GenSigStartValue" SG_ 2307024129 EMS_Crc8Val 65535;
BA_ "UserSigValidity" SG_ 2307024129 EMS_Crc8Val 3;
BA_ "RoutingFactor" SG_ 2307024129 EMS_Crc8Val 2;
BA_ "Version" SG_ 2307024129 EMS_Crc8Val "18.11.08";
BA_ "Description" SG_ 2307024129 EMS_AlvCnt8Val "For the first transmission request for a data element the counter shall be initialized with 0 and shall be incremented by 1 for every subsequent send request. 

When the counter reaches the maximum value(0xFF), then it shall restart with 0 for the next send request";
BA_ "UserSigValidity" SG_ 2307024129 EMS_AlvCnt8Val 3;
BA_ "RoutingFactor" SG_ 2307024129 EMS_AlvCnt8Val 2;
BA_ "Version" SG_ 2307024129 EMS_AlvCnt8Val "18.11.08";
BA_ "Description" SG_ 2307024129 HEV_EngClntTempVal "Engine coolant temperature";
BA_ "UserSigValidity" SG_ 2307024129 HEV_EngClntTempVal 3;
BA_ "RoutingFactor" SG_ 2307024129 HEV_EngClntTempVal 2;
BA_ "Version" SG_ 2307024129 HEV_EngClntTempVal "17.11.00";
BA_ "Description" SG_ 2307024129 HEV_EngOilTempVal "Engine Oil Temperature";
BA_ "UserSigValidity" SG_ 2307024129 HEV_EngOilTempVal 3;
BA_ "RoutingFactor" SG_ 2307024129 HEV_EngOilTempVal 2;
BA_ "Version" SG_ 2307024129 HEV_EngOilTempVal "17.11.00";
BA_ "Description" SG_ 2307024129 HEV_VbOffActSta "ECU adaptive values and failure memory erase after battery disconnection";
BA_ "UserSigValidity" SG_ 2307024129 HEV_VbOffActSta 3;
BA_ "RoutingFactor" SG_ 2307024129 HEV_VbOffActSta 2;
BA_ "Version" SG_ 2307024129 HEV_VbOffActSta "17.11.00";
BA_ "Description" SG_ 2307024129 HEV_AirCompOffReq "air conditioner compressor off request";
BA_ "UserSigValidity" SG_ 2307024129 HEV_AirCompOffReq 3;
BA_ "RoutingFactor" SG_ 2307024129 HEV_AirCompOffReq 2;
BA_ "Version" SG_ 2307024129 HEV_AirCompOffReq "17.11.00";
BA_ "Description" SG_ 2307024129 HEV_MilConfgVal "Configuration of MIL handing and failure memory management";
BA_ "UserSigValidity" SG_ 2307024129 HEV_MilConfgVal 3;
BA_ "RoutingFactor" SG_ 2307024129 HEV_MilConfgVal 2;
BA_ "Version" SG_ 2307024129 HEV_MilConfgVal "17.11.00";
BA_ "Description" SG_ 2307024129 HEV_CF_EMS_LOCKUP "Engine lock up maintenance request state

0x0 : Engine doesn't require lock up maintenance

0x1 : Engine require lock up mainentance";
BA_ "UserSigValidity" SG_ 2307024129 HEV_CF_EMS_LOCKUP 3;
BA_ "RoutingFactor" SG_ 2307024129 HEV_CF_EMS_LOCKUP 2;
BA_ "Version" SG_ 2307024129 HEV_CF_EMS_LOCKUP "18.10.12";
BA_ "Description" SG_ 2307024129 HEV_OilLvlSta "This signal indicates the replace time of engine oil.";
BA_ "UserSigValidity" SG_ 2307024129 HEV_OilLvlSta 3;
BA_ "RoutingFactor" SG_ 2307024129 HEV_OilLvlSta 2;
BA_ "Version" SG_ 2307024129 HEV_OilLvlSta "20.12.04";
BA_ "Description" SG_ 2307024129 HEV_ImmoLmpReq "Immobilizer Lamp";
BA_ "UserSigValidity" SG_ 2307024129 HEV_ImmoLmpReq 3;
BA_ "RoutingFactor" SG_ 2307024129 HEV_ImmoLmpReq 2;
BA_ "Version" SG_ 2307024129 HEV_ImmoLmpReq "17.11.00";
BA_ "Description" SG_ 2307024129 HEV_MilReq "This signal indicates the status of MIL physical output.";
BA_ "UserSigValidity" SG_ 2307024129 HEV_MilReq 3;
BA_ "RoutingFactor" SG_ 2307024129 HEV_MilReq 2;
BA_ "Version" SG_ 2307024129 HEV_MilReq "17.11.00";
BA_ "Description" SG_ 2307024129 HEV_WiperSwSta "This signal indicates the status of a wiper switch.";
BA_ "UserSigValidity" SG_ 2307024129 HEV_WiperSwSta 3;
BA_ "RoutingFactor" SG_ 2307024129 HEV_WiperSwSta 2;
BA_ "Version" SG_ 2307024129 HEV_WiperSwSta "17.11.00";
BA_ "Description" SG_ 2307024129 HEV_FanOpSta "This signal indicates whether the cooling/condenser fan is operating or not.";
BA_ "UserSigValidity" SG_ 2307024129 HEV_FanOpSta 3;
BA_ "RoutingFactor" SG_ 2307024129 HEV_FanOpSta 2;
BA_ "Version" SG_ 2307024129 HEV_FanOpSta "17.11.00";
BA_ "Description" SG_ 2307024129 HEV_FanSta "This signal indicates the operating state of the cooling/condenser fan.";
BA_ "UserSigValidity" SG_ 2307024129 HEV_FanSta 3;
BA_ "RoutingFactor" SG_ 2307024129 HEV_FanSta 2;
BA_ "Version" SG_ 2307024129 HEV_FanSta "17.11.00";
BA_ "Description" SG_ 2307024129 HEV_BrkLtSwSta "Brake light Switch";
BA_ "UserSigValidity" SG_ 2307024129 HEV_BrkLtSwSta 3;
BA_REL_ "GenSigTimeoutTime" BU_SG_REL_ BLTN_CAM SG_ 2307024129 HEV_BrkLtSwSta 1500;
BA_ "RoutingFactor" SG_ 2307024129 HEV_BrkLtSwSta 2;
BA_ "Version" SG_ 2307024129 HEV_BrkLtSwSta "17.11.00";
BA_ "GenMsgSendType" BO_ 2307024130 0;
BA_ "GenMsgCycleTimeFast" BO_ 2307024130 0;
BA_ "GenMsgNrOfRepetition" BO_ 2307024130 0;
BA_ "VFrameFormat" BO_ 2307024130 1;
BA_ "Description" SG_ 2307024130 HEV_IgnCycCntVal "Number of driving cycle since first ECU power-up. The counter increases each time a driving cycle with engine running for a specified time duration is detected. This value is only initialized with 0 on saved RAM lost (or reprogramming).";
BA_ "UserSigValidity" SG_ 2307024130 HEV_IgnCycCntVal 3;
BA_ "RoutingFactor" SG_ 2307024130 HEV_IgnCycCntVal 2;
BA_ "Version" SG_ 2307024130 HEV_IgnCycCntVal "17.11.00";
BA_ "Description" SG_ 2307024130 HEV_SoakTimeVal "Engine soaking time";
BA_ "UserSigValidity" SG_ 2307024130 HEV_SoakTimeVal 3;
BA_ "RoutingFactor" SG_ 2307024130 HEV_SoakTimeVal 2;
BA_ "Version" SG_ 2307024130 HEV_SoakTimeVal "17.11.00";
BA_ "Description" SG_ 2307024130 HEV_SoakTimeErrSta "If the HEV_SoakTimeErrSta = 1 then the engine is in fuel cut off state, i.e. e. no injection is applied.";
BA_ "UserSigValidity" SG_ 2307024130 HEV_SoakTimeErrSta 3;
BA_ "RoutingFactor" SG_ 2307024130 HEV_SoakTimeErrSta 2;
BA_ "Version" SG_ 2307024130 HEV_SoakTimeErrSta "19.11.11";
BA_ "UserSigValidity" SG_ 2307024130 HEV_SoakTimeOvrSta 3;
BA_ "RoutingFactor" SG_ 2307024130 HEV_SoakTimeOvrSta 2;
BA_ "Version" SG_ 2307024130 HEV_SoakTimeOvrSta "18.12.01";
BA_ "UserSigValidity" SG_ 2307024130 HEV_FuelRunOutSta 3;
BA_ "RoutingFactor" SG_ 2307024130 HEV_FuelRunOutSta 2;
BA_ "Version" SG_ 2307024130 HEV_FuelRunOutSta "17.11.00";
BA_ "UserSigValidity" SG_ 2307024130 HEV_FuelRunOutDetSta 3;
BA_ "RoutingFactor" SG_ 2307024130 HEV_FuelRunOutDetSta 2;
BA_ "Version" SG_ 2307024130 HEV_FuelRunOutDetSta "17.11.00";
BA_ "Description" SG_ 2307024130 HEV_FuelCnsmptSumVal "Fuel Comsumption summed";
BA_ "UserSigValidity" SG_ 2307024130 HEV_FuelCnsmptSumVal 3;
BA_ "RoutingFactor" SG_ 2307024130 HEV_FuelCnsmptSumVal 2;
BA_ "Version" SG_ 2307024130 HEV_FuelCnsmptSumVal "17.11.00";
BA_ "GenMsgSendType" BO_ 2307024131 0;
BA_ "GenMsgCycleTimeFast" BO_ 2307024131 0;
BA_ "GenMsgNrOfRepetition" BO_ 2307024131 0;
BA_ "VFrameFormat" BO_ 2307024131 1;
BA_ "Description" SG_ 2307024131 HEV_EstClntTempVal "Estimated Engine Coolant Temperature";
BA_ "UserSigValidity" SG_ 2307024131 HEV_EstClntTempVal 3;
BA_ "RoutingFactor" SG_ 2307024131 HEV_EstClntTempVal 2;
BA_ "Version" SG_ 2307024131 HEV_EstClntTempVal "17.11.00";
BA_ "Description" SG_ 2307024131 HEV_EstAmbtAirTempVal "Estimated Ambient air temperature";
BA_ "GenSigStartValue" SG_ 2307024131 HEV_EstAmbtAirTempVal 91;
BA_ "UserSigValidity" SG_ 2307024131 HEV_EstAmbtAirTempVal 3;
BA_ "RoutingFactor" SG_ 2307024131 HEV_EstAmbtAirTempVal 2;
BA_ "Version" SG_ 2307024131 HEV_EstAmbtAirTempVal "17.11.00";
BA_ "Description" SG_ 2307024131 HEV_RbmSta "Status of rate-based monitoring



Value Description



Bit0 : minimum trip length condition 

Bit1 : vehicle speed condition 

Bit2 : continuous idle condition 

Bit3 : ambient temperature condition 

Bit4 : maximum altitude condition 

Bit5 : fuel engine operation

Bit6 : cold start condition for HEV";
BA_ "UserSigValidity" SG_ 2307024131 HEV_RbmSta 3;
BA_ "RoutingFactor" SG_ 2307024131 HEV_RbmSta 2;
BA_ "Version" SG_ 2307024131 HEV_RbmSta "19.11.11";
BA_ "Description" SG_ 2307024131 HEV_WarmUpReq_For_DATC "Flag indicating an EMS request not to stop the engine.

 * This signal is for reference on the DATC.

 * This signal is same as HEV_WarmUpReq (@EMS_09_10ms).";
BA_ "UserSigValidity" SG_ 2307024131 HEV_WarmUpReq_For_DATC 3;
BA_ "RoutingFactor" SG_ 2307024131 HEV_WarmUpReq_For_DATC 2;
BA_ "Version" SG_ 2307024131 HEV_WarmUpReq_For_DATC "19.09.04";
BA_ "Description" SG_ 2307024131 HEV_RbmInhbtSta "Inhibition of rate based monitoring";
BA_ "UserSigValidity" SG_ 2307024131 HEV_RbmInhbtSta 3;
BA_ "RoutingFactor" SG_ 2307024131 HEV_RbmInhbtSta 2;
BA_ "Version" SG_ 2307024131 HEV_RbmInhbtSta "17.11.00";
BA_ "Description" SG_ 2307024131 HEV_EhrsTempSta "The  signal is condition about EHRS' temperature";
BA_ "UserSigValidity" SG_ 2307024131 HEV_EhrsTempSta 3;
BA_ "RoutingFactor" SG_ 2307024131 HEV_EhrsTempSta 2;
BA_ "Version" SG_ 2307024131 HEV_EhrsTempSta "17.11.00";
BA_ "Description" SG_ 2307024131 HEV_Aaf_WrnLamp "Air Flap Warning Lamp/Message Request Signal indicates whether Warning Lamp/Message should be displayed in the display screen in order to warn AAF System failure to customer.";
BA_ "UserSigValidity" SG_ 2307024131 HEV_Aaf_WrnLamp 3;
BA_ "RoutingFactor" SG_ 2307024131 HEV_Aaf_WrnLamp 2;
BA_ "Version" SG_ 2307024131 HEV_Aaf_WrnLamp "19.11.11";
BA_ "Description" SG_ 2307024131 HEV_OPSFail "The signal indicates the status of the 'Oil Pressure Warning Lamp'";
BA_ "UserSigValidity" SG_ 2307024131 HEV_OPSFail 3;
BA_ "RoutingFactor" SG_ 2307024131 HEV_OPSFail 2;
BA_ "Version" SG_ 2307024131 HEV_OPSFail "18.05.04";
BA_ "Description" SG_ 2307024131 HEV_EngDsplceTyp "This signal indicates the engine displacement (volume).";
BA_ "UserSigValidity" SG_ 2307024131 HEV_EngDsplceTyp 3;
BA_ "RoutingFactor" SG_ 2307024131 HEV_EngDsplceTyp 2;
BA_ "Version" SG_ 2307024131 HEV_EngDsplceTyp "19.07.01";
BA_ "UserSigValidity" SG_ 2307024131 HEV_EngTyp2 3;
BA_ "RoutingFactor" SG_ 2307024131 HEV_EngTyp2 2;
BA_ "Version" SG_ 2307024131 HEV_EngTyp2 "19.07.01";
BA_ "UserSigValidity" SG_ 2307024131 HEV_EngTyp1 3;
BA_ "RoutingFactor" SG_ 2307024131 HEV_EngTyp1 2;
BA_ "Version" SG_ 2307024131 HEV_EngTyp1 "19.07.01";
BA_ "Description" SG_ 2307024131 HEV_S_F "AMS/ISG system type indicator";
BA_ "UserSigValidity" SG_ 2307024131 HEV_S_F 3;
BA_ "RoutingFactor" SG_ 2307024131 HEV_S_F 2;
BA_ "Version" SG_ 2307024131 HEV_S_F "19.07.01";
BA_ "Description" SG_ 2307024131 HEV_S_F_GEN "system generation type indicator";
BA_ "UserSigValidity" SG_ 2307024131 HEV_S_F_GEN 3;
BA_ "RoutingFactor" SG_ 2307024131 HEV_S_F_GEN 2;
BA_ "Version" SG_ 2307024131 HEV_S_F_GEN "19.07.01";
BA_ "Description" SG_ 2307024131 HEV_AptVal "APT Value";
BA_ "UserSigValidity" SG_ 2307024131 HEV_AptVal 3;
BA_ "RoutingFactor" SG_ 2307024131 HEV_AptVal 2;
BA_ "Version" SG_ 2307024131 HEV_AptVal "17.11.00";
BA_ "GenMsgSendType" BO_ 2307024132 0;
BA_ "GenMsgCycleTimeFast" BO_ 2307024132 0;
BA_ "GenMsgNrOfRepetition" BO_ 2307024132 0;
BA_ "VFrameFormat" BO_ 2307024132 1;
BA_ "Description" SG_ 2307024132 HEV_RbmSta_2nd "Status of rate-based monitoring



Value Description

Bit0 : cold start condition for PHEV

Bit1 : cold start inhibition condition for HEV/PHEV

Bit2 : reserved

Bit3 : reserved

Bit4 : reserved

Bit5 : reserved

Bit6 : reserved";
BA_ "UserSigValidity" SG_ 2307024132 HEV_RbmSta_2nd 3;
BA_ "RoutingFactor" SG_ 2307024132 HEV_RbmSta_2nd 2;
BA_ "Version" SG_ 2307024132 HEV_RbmSta_2nd "19.10.00";
BA_ "Description" SG_ 2307024132 HEV_OilLifeRatio "EMS calculates remaining engine oil life, and Cluster displays this information with % unit, in order to guide driver to change engine oil.";
BA_ "UserSigValidity" SG_ 2307024132 HEV_OilLifeRatio 3;
BA_ "RoutingFactor" SG_ 2307024132 HEV_OilLifeRatio 2;
BA_ "Version" SG_ 2307024132 HEV_OilLifeRatio "20.12.04";
BA_ "Description" SG_ 2307024132 HEV_OilLifeEna "Cluster displays engine oil life warning and life ratio signal if this enabling bit is true.";
BA_ "UserSigValidity" SG_ 2307024132 HEV_OilLifeEna 3;
BA_ "RoutingFactor" SG_ 2307024132 HEV_OilLifeEna 2;
BA_ "Version" SG_ 2307024132 HEV_OilLifeEna "20.12.04";
BA_ "Description" SG_ 2307024132 HEV_OilLifeWarn "This signal indicates status of engine oil life warning.";
BA_ "UserSigValidity" SG_ 2307024132 HEV_OilLifeWarn 3;
BA_ "RoutingFactor" SG_ 2307024132 HEV_OilLifeWarn 2;
BA_ "Version" SG_ 2307024132 HEV_OilLifeWarn "20.12.04";
BA_ "Description" SG_ 2307024132 HEV_RECTrigSta "Trigger signal(10 event) - when REC is occurred in the HEV ECU(Engine controller)";
BA_ "UserSigValidity" SG_ 2307024132 HEV_RECTrigSta 3;
BA_ "RoutingFactor" SG_ 2307024132 HEV_RECTrigSta 2;
BA_ "Version" SG_ 2307024132 HEV_RECTrigSta "20.02.02";
BA_ "Description" SG_ 2307024132 HEV_PendingTrigSta "Trigger signal(10 event) - when Pending DTC is occurred in the HEV ECU(Engine controller)";
BA_ "UserSigValidity" SG_ 2307024132 HEV_PendingTrigSta 3;
BA_ "RoutingFactor" SG_ 2307024132 HEV_PendingTrigSta 2;
BA_ "Version" SG_ 2307024132 HEV_PendingTrigSta "20.02.02";
BA_ "GenMsgSendType" BO_ 2244048129 0;
BA_ "GenMsgCycleTime" BO_ 2244048129 100;
BA_ "GenMsgCycleTimeFast" BO_ 2244048129 0;
BA_ "GenMsgNrOfRepetition" BO_ 2244048129 0;
BA_ "VFrameFormat" BO_ 2244048129 1;
BA_ "Description" SG_ 2244048129 ESC_Crc3Val "The data area for CRC calculation is based on the data length (DLC) of the message DB.

The CRC shall be calculated over the entire data block (excluding the CRC bytes) including the user data, alive counter and Data ID

 

- CRC Polynomial (0x1021) , Initial Value : 0xFFFF, XOR value : 0x0000, Data ID : Message ID + 0xF800 

- The initial value is for CRC calculation and the message should be sent with the calculated result value. 

- The mathematical expression to 16 bit CRC polynomial is given here. G(x) = x16 + x12 + x5 + 1";
BA_ "GenSigStartValue" SG_ 2244048129 ESC_Crc3Val 65535;
BA_ "UserSigValidity" SG_ 2244048129 ESC_Crc3Val 3;
BA_ "RoutingFactor" SG_ 2244048129 ESC_Crc3Val 5;
BA_ "Version" SG_ 2244048129 ESC_Crc3Val "18.11.08";
BA_ "Description" SG_ 2244048129 ESC_AlvCnt3Val "For the first transmission request for a data element the counter shall be initialized with 0 and shall be incremented by 1 for every subsequent send request. 

When the counter reaches the maximum value(0xFF), then it shall restart with 0 for the next send request";
BA_ "UserSigValidity" SG_ 2244048129 ESC_AlvCnt3Val 3;
BA_ "RoutingFactor" SG_ 2244048129 ESC_AlvCnt3Val 5;
BA_ "Version" SG_ 2244048129 ESC_AlvCnt3Val "18.11.08";
BA_ "Description" SG_ 2244048129 SCC_TqIntrvntnVal "The indicated torque command TQI_ACC is the basic control path to the engine power control. This command has the same priority in the torque-structure than the driver¡¯s demand torque. The maximum value of either TQI_ACC or the driver torque is selected fo";
BA_ "UserSigValidity" SG_ 2244048129 SCC_TqIntrvntnVal 3;
BA_ "RoutingFactor" SG_ 2244048129 SCC_TqIntrvntnVal 5;
BA_ "Version" SG_ 2244048129 SCC_TqIntrvntnVal "17.12.00";
BA_ "Description" SG_ 2244048129 ESC_VehAccelVal "The vehicle acceleration ACCEL_REF_ACC displays the feedback signal for the inner acceleration control loop since it is the SCC-internal acceleration command value. In addition this signal is used to calculate the target object acceleration. If the requirements demanded from this signal can¡¯t be guaranteed then SCC must be informed and SCC has to be switched off.

Alternatively SCC may calculate the vehicle acceleration itself. Then the wheel speed vxvTyrexx (or the wheel speed row signals vxvTyreRawxx and the wheel tolerances radTolxx of below diagram) should be

transmitted by TCS or ESC.";
BA_ "UserSigValidity" SG_ 2244048129 ESC_VehAccelVal 3;
BA_ "RoutingFactor" SG_ 2244048129 ESC_VehAccelVal 5;
BA_ "Version" SG_ 2244048129 ESC_VehAccelVal "17.12.00";
BA_ "Description" SG_ 2244048129 ESC_AccelBasisVal "This value is used to initialize the acceleration control when SCC is engaged or after driver override.";
BA_ "UserSigValidity" SG_ 2244048129 ESC_AccelBasisVal 3;
BA_ "RoutingFactor" SG_ 2244048129 ESC_AccelBasisVal 5;
BA_ "Version" SG_ 2244048129 ESC_AccelBasisVal "17.12.00";
BA_ "Description" SG_ 2244048129 PWI_STATE "This signal indicates brake pad wear state. If the brake pad is worn to the designted amount, this signal is used to indicate the alarm on the cluster";
BA_ "UserSigValidity" SG_ 2244048129 PWI_STATE 3;
BA_ "RoutingFactor" SG_ 2244048129 PWI_STATE 5;
BA_ "Version" SG_ 2244048129 PWI_STATE "21.04.02";
BA_ "GenMsgSendType" BO_ 2244048130 0;
BA_ "GenMsgCycleTime" BO_ 2244048130 100;
BA_ "GenMsgCycleTimeFast" BO_ 2244048130 0;
BA_ "GenMsgNrOfRepetition" BO_ 2244048130 0;
BA_ "VFrameFormat" BO_ 2244048130 1;
BA_ "Description" SG_ 2244048130 SCC_OptTyp "This value is used for SCC is equipped or not.

Do not recognize 0x3(Not Coded) as failure.";
BA_ "UserSigValidity" SG_ 2244048130 SCC_OptTyp 3;
BA_ "RoutingFactor" SG_ 2244048130 SCC_OptTyp 5;
BA_ "Version" SG_ 2244048130 SCC_OptTyp "18.12.04";
BA_ "Description" SG_ 2244048130 ESC_BrkLtReq "Flag from TCS which activates the illumination of the brake lights during automatic braking.";
BA_ "UserSigValidity" SG_ 2244048130 ESC_BrkLtReq 3;
BA_ "RoutingFactor" SG_ 2244048130 ESC_BrkLtReq 5;
BA_ "Version" SG_ 2244048130 ESC_BrkLtReq "17.12.00";
BA_ "Description" SG_ 2244048130 ESC_DclEnblReq "This signal enables the deceleration control to accept command values axvCv from SCC. This flag is complementary to the ACC_REQ flag if SCC is in active mode.";
BA_ "UserSigValidity" SG_ 2244048130 ESC_DclEnblReq 3;
BA_ "RoutingFactor" SG_ 2244048130 ESC_DclEnblReq 5;
BA_ "Version" SG_ 2244048130 ESC_DclEnblReq "17.12.00";
BA_ "Description" SG_ 2244048130 ESC_DrvOvrdSta "This signal indicates that acceleration or deceleration value of driver¡¯s requirement is greater than SCC setting value.";
BA_ "UserSigValidity" SG_ 2244048130 ESC_DrvOvrdSta 3;
BA_ "RoutingFactor" SG_ 2244048130 ESC_DrvOvrdSta 5;
BA_ "Version" SG_ 2244048130 ESC_DrvOvrdSta "17.12.00";
BA_ "Description" SG_ 2244048130 ESC_DrvBrkSta "This signal indicates flag from ESC to SCC to indicate the driver braking state";
BA_ "UserSigValidity" SG_ 2244048130 ESC_DrvBrkSta 3;
BA_ "RoutingFactor" SG_ 2244048130 ESC_DrvBrkSta 5;
BA_ "Version" SG_ 2244048130 ESC_DrvBrkSta "17.12.00";
BA_ "Description" SG_ 2244048130 SCC_EnblReq "This signal is set by the safety logic in the TCS/ESC. The safety logic shall monitor the following:

1. A temporary failure in the vehicle does not allow SCC (Brakes are overheated, etc¡¦). 

SCC is disabled reversible.

2. SCC communication failure (timeout";
BA_ "UserSigValidity" SG_ 2244048130 SCC_EnblReq 3;
BA_ "RoutingFactor" SG_ 2244048130 SCC_EnblReq 5;
BA_ "Version" SG_ 2244048130 SCC_EnblReq "17.12.00";
BA_ "Description" SG_ 2244048130 ESC_DrvBrkActvSta "This signal indicates that a driver is pressing the brake pedal or not.";
BA_ "UserSigValidity" SG_ 2244048130 ESC_DrvBrkActvSta 3;
BA_ "RoutingFactor" SG_ 2244048130 ESC_DrvBrkActvSta 5;
BA_ "Version" SG_ 2244048130 ESC_DrvBrkActvSta "17.12.00";
BA_ "Description" SG_ 2244048130 ESC_PrkBrkActvSta "This signal indicates whether the parking brake is activated or not.";
BA_ "UserSigValidity" SG_ 2244048130 ESC_PrkBrkActvSta 3;
BA_ "RoutingFactor" SG_ 2244048130 ESC_PrkBrkActvSta 5;
BA_ "Version" SG_ 2244048130 ESC_PrkBrkActvSta "17.12.00";
BA_ "Description" SG_ 2244048130 ESC_HDP_FltMonSta "ÀÌ ½ÅÈ£´Â IEB (ESC)°¡ HDP Á¦¾î±â(Main/Sub)ÀÇ »óÅÂ¸¦ ¸ð´ÏÅÍ¸µÇÑ °á°úÀÌ´Ù.

This signal is the result of the IEB (ESC) monitoring the state of the HDP controller (Main/Sub).";
BA_ "UserSigValidity" SG_ 2244048130 ESC_HDP_FltMonSta 3;
BA_REL_ "GenSigTimeoutTime" BU_SG_REL_ PSB SG_ 2244048130 ESC_HDP_FltMonSta 1500;
BA_ "RoutingFactor" SG_ 2244048130 ESC_HDP_FltMonSta 5;
BA_ "Version" SG_ 2244048130 ESC_HDP_FltMonSta "21.04.00";
BA_ "Description" SG_ 2244048130 FCA_EquipSta "FCA Equipment Status

Do not recognize 0x3(Not Coded) as failure.";
BA_ "UserSigValidity" SG_ 2244048130 FCA_EquipSta 3;
BA_ "RoutingFactor" SG_ 2244048130 FCA_EquipSta 5;
BA_ "Version" SG_ 2244048130 FCA_EquipSta "18.12.04";
BA_ "Description" SG_ 2244048130 FCA_AvlblSta "This signal indicates state signal from ESC to FCA which tells if ESC is 'Available', 'Temporarily not available', 'Permanently not available' or 'FCA Communication Error'.";
BA_ "UserSigValidity" SG_ 2244048130 FCA_AvlblSta 3;
BA_ "RoutingFactor" SG_ 2244048130 FCA_AvlblSta 5;
BA_ "Version" SG_ 2244048130 FCA_AvlblSta "18.02.00";
BA_ "Description" SG_ 2244048130 ESC_FCA_ActvSta "This signal specifies the status of control for FCA control request flag.

(FCA Á¦¾î ¿äÃ»¿¡ ´ëÇÑ Á¦µ¿ Á¦¾î±â ¼öÇà¿©ºÎ È®ÀÎÀ» À§ÇÑ Á¤º¸ ½ÅÈ£)";
BA_ "UserSigValidity" SG_ 2244048130 ESC_FCA_ActvSta 3;
BA_ "RoutingFactor" SG_ 2244048130 ESC_FCA_ActvSta 5;
BA_ "Version" SG_ 2244048130 ESC_FCA_ActvSta "19.11.02";
BA_ "Description" SG_ 2244048130 ESC_DBS_ActvSta "This signal specifies the status of control for DBS flag.

(DBS Á¦¾î ¿äÃ»¿¡ ´ëÇÑ Á¦µ¿ Á¦¾î±â ¼öÇà¿©ºÎ È®ÀÎ À§ÇÑ Á¤º¸ ½ÅÈ£)";
BA_ "UserSigValidity" SG_ 2244048130 ESC_DBS_ActvSta 3;
BA_ "RoutingFactor" SG_ 2244048130 ESC_DBS_ActvSta 5;
BA_ "Version" SG_ 2244048130 ESC_DBS_ActvSta "19.11.02";
BA_ "Description" SG_ 2244048130 SCC_TqReq "When it is set, the signal indicates that ESC requests engine torque control for SCC. When the signal is set, EMS should not conduct fuel-cut off control unless it is required to prevent the damage of the engine and the related components.";
BA_ "UserSigValidity" SG_ 2244048130 SCC_TqReq 3;
BA_ "RoutingFactor" SG_ 2244048130 SCC_TqReq 5;
BA_ "Version" SG_ 2244048130 SCC_TqReq "17.12.00";
BA_ "Description" SG_ 2244048130 ESC_HDP_EgSta "ÀÌ ½ÅÈ£´Â IEB (ESC) / RCU°¡ ¿¬°áµÈ HDP ÄÁÆ®·Ñ·¯ (¸ÞÀÎ / ¼­ºê)ÀÇ Á¤º¸ÀÔ´Ï´Ù.

This signal is the information which of the HDP controllers (Main/Sub) the IEB (ESC)/RCU is engaged.



IEB/RCU°¡ Main/Sub Á¦¾î±âÀÇ ÇùÁ¶Á¦¾î ´ëÀÀ»óÅÂ¸¦ ¾Ë·ÁÁÖ´Â ½ÅÈ£ (Engage)

0x0: Not engaged (HDP °ü·ÃÇÏ¿© ´ëÀÀÇÏÁö ¾Ê´Â »óÅÂ)

0x1: Engaged in main controller by IEB (ESC) (ADAS_DRV 2ÀÇ ½ÅÈ£¸¦ ¼ö½ÅÇÏ¿© ÀÛµ¿ÇÏ´Â »óÅÂ)

0x2: Engaged in sub controller by IEB (ESC) (FR_CMRÀÇ ½ÅÈ£¸¦ ¼ö½ÅÇÏ¿© ÀÛµ¿ÇÏ´Â »óÅÂ)

0x3: MRM with IEB (ESC) alone by IEB (ESC) (IEB ´Üµ¶ MRM ÀÛµ¿ »óÅÂ)

0x4: Engaged in main controller by RCU (ADAS_DRV 2ÀÇ ½ÅÈ£¸¦ ¼ö½ÅÇÏ¿© ÀÛµ¿ÇÏ´Â »óÅÂ)

0x5: Engaged in sub controller by RCU (FR_CMRÀÇ ½ÅÈ£¸¦ ¼ö½ÅÇÏ¿© ÀÛµ¿ÇÏ´Â »óÅÂ)

0x6: MRM with IEB (ESC) alone by RCU (RCU ´Üµ¶ MRM ÀÛµ¿ »óÅÂ)

0x7: Reserved";
BA_ "UserSigValidity" SG_ 2244048130 ESC_HDP_EgSta 3;
BA_ "RoutingFactor" SG_ 2244048130 ESC_HDP_EgSta 5;
BA_ "Version" SG_ 2244048130 ESC_HDP_EgSta "21.04.00";
BA_ "Description" SG_ 2244048130 ESC_HDP_EnblReq "ÀÌ ½ÅÈ£´Â HDP ±â´ÉÀ» ´ëÀÀÇÏ±â À§ÇÑ IEB (ESC)ÀÇ °íÀå»óÅÂÀÌ´Ù.

This signal is a fault state of the IEB (ESC) for the HDP function.



IEB/RCU°¡ ÀÚÃ¼ÀûÀ¸·Î HDP °ü·Ã °íÀåÀ» ÆÇ´ÜÇÏ¿© ´ëÀÀ °¡´É »óÅÂ¸¦ ¼¼ºÐÈ­ÇÏ¿© ¾Ë·ÁÁÖ´Â ½ÅÈ£

0x0: Á¤»óÀÛµ¿ »óÈ²

0x1: ÇùÁ¶Á¦¾î »ç¾ç¿¡ Á¤ÀÇµÈ ±â´ÉÀûÀÎ ÀÛµ¿À» Á¤»óÀûÀ¸·Î ¼öÇàÇÒ ¼ö ¾ø´Â °æ¿ì

0x2: ¿ä±¸°¡¼Óµµ ÃßÁ¾Á¦¾î ½Ã ÀÏºÎ ¼º´ÉÀúÇÏ°¡ ¹ß»ýÇÒ ¼ö ÀÖ´Â »óÈ²

0x3: ¿ä±¸°¡¼Óµµ ÃßÁ¾Á¦¾î¸¦ ¼öÇàÇÒ ¾øÁö¸¸ Á¦µ¿Á¦¾î´Â °¡´ÉÇÑ »óÈ²

0x4: ¿ä±¸°¡¼Óµµ ÃßÁ¾Á¦¾î ¹× Á¦µ¿Á¦¾î°¡ ºÒ°¡´ÉÇÑ »óÈ²

0x5: ¿ä±¸°¡¼Óµµ ÃßÁ¾Á¦¾î¸¦ ¼öÇàÇÒ ¼ö ÀÖÀ¸³ª ±¸µ¿Á¦¾î°¡ ºÒ°¡´ÉÇÑ »óÈ²

0x6~7: Reserved";
BA_ "UserSigValidity" SG_ 2244048130 ESC_HDP_EnblReq 3;
BA_ "RoutingFactor" SG_ 2244048130 ESC_HDP_EnblReq 5;
BA_ "Version" SG_ 2244048130 ESC_HDP_EnblReq "21.04.00";
BA_ "Description" SG_ 2244048130 ESC_BrkdFltStndstill "The signal indicates state when vehicle is braked, flatland and standstill";
BA_ "UserSigValidity" SG_ 2244048130 ESC_BrkdFltStndstill 3;
BA_ "RoutingFactor" SG_ 2244048130 ESC_BrkdFltStndstill 5;
BA_ "Version" SG_ 2244048130 ESC_BrkdFltStndstill "20.12.04";
BA_ "Description" SG_ 2244048130 SCC_ReqLimSta "Due to limitaion of the actuators the acceleration or deceleration request from SCC can not be processed or only partly. 



Examples:

1. SCC is requesting more acceleration than the engine can deliver.

2. SCC is requesting deceleration on a low ¥ì surface.";
BA_ "UserSigValidity" SG_ 2244048130 SCC_ReqLimSta 3;
BA_ "RoutingFactor" SG_ 2244048130 SCC_ReqLimSta 5;
BA_ "Version" SG_ 2244048130 SCC_ReqLimSta "17.12.00";
BA_ "Description" SG_ 2244048130 ESC_StdStillVal "If an ESC uses active wheel speed sensors, wheel speeds down to 0 Km/h can be measured. And at 0 Km/h a StandStill flag is set in the ESC. This signal is used in the offset determination of the yaw rate and shall indicate that the vehicle has come to a complete stop.";
BA_ "UserSigValidity" SG_ 2244048130 ESC_StdStillVal 3;
BA_ "RoutingFactor" SG_ 2244048130 ESC_StdStillVal 5;
BA_ "Version" SG_ 2244048130 ESC_StdStillVal "17.12.00";
BA_ "GenMsgSendType" BO_ 2244048131 0;
BA_ "GenMsgCycleTime" BO_ 2244048131 100;
BA_ "GenMsgCycleTimeFast" BO_ 2244048131 0;
BA_ "GenMsgNrOfRepetition" BO_ 2244048131 0;
BA_ "VFrameFormat" BO_ 2244048131 1;
BA_ "Description" SG_ 2244048131 ESC_RccaSta "RCCA Brake Function Status";
BA_ "UserSigValidity" SG_ 2244048131 ESC_RccaSta 3;
BA_ "RoutingFactor" SG_ 2244048131 ESC_RccaSta 5;
BA_ "Version" SG_ 2244048131 ESC_RccaSta "17.12.00";
BA_ "Description" SG_ 2244048131 ESC_RspaCanFlFlag "This signal indicates RSPA CAN failure value.

E.g. Timeout, CRC error, Alive counter error, out of range signal value¡¦";
BA_ "UserSigValidity" SG_ 2244048131 ESC_RspaCanFlFlag 3;
BA_ "RoutingFactor" SG_ 2244048131 ESC_RspaCanFlFlag 5;
BA_ "Version" SG_ 2244048131 ESC_RspaCanFlFlag "17.12.00";
BA_ "Description" SG_ 2244048131 ESC_RspaDclActv "This signal indicates the additional braking control is activated for RSPA.

ESC activate additional deceleration to minimize vehicle speed overshoot.";
BA_ "UserSigValidity" SG_ 2244048131 ESC_RspaDclActv 3;
BA_ "RoutingFactor" SG_ 2244048131 ESC_RspaDclActv 5;
BA_ "Version" SG_ 2244048131 ESC_RspaDclActv "17.12.00";
BA_ "Description" SG_ 2244048131 ESC_RspaStandStill "This signal indicates confirmation for standstill of the vehicle.";
BA_ "UserSigValidity" SG_ 2244048131 ESC_RspaStandStill 3;
BA_ "RoutingFactor" SG_ 2244048131 ESC_RspaStandStill 5;
BA_ "Version" SG_ 2244048131 ESC_RspaStandStill "17.12.00";
BA_ "Description" SG_ 2244048131 ESC_PcaSta "PCA-R Brake Status";
BA_ "UserSigValidity" SG_ 2244048131 ESC_PcaSta 3;
BA_ "RoutingFactor" SG_ 2244048131 ESC_PcaSta 5;
BA_ "Version" SG_ 2244048131 ESC_PcaSta "17.12.06";
BA_ "Description" SG_ 2244048131 MCB_ReqBrkAck "This signal is about communication with ACU. It is changed with ACU_ReqBrk_By_PCB signal value.

If ESC receive 0x1 or 0x2 value of ACU_ReqBrk_By_PCB, signal value of MCB_ReqBrkAck change to 0x1.

If ESC receive 0x0 value of ACU_ReqBrk_By_PCB, signal value of MCB_ReqBrkAck change to 0x0.";
BA_ "UserSigValidity" SG_ 2244048131 MCB_ReqBrkAck 3;
BA_ "RoutingFactor" SG_ 2244048131 MCB_ReqBrkAck 5;
BA_ "Version" SG_ 2244048131 MCB_ReqBrkAck "18.12.05";
BA_ "Description" SG_ 2244048131 MCB_CtlSta "This signal indicate MCB activation status.";
BA_ "UserSigValidity" SG_ 2244048131 MCB_CtlSta 3;
BA_ "RoutingFactor" SG_ 2244048131 MCB_CtlSta 5;
BA_ "Version" SG_ 2244048131 MCB_CtlSta "19.05.02";
BA_ "Description" SG_ 2244048131 MCB_DefSta "This signal indicate MCB defective status.";
BA_ "UserSigValidity" SG_ 2244048131 MCB_DefSta 3;
BA_ "RoutingFactor" SG_ 2244048131 MCB_DefSta 5;
BA_ "Version" SG_ 2244048131 MCB_DefSta "19.05.02";
BA_ "Description" SG_ 2244048131 ESC_DiffBrkFuncSta "This is ESC status for Differential brake function.";
BA_ "UserSigValidity" SG_ 2244048131 ESC_DiffBrkFuncSta 3;
BA_ "RoutingFactor" SG_ 2244048131 ESC_DiffBrkFuncSta 5;
BA_ "Version" SG_ 2244048131 ESC_DiffBrkFuncSta "17.12.00";
BA_ "Description" SG_ 2244048131 ESC_LsdLimMod "This signal indicates the request for eLSD torque limit mode.

0x0:Maximum limitation mode

0x1:Minimum limitation mode";
BA_ "UserSigValidity" SG_ 2244048131 ESC_LsdLimMod 3;
BA_ "RoutingFactor" SG_ 2244048131 ESC_LsdLimMod 5;
BA_ "Version" SG_ 2244048131 ESC_LsdLimMod "18.05.02";
BA_ "Description" SG_ 2244048131 ESC_LsdOpn "This signal indicates the command for eLSD clutch open mode.";
BA_ "UserSigValidity" SG_ 2244048131 ESC_LsdOpn 3;
BA_ "RoutingFactor" SG_ 2244048131 ESC_LsdOpn 5;
BA_ "Version" SG_ 2244048131 ESC_LsdOpn "20.08.05";
BA_ "Description" SG_ 2244048131 ESC_LsdTqLim "This signal indicates the request for the value of the torquel limit of eLSD.

0xFFFF : Error";
BA_ "GenSigStartValue" SG_ 2244048131 ESC_LsdTqLim 64255;
BA_ "UserSigValidity" SG_ 2244048131 ESC_LsdTqLim 3;
BA_ "RoutingFactor" SG_ 2244048131 ESC_LsdTqLim 5;
BA_ "Version" SG_ 2244048131 ESC_LsdTqLim "18.05.02";
BA_ "Description" SG_ 2244048131 ESC_BcaRPlusSta "BCA-R+ Brake Function Status";
BA_ "UserSigValidity" SG_ 2244048131 ESC_BcaRPlusSta 3;
BA_ "RoutingFactor" SG_ 2244048131 ESC_BcaRPlusSta 5;
BA_ "Version" SG_ 2244048131 ESC_BcaRPlusSta "17.12.07";
BA_ "Description" SG_ 2244048131 ESC_RspaSta "This signal indicates RSPA assistant control mode of ESC";
BA_ "GenSigStartValue" SG_ 2244048131 ESC_RspaSta 1;
BA_ "UserSigValidity" SG_ 2244048131 ESC_RspaSta 3;
BA_ "RoutingFactor" SG_ 2244048131 ESC_RspaSta 5;
BA_ "Version" SG_ 2244048131 ESC_RspaSta "17.12.00";
BA_ "GenMsgSendType" BO_ 721 0;
BA_ "GenMsgCycleTime" BO_ 721 100;
BA_ "GenMsgCycleTimeFast" BO_ 721 0;
BA_ "GenMsgNrOfRepetition" BO_ 721 0;
BA_ "Description" SG_ 721 HU_DR_Position_Status "0x1:Valid";
BA_ "UserSigValidity" SG_ 721 HU_DR_Position_Status 1;
BA_ "Version" SG_ 721 HU_DR_Position_Status "21.08.01";
BA_ "Description" SG_ 721 HU_DR_Altitude_Status "0x1=Valid";
BA_ "UserSigValidity" SG_ 721 HU_DR_Altitude_Status 1;
BA_ "Version" SG_ 721 HU_DR_Altitude_Status "21.08.01";
BA_ "Description" SG_ 721 HU_DR_Altitude "MSL";
BA_ "UserSigValidity" SG_ 721 HU_DR_Altitude 1;
BA_REL_ "GenSigTimeoutTime" BU_SG_REL_ BLTN_CAM SG_ 721 HU_DR_Altitude 1500;
BA_ "Version" SG_ 721 HU_DR_Altitude "21.08.01";
BA_ "Description" SG_ 721 HU_DR_Heading_Status "0x1=Valid";
BA_ "UserSigValidity" SG_ 721 HU_DR_Heading_Status 1;
BA_ "Version" SG_ 721 HU_DR_Heading_Status "21.08.01";
BA_ "Description" SG_ 721 HU_DR_Speed_Status "0x1=Valid";
BA_ "UserSigValidity" SG_ 721 HU_DR_Speed_Status 1;
BA_ "Version" SG_ 721 HU_DR_Speed_Status "21.08.01";
BA_ "Description" SG_ 721 HU_DR_DirectionSwitch_Sta "0x1=valid";
BA_ "UserSigValidity" SG_ 721 HU_DR_DirectionSwitch_Sta 1;
BA_ "Version" SG_ 721 HU_DR_DirectionSwitch_Sta "21.08.01";
BA_ "Description" SG_ 721 HU_DR_Direction "0x1=Backward";
BA_ "UserSigValidity" SG_ 721 HU_DR_Direction 1;
BA_ "Version" SG_ 721 HU_DR_Direction "21.08.01";
BA_ "Description" SG_ 721 HU_DR_GyroCalib_Sta "0x1=Calibrated";
BA_ "UserSigValidity" SG_ 721 HU_DR_GyroCalib_Sta 1;
BA_ "Version" SG_ 721 HU_DR_GyroCalib_Sta "21.08.01";
BA_ "Description" SG_ 721 HU_DR_TachoCalib_Sta "0x1=Calibrated";
BA_ "UserSigValidity" SG_ 721 HU_DR_TachoCalib_Sta 1;
BA_ "Version" SG_ 721 HU_DR_TachoCalib_Sta "21.08.01";
BA_ "Description" SG_ 721 HU_DR_Solution_Sta "0x1 : Dr is fully calibrated and DR position is valid";
BA_ "UserSigValidity" SG_ 721 HU_DR_Solution_Sta 1;
BA_ "Version" SG_ 721 HU_DR_Solution_Sta "21.08.01";
BA_ "Description" SG_ 721 HU_DR_GNSS_Fix_Age "0-254 = Time since last GNSS fix

255= No GNSS fix yet";
BA_ "UserSigValidity" SG_ 721 HU_DR_GNSS_Fix_Age 1;
BA_ "Version" SG_ 721 HU_DR_GNSS_Fix_Age "21.08.01";
BA_ "GenMsgSendType" BO_ 722 0;
BA_ "GenMsgCycleTime" BO_ 722 100;
BA_ "GenMsgCycleTimeFast" BO_ 722 0;
BA_ "GenMsgNrOfRepetition" BO_ 722 0;
BA_ "UserSigValidity" SG_ 722 HU_DR_Latitude 1;
BA_REL_ "GenSigTimeoutTime" BU_SG_REL_ BLTN_CAM SG_ 722 HU_DR_Latitude 1500;
BA_ "Version" SG_ 722 HU_DR_Latitude "21.08.01";
BA_ "UserSigValidity" SG_ 722 HU_DR_Longitude 1;
BA_REL_ "GenSigTimeoutTime" BU_SG_REL_ BLTN_CAM SG_ 722 HU_DR_Longitude 1500;
BA_ "Version" SG_ 722 HU_DR_Longitude "21.08.01";
BA_ "GenMsgSendType" BO_ 723 0;
BA_ "GenMsgCycleTime" BO_ 723 100;
BA_ "GenMsgCycleTimeFast" BO_ 723 0;
BA_ "GenMsgNrOfRepetition" BO_ 723 0;
BA_ "UserSigValidity" SG_ 723 HU_DR_Heading 1;
BA_REL_ "GenSigTimeoutTime" BU_SG_REL_ BLTN_CAM SG_ 723 HU_DR_Heading 1500;
BA_ "Version" SG_ 723 HU_DR_Heading "21.08.01";
BA_ "Description" SG_ 723 HU_DR_Speed "negative if the direction is backward.";
BA_ "UserSigValidity" SG_ 723 HU_DR_Speed 1;
BA_ "Version" SG_ 723 HU_DR_Speed "21.08.01";
BA_ "GenMsgSendType" BO_ 2164277249 0;
BA_ "GenMsgCycleTime" BO_ 2164277249 50;
BA_ "GenMsgCycleTimeFast" BO_ 2164277249 0;
BA_ "GenMsgNrOfRepetition" BO_ 2164277249 0;
BA_ "VFrameFormat" BO_ 2164277249 1;
BA_ "Description" SG_ 2164277249 TCU_Crc1Val "The data area for CRC calculation is based on the data length (DLC) of the message DB.

The CRC shall be calculated over the entire data block (excluding the CRC bytes) including the user data, alive counter and Data ID

 

- CRC Polynomial (0x1021) , Initial Value : 0xFFFF, XOR value : 0x0000, Data ID : Message ID + 0xF800 

- The initial value is for CRC calculation and the message should be sent with the calculated result value. 

- The mathematical expression to 16 bit CRC polynomial is given here. G(x) = x16 + x12 + x5 + 1";
BA_ "GenSigStartValue" SG_ 2164277249 TCU_Crc1Val 65535;
BA_ "UserSigValidity" SG_ 2164277249 TCU_Crc1Val 3;
BA_ "RoutingFactor" SG_ 2164277249 TCU_Crc1Val 5;
BA_ "Version" SG_ 2164277249 TCU_Crc1Val "18.11.08";
BA_ "Description" SG_ 2164277249 TCU_AlvCnt1Val "For the first transmission request for a data element the counter shall be initialized with 0 and shall be incremented by 1 for every subsequent send request. 

When the counter reaches the maximum value(0xFF), then it shall restart with 0 for the next send request";
BA_ "UserSigValidity" SG_ 2164277249 TCU_AlvCnt1Val 3;
BA_ "RoutingFactor" SG_ 2164277249 TCU_AlvCnt1Val 5;
BA_ "Version" SG_ 2164277249 TCU_AlvCnt1Val "18.11.08";
BA_ "Description" SG_ 2164277249 TCU_GearSlctDis "Position (P, R, N..), which was identified by the gear selector.

In case the gear selector is in a intermediate position, the last clear recognized position is used.

There is no specific phase relationship between the output and any other signal.";
BA_ "GenSigStartValue" SG_ 2164277249 TCU_GearSlctDis 9;
BA_ "UserSigValidity" SG_ 2164277249 TCU_GearSlctDis 3;
BA_ "RoutingFactor" SG_ 2164277249 TCU_GearSlctDis 5;
BA_ "Version" SG_ 2164277249 TCU_GearSlctDis "17.11.00";
BA_ "Description" SG_ 2164277249 TCU_Typ "Information regarding the type of transmission - Step A/T or CVT or DCT / AMT / eClutch";
BA_ "UserSigValidity" SG_ 2164277249 TCU_Typ 3;
BA_ "RoutingFactor" SG_ 2164277249 TCU_Typ 5;
BA_ "Version" SG_ 2164277249 TCU_Typ "18.12.02";
BA_ "Description" SG_ 2164277249 TCU_TqRdctnVal "The TCU requests a torque reduction via this signal to the EMS. 



If MSB is 1, this signal is - value.

else, this signal is +value.

0~10bit is used for absolute value.";
BA_ "GenSigStartValue" SG_ 2164277249 TCU_TqRdctnVal 2047;
BA_ "UserSigValidity" SG_ 2164277249 TCU_TqRdctnVal 3;
BA_ "RoutingFactor" SG_ 2164277249 TCU_TqRdctnVal 5;
BA_ "Version" SG_ 2164277249 TCU_TqRdctnVal "20.03.05";
BA_ "Description" SG_ 2164277249 TCU_GearStepTyp "This signal indicates number of gear steps of step type automatic transmission(A/T) or Dual Clutch Transmission(DCT). A vehicle can have A/T or DCT variant according to its option, for example 4-speed A/T or 5-speed A/T can be equipped in the same kind of vehicles and other control systems (e.g. ESC, TCS, ¡¦) can need this information to apply appropriate control logic.



The CVT (Continuously Variable Transmission) should set this signal to 00H.";
BA_ "UserSigValidity" SG_ 2164277249 TCU_GearStepTyp 3;
BA_ "RoutingFactor" SG_ 2164277249 TCU_GearStepTyp 5;
BA_ "Version" SG_ 2164277249 TCU_GearStepTyp "19.02.07";
BA_ "Description" SG_ 2164277249 TCU_GearShftSta "SWI_GS indicates whether a gear change is being executed in the gearbox.



Note : Gear change means a gear shift at D-range and Garage shift(PRND).";
BA_ "UserSigValidity" SG_ 2164277249 TCU_GearShftSta 3;
BA_ "RoutingFactor" SG_ 2164277249 TCU_GearShftSta 5;
BA_ "Version" SG_ 2164277249 TCU_GearShftSta "17.11.00";
BA_ "Description" SG_ 2164277249 TCU_TqCnvrtrSta "Status converter clutch



There is no specific phase relationship between the output and any other signal.";
BA_ "UserSigValidity" SG_ 2164277249 TCU_TqCnvrtrSta 3;
BA_ "RoutingFactor" SG_ 2164277249 TCU_TqCnvrtrSta 5;
BA_ "Version" SG_ 2164277249 TCU_TqCnvrtrSta "17.11.00";
BA_ "GenMsgSendType" BO_ 2164277250 0;
BA_ "GenMsgCycleTime" BO_ 2164277250 50;
BA_ "GenMsgCycleTimeFast" BO_ 2164277250 0;
BA_ "GenMsgNrOfRepetition" BO_ 2164277250 0;
BA_ "VFrameFormat" BO_ 2164277250 1;
BA_ "Description" SG_ 2164277250 TCU_CurrGearSta "CUR_GR indicates the gear speed which is currently engaged in the gearbox.";
BA_ "UserSigValidity" SG_ 2164277250 TCU_CurrGearSta 3;
BA_ "RoutingFactor" SG_ 2164277250 TCU_CurrGearSta 5;
BA_ "Version" SG_ 2164277250 TCU_CurrGearSta "17.11.00";
BA_ "Description" SG_ 2164277250 TCH_EngTrgtGearSta "TCH_EngTrgtGearSta informs about target gear of SS timing 

(For indicating Paddle shift or Manual mode on cluster)";
BA_ "UserSigValidity" SG_ 2164277250 TCH_EngTrgtGearSta 3;
BA_ "RoutingFactor" SG_ 2164277250 TCH_EngTrgtGearSta 5;
BA_ "Version" SG_ 2164277250 TCH_EngTrgtGearSta "17.11.00";
BA_ "Description" SG_ 2164277250 TCU_EngTqLimVal "The TCU requests a engine torque limit(ETL) from the EMS. 

There is no time limitation of the intervention.

TCU requests engine torque limit below the TCU requesting torque.

The engine torque request signal means the absolute torque limitation.

TCU sends it through CAN system and makes it change every moment.

In any non-requesting situations, TCU sends the maximum value of CAN message.



If MSB is 1, this signal is - value.

else, this signal is +value.

0~10bit is used for absolute value.";
BA_ "GenSigStartValue" SG_ 2164277250 TCU_EngTqLimVal 2047;
BA_ "UserSigValidity" SG_ 2164277250 TCU_EngTqLimVal 3;
BA_ "RoutingFactor" SG_ 2164277250 TCU_EngTqLimVal 5;
BA_ "Version" SG_ 2164277250 TCU_EngTqLimVal "20.03.05";
BA_ "Description" SG_ 2164277250 TCU_CluTrgtGearConfg "This signal indicates the signal source configuration of target gear for CLU";
BA_ "UserSigValidity" SG_ 2164277250 TCU_CluTrgtGearConfg 3;
BA_ "RoutingFactor" SG_ 2164277250 TCU_CluTrgtGearConfg 5;
BA_ "Version" SG_ 2164277250 TCU_CluTrgtGearConfg "18.08.01";
BA_ "Description" SG_ 2164277250 TCU_VehSpdKphVal "The vehicle speed calculated by TCU is transferred. 

If a vehicle has no vehicle speed sensor, no wheel speed sensor and no ABS(TCS/ESC) then it is impossible for an EMS to calculate veficle speed. In this case a TCU should calculate vehicle speed and send to other ECUs.

The calculation can be done with output speed of gearbox, final gear ratio and actual radius of a tire. 

In case of failure the value FFH is used as error identifier.";
BA_ "UserSigValidity" SG_ 2164277250 TCU_VehSpdKphVal 3;
BA_ "RoutingFactor" SG_ 2164277250 TCU_VehSpdKphVal 5;
BA_ "Version" SG_ 2164277250 TCU_VehSpdKphVal "17.11.00";
BA_ "Description" SG_ 2164277250 TCU_TrgtGearSta "CF_Tcu_TarGr informs about the speed, which is currently engaged in the gearbox, or, in case of a gear change (SWI_GS), which speed is reached.



Note: Gear changes covering more than one speed are also possible.

In the P and N positions, the frictional connection is interrupted hydraulically.

Depending on the type of error, the 3rd or 4th (forward) speed, and the R (reverse) speed are engaged in the limp home program.";
BA_ "UserSigValidity" SG_ 2164277250 TCU_TrgtGearSta 3;
BA_ "RoutingFactor" SG_ 2164277250 TCU_TrgtGearSta 5;
BA_ "Version" SG_ 2164277250 TCU_TrgtGearSta "17.11.00";
BA_ "Description" SG_ 2164277250 TCU_DcmlVehSpdKphVal "The signal VS_TCU_DECIAMAL means the value which is below decimal point of the vehicle speed.

For instance, if a vehicle speed is 13.75Km/h, VS_TCU means 13Km/h and VS_TCU_DECIMAL means 0.75Km/h.



Example)   VS_TCU = 13,  VS_TCU_DECIAMAL  = 96

Vehicle speed  = VS_TCU + ( VS_TCU_DECIMAL / 128 )

= 13 + ( 96 / 128 ) = 13.75 [Km/h]";
BA_ "UserSigValidity" SG_ 2164277250 TCU_DcmlVehSpdKphVal 3;
BA_ "RoutingFactor" SG_ 2164277250 TCU_DcmlVehSpdKphVal 5;
BA_ "Version" SG_ 2164277250 TCU_DcmlVehSpdKphVal "17.11.00";
BA_ "Description" SG_ 2164277250 TCU_SprkRtrdReq "The TCU requests a spark angle retard via the signal SPK_RTD_TCU to the EMS for torque reduction during the gear engage condition.



(PH) = ((HEX) - 3FH) * 0.375 (Advance) (PH) = (3FH - (HEX)) * (-0.375) (Retard)

-15¢ª  ... 0¢ª= 17H .. 3FH (Retard)

0.375¢ª. 15¢ª= 40H .. 67H (Advance)";
BA_ "GenSigStartValue" SG_ 2164277250 TCU_SprkRtrdReq 255;
BA_ "UserSigValidity" SG_ 2164277250 TCU_SprkRtrdReq 3;
BA_ "RoutingFactor" SG_ 2164277250 TCU_SprkRtrdReq 5;
BA_ "Version" SG_ 2164277250 TCU_SprkRtrdReq "17.11.00";
BA_ "Description" SG_ 2164277250 TCU_EngRpmDisSta "Flag for Engine RPM(from TCU) Display on Cluster, Only when this flag is set to 1, Cluster shall display the Engine RPM from TCU";
BA_ "UserSigValidity" SG_ 2164277250 TCU_EngRpmDisSta 3;
BA_ "RoutingFactor" SG_ 2164277250 TCU_EngRpmDisSta 5;
BA_ "Version" SG_ 2164277250 TCU_EngRpmDisSta "17.11.00";
BA_ "Description" SG_ 2164277250 TCU_GearLmpBlnkngReq "Cluster controls blinking of Gear lamp receiving the request signal from TCU.";
BA_ "UserSigValidity" SG_ 2164277250 TCU_GearLmpBlnkngReq 3;
BA_ "RoutingFactor" SG_ 2164277250 TCU_GearLmpBlnkngReq 5;
BA_ "Version" SG_ 2164277250 TCU_GearLmpBlnkngReq "17.11.00";
BA_ "Description" SG_ 2164277250 TCU_FuelCutInhbtReq "During coast down shifting, EMS may cut off fuel injection and as a result, a driver can feel bad shift feeling. In this case, to enhance shift quality, TCU needs inhibition of fuel cut off control.

This signal indicates inhibition of engine fuel cut off control.";
BA_ "UserSigValidity" SG_ 2164277250 TCU_FuelCutInhbtReq 3;
BA_ "RoutingFactor" SG_ 2164277250 TCU_FuelCutInhbtReq 5;
BA_ "Version" SG_ 2164277250 TCU_FuelCutInhbtReq "17.11.00";
BA_ "Description" SG_ 2164277250 TCU_IdleUpReq "When ATF(Automatic Transmission Fluid) rises in high temperauture, the TCU requests engine idle RPM up via the signal IDLE_UP_TCU to the EMS for reduction of gearshift time form Neutral to Reverse.



THIS SIGNAL IS FOR ¡°LAMBDA ENGINE¡± SYSTEM ONLY.";
BA_ "UserSigValidity" SG_ 2164277250 TCU_IdleUpReq 3;
BA_ "RoutingFactor" SG_ 2164277250 TCU_IdleUpReq 5;
BA_ "Version" SG_ 2164277250 TCU_IdleUpReq "17.11.00";
BA_ "Description" SG_ 2164277250 TCU_CluTrgtGearSta "TCH_CluTrgtGearSta informs about target gear of SS timing 

(For indicating Paddle shift or Manual mode on cluster)";
BA_ "UserSigValidity" SG_ 2164277250 TCU_CluTrgtGearSta 3;
BA_ "RoutingFactor" SG_ 2164277250 TCU_CluTrgtGearSta 5;
BA_ "Version" SG_ 2164277250 TCU_CluTrgtGearSta "17.11.00";
BA_ "GenMsgSendType" BO_ 2164277251 0;
BA_ "GenMsgCycleTime" BO_ 2164277251 50;
BA_ "GenMsgCycleTimeFast" BO_ 2164277251 0;
BA_ "GenMsgNrOfRepetition" BO_ 2164277251 0;
BA_ "VFrameFormat" BO_ 2164277251 1;
BA_ "Description" SG_ 2164277251 TCU_EngRpmDis "Engine RPM from TCU (Only for the display on Cluster)";
BA_ "UserSigValidity" SG_ 2164277251 TCU_EngRpmDis 3;
BA_ "RoutingFactor" SG_ 2164277251 TCU_EngRpmDis 5;
BA_ "Version" SG_ 2164277251 TCU_EngRpmDis "17.11.00";
BA_ "Description" SG_ 2164277251 TCU_SlpVal "This signal is used to avoid busy shifting during uphill driving.

It is calculated using engine torque, turbine torque and gearbox torque so on.

It has some restrictions like the following sentences

- No slope calculation during shifting, braking, 1st gear, or at low oil temperature (Under 10 degree).

- The slope calculation is inaccurate at low vehicle speed (under 30 KPH).

- Slope is calculated according to (CVW + 180Kg). It means that if the vehicle weight increases more than it, then the calculated slope value increases.

If calculated road gradient is less than -16%, SLOPE_TCU should be set to 00h, and if calculated road gradient is more than 15.5%, SLOPE_TCU should be set to 3Fh.";
BA_ "GenSigStartValue" SG_ 2164277251 TCU_SlpVal 32;
BA_ "UserSigValidity" SG_ 2164277251 TCU_SlpVal 3;
BA_ "RoutingFactor" SG_ 2164277251 TCU_SlpVal 5;
BA_ "Version" SG_ 2164277251 TCU_SlpVal "17.11.00";
BA_ "Description" SG_ 2164277251 TCU_EngSpdIncReq "This signal is a target engine speed requirement start flag signal by TCU, 

which is sent to ECU. It is synchronized to the signal engine speed increasing target speed value.";
BA_ "UserSigValidity" SG_ 2164277251 TCU_EngSpdIncReq 3;
BA_ "RoutingFactor" SG_ 2164277251 TCU_EngSpdIncReq 5;
BA_ "Version" SG_ 2164277251 TCU_EngSpdIncReq "17.11.00";
BA_ "Description" SG_ 2164277251 TCU_ObdSta "The signal TCU_OBD is used to inform the OBD master (EMS-ECU) in case a OBD relevant fault is detected. According to the OBD regulations the TCU could request MIL on. If a freeze frame request by the TCU has not been acknowledged (OBD_FRF_ACK) within 2 seconds, this request has to be canceled.

-> Related signal : See ¡°EngFrzFrm¡± message

Bit0 : Reserved

Bit1 : Failure information of TCU

Bit2 : MIL on request



The exact meaning of this signals and under which conditions they are used has to be defined by the TCU supplier (in accordance with the OBD II regulations).";
BA_ "UserSigValidity" SG_ 2164277251 TCU_ObdSta 3;
BA_ "RoutingFactor" SG_ 2164277251 TCU_ObdSta 5;
BA_ "Version" SG_ 2164277251 TCU_ObdSta "19.02.07";
BA_ "Description" SG_ 2164277251 TCU_SprtyIndxSta "Sporty index based on the driver's driving behaviour";
BA_ "UserSigValidity" SG_ 2164277251 TCU_SprtyIndxSta 3;
BA_ "RoutingFactor" SG_ 2164277251 TCU_SprtyIndxSta 5;
BA_ "Version" SG_ 2164277251 TCU_SprtyIndxSta "17.11.00";
BA_ "Description" SG_ 2164277251 TCU_DrvngModDis "Driving mode display by TCU";
BA_ "UserSigValidity" SG_ 2164277251 TCU_DrvngModDis 3;
BA_ "RoutingFactor" SG_ 2164277251 TCU_DrvngModDis 5;
BA_ "Version" SG_ 2164277251 TCU_DrvngModDis "17.11.00";
BA_ "Description" SG_ 2164277251 TCU_DrvngModReq "Driving mode request with Normal, Eco, Eco+, Sport, Sport+

and Snow only TCU automode is on, otherwise, inactive";
BA_ "UserSigValidity" SG_ 2164277251 TCU_DrvngModReq 3;
BA_ "RoutingFactor" SG_ 2164277251 TCU_DrvngModReq 5;
BA_ "Version" SG_ 2164277251 TCU_DrvngModReq "17.11.00";
BA_ "Description" SG_ 2164277251 TCU_SmrtShftSta "Information of SmartShift";
BA_ "UserSigValidity" SG_ 2164277251 TCU_SmrtShftSta 3;
BA_ "RoutingFactor" SG_ 2164277251 TCU_SmrtShftSta 5;
BA_ "Version" SG_ 2164277251 TCU_SmrtShftSta "17.11.00";
BA_ "Description" SG_ 2164277251 TCU_LupTrgtEngSpdVal "This signal is a target engine speed requested by TCU, which is sent to ECU. 

It is intended for OFF-SLIP to be more successful in triggering fuel cut-off under more various driving conditions.";
BA_ "GenSigStartValue" SG_ 2164277251 TCU_LupTrgtEngSpdVal 255;
BA_ "UserSigValidity" SG_ 2164277251 TCU_LupTrgtEngSpdVal 3;
BA_ "RoutingFactor" SG_ 2164277251 TCU_LupTrgtEngSpdVal 5;
BA_ "Version" SG_ 2164277251 TCU_LupTrgtEngSpdVal "17.11.00";
BA_ "Description" SG_ 2164277251 TCU_FrtStcShftSta "Status of fisrt static shift";
BA_ "UserSigValidity" SG_ 2164277251 TCU_FrtStcShftSta 3;
BA_ "RoutingFactor" SG_ 2164277251 TCU_FrtStcShftSta 5;
BA_ "Version" SG_ 2164277251 TCU_FrtStcShftSta "17.11.00";
BA_ "Description" SG_ 2164277251 TCU_IsgInhbtReq "TCU requests ECU to inhibit the ISG function when ISG start condition of AT is not met (oil temp is too low , AT ISG system malfunction, etc ¡¦ )";
BA_ "UserSigValidity" SG_ 2164277251 TCU_IsgInhbtReq 3;
BA_ "RoutingFactor" SG_ 2164277251 TCU_IsgInhbtReq 5;
BA_ "Version" SG_ 2164277251 TCU_IsgInhbtReq "17.11.00";
BA_ "Description" SG_ 2164277251 TCU_CdaInhbtReq "TCU requests ECU to prohibit the CDA transition during gear shifting or lock-up clutch operation in the automatic transmission in order to prevent a shock on the vehicle. Without gear shifting and lock-up clutch operation, CDA transition can be performed.";
BA_ "UserSigValidity" SG_ 2164277251 TCU_CdaInhbtReq 3;
BA_ "RoutingFactor" SG_ 2164277251 TCU_CdaInhbtReq 5;
BA_ "Version" SG_ 2164277251 TCU_CdaInhbtReq "17.11.00";
BA_ "Description" SG_ 2164277251 TCU_BrkOnReq "The TCU request the ESC to activate the Brake.

The ESC holds the Brake ON during the TCU¡¯s Brake ON Request.";
BA_ "UserSigValidity" SG_ 2164277251 TCU_BrkOnReq 3;
BA_ "RoutingFactor" SG_ 2164277251 TCU_BrkOnReq 5;
BA_ "Version" SG_ 2164277251 TCU_BrkOnReq "17.11.00";
BA_ "Description" SG_ 2164277251 TCU_TqGrdntLimVal "TCU requests EMS to perform the engine torque gradient limitation control with a rate of Nm per second(Nm/sec).



Downshift : The engine torque gradient limitation for downshift will be a function of pedal and shift-time. 

Upshift : The engine torque gradient limitation for upshift will be a function of shift-time.";
BA_ "UserSigValidity" SG_ 2164277251 TCU_TqGrdntLimVal 3;
BA_ "RoutingFactor" SG_ 2164277251 TCU_TqGrdntLimVal 5;
BA_ "Version" SG_ 2164277251 TCU_TqGrdntLimVal "17.11.00";
BA_ "GenMsgSendType" BO_ 2164277252 0;
BA_ "GenMsgCycleTime" BO_ 2164277252 50;
BA_ "GenMsgCycleTimeFast" BO_ 2164277252 0;
BA_ "GenMsgNrOfRepetition" BO_ 2164277252 0;
BA_ "VFrameFormat" BO_ 2164277252 1;
BA_ "Description" SG_ 2164277252 TCU_NetrlCtrlSta "This signal indicates the status of Neutral Control.";
BA_ "UserSigValidity" SG_ 2164277252 TCU_NetrlCtrlSta 3;
BA_ "RoutingFactor" SG_ 2164277252 TCU_NetrlCtrlSta 5;
BA_ "Version" SG_ 2164277252 TCU_NetrlCtrlSta "17.11.00";
BA_ "Description" SG_ 2164277252 TCU_ShftPtrnSta "It is an ID of current shift pattern which is being used by TCU.

The ID is assigned for each TCU.";
BA_ "UserSigValidity" SG_ 2164277252 TCU_ShftPtrnSta 3;
BA_ "RoutingFactor" SG_ 2164277252 TCU_ShftPtrnSta 5;
BA_ "Version" SG_ 2164277252 TCU_ShftPtrnSta "17.11.00";
BA_ "Description" SG_ 2164277252 TCU_EPBReq "This is EPB Request signal for prevent P-D Shift shock on the hill";
BA_ "UserSigValidity" SG_ 2164277252 TCU_EPBReq 3;
BA_ "RoutingFactor" SG_ 2164277252 TCU_EPBReq 5;
BA_ "Version" SG_ 2164277252 TCU_EPBReq "19.03.09";
BA_ "Description" SG_ 2164277252 IMT_EOLstate "If this signal is set, Cluster should display gear info using alphabet 'E' regardless the signal 'TCU_GearSlctDis'";
BA_ "UserSigValidity" SG_ 2164277252 IMT_EOLstate 3;
BA_ "RoutingFactor" SG_ 2164277252 IMT_EOLstate 5;
BA_ "Version" SG_ 2164277252 IMT_EOLstate "19.02.06";
BA_ "Description" SG_ 2164277252 IMT_DisCmd "This signal is used for cluster to change gear display type. 

Always Display / Not Display / Blinking";
BA_ "UserSigValidity" SG_ 2164277252 IMT_DisCmd 3;
BA_ "RoutingFactor" SG_ 2164277252 IMT_DisCmd 5;
BA_ "Version" SG_ 2164277252 IMT_DisCmd "19.02.06";
BA_ "Description" SG_ 2164277252 IMT_CltchPdlPos "Clutch Position Sensor value for 3 pedal IMT system.

This value is not supported by 2 pedal IMT system.



0% means pedal off 

99.21875% (0xFE) means pedal fully pressed

99.609375 (0xFF) means  error";
BA_ "UserSigValidity" SG_ 2164277252 IMT_CltchPdlPos 3;
BA_ "RoutingFactor" SG_ 2164277252 IMT_CltchPdlPos 5;
BA_ "Version" SG_ 2164277252 IMT_CltchPdlPos "19.02.06";
BA_ "Description" SG_ 2164277252 DCT_RegenInhbt "The regen inhibit request from TCU.

ECU is received regen inhibit flag from TCU, then ECU is limited the regen state.";
BA_ "UserSigValidity" SG_ 2164277252 DCT_RegenInhbt 3;
BA_ "RoutingFactor" SG_ 2164277252 DCT_RegenInhbt 5;
BA_ "Version" SG_ 2164277252 DCT_RegenInhbt "18.08.02";
BA_ "Description" SG_ 2164277252 DCT_EngIdleReq "Engine Idle Request from TCU";
BA_ "UserSigValidity" SG_ 2164277252 DCT_EngIdleReq 3;
BA_ "RoutingFactor" SG_ 2164277252 DCT_EngIdleReq 5;
BA_ "Version" SG_ 2164277252 DCT_EngIdleReq "18.08.02";
BA_ "Description" SG_ 2164277252 DCT_CltchState "Status of DCT clutches. This signal gives information about the frictional connection between the engine and the drive train.";
BA_ "UserSigValidity" SG_ 2164277252 DCT_CltchState 3;
BA_ "RoutingFactor" SG_ 2164277252 DCT_CltchState 5;
BA_ "Version" SG_ 2164277252 DCT_CltchState "18.08.02";
BA_ "Description" SG_ 2164277252 DCT_FuelCutReq "Fuel Cut request bit signal to let EMS perform ¡®Fuel Cut torque intervention¡¯ during shift";
BA_ "UserSigValidity" SG_ 2164277252 DCT_FuelCutReq 3;
BA_ "RoutingFactor" SG_ 2164277252 DCT_FuelCutReq 5;
BA_ "Version" SG_ 2164277252 DCT_FuelCutReq "18.08.02";
BA_ "Description" SG_ 2164277252 DCT_TqIncReq "An Identifier of a DCT TCU controller for increasing torque intervention. 

This bit is to prevent the triggering of unintended DCT TCU interventions.



In the case of a torque increase, following conditions must be fulfilled.

DCT_TqIncReq = 1 and TCU_EngTqIncReqVal > 00H.";
BA_ "UserSigValidity" SG_ 2164277252 DCT_TqIncReq 3;
BA_ "RoutingFactor" SG_ 2164277252 DCT_TqIncReq 5;
BA_ "Version" SG_ 2164277252 DCT_TqIncReq "18.08.02";
BA_ "Description" SG_ 2164277252 DCT_CrpTqReq "During creep mode (engine in idle, brake pedal not pressed, gear engaged) clutch torque will be applied. In order to support the engine¡¯s idle controller DCT_CrpTqReq gives the information how much clutch torque will be applied within the next 50 ms.";
BA_ "GenSigStartValue" SG_ 2164277252 DCT_CrpTqReq 512;
BA_ "UserSigValidity" SG_ 2164277252 DCT_CrpTqReq 3;
BA_ "RoutingFactor" SG_ 2164277252 DCT_CrpTqReq 5;
BA_ "Version" SG_ 2164277252 DCT_CrpTqReq "18.08.02";
BA_ "Description" SG_ 2164277252 DCT_ShftTqReq "To ensure a torque increasing during gear shift within short time, ECU needs to build up a torque reserve determined by the pre-control torque. 

Open throttle valve (more air) and automatic ignition angle reduction (within limited range based on engine characteristic) to ensure constant torque level.

The DCT TCU informs a pre-control torque via the signal DCT_ShftTqReq to the EMS.



If MSB is 1, this signal is - value. else, this signal is +value.

0~10bit is used for absolute value.";
BA_ "UserSigValidity" SG_ 2164277252 DCT_ShftTqReq 3;
BA_ "RoutingFactor" SG_ 2164277252 DCT_ShftTqReq 5;
BA_ "Version" SG_ 2164277252 DCT_ShftTqReq "20.03.05";
BA_ "Description" SG_ 2164277252 TCU_VgisInhbtReq "TCU requests ECU to inhibit the VGIS fuction from changing its status.";
BA_ "UserSigValidity" SG_ 2164277252 TCU_VgisInhbtReq 3;
BA_ "RoutingFactor" SG_ 2164277252 TCU_VgisInhbtReq 5;
BA_ "Version" SG_ 2164277252 TCU_VgisInhbtReq "17.11.00";
BA_ "Description" SG_ 2164277252 TCU_EngTqIncReqVal "The TCU requests the engine torque increase via this signal to the EMS.



If MSB is 1, this signal is - value.

else, this signal is +value.

0~10bit is used for absolute value.";
BA_ "UserSigValidity" SG_ 2164277252 TCU_EngTqIncReqVal 3;
BA_ "RoutingFactor" SG_ 2164277252 TCU_EngTqIncReqVal 5;
BA_ "Version" SG_ 2164277252 TCU_EngTqIncReqVal "20.03.05";
BA_ "GenMsgSendType" BO_ 2189467649 0;
BA_ "GenMsgCycleTime" BO_ 2189467649 50;
BA_ "GenMsgCycleTimeFast" BO_ 2189467649 0;
BA_ "GenMsgNrOfRepetition" BO_ 2189467649 0;
BA_ "VFrameFormat" BO_ 2189467649 1;
BA_ "Description" SG_ 2189467649 WHL_Crc1Val "The data area for CRC calculation is based on the data length (DLC) of the message DB.

The CRC shall be calculated over the entire data block (excluding the CRC bytes) including the user data, alive counter and Data ID

 

- CRC Polynomial (0x1021) , Initial Value : 0xFFFF, XOR value : 0x0000, Data ID : Message ID + 0xF800 

- The initial value is for CRC calculation and the message should be sent with the calculated result value. 

- The mathematical expression to 16 bit CRC polynomial is given here. G(x) = x16 + x12 + x5 + 1";
BA_ "GenSigStartValue" SG_ 2189467649 WHL_Crc1Val 65535;
BA_ "UserSigValidity" SG_ 2189467649 WHL_Crc1Val 3;
BA_ "RoutingFactor" SG_ 2189467649 WHL_Crc1Val 5;
BA_ "Version" SG_ 2189467649 WHL_Crc1Val "18.11.08";
BA_ "Description" SG_ 2189467649 WHL_AlvCnt1Val "For the first transmission request for a data element the counter shall be initialized with 0 and shall be incremented by 1 for every subsequent send request. 

When the counter reaches the maximum value(0xFF), then it shall restart with 0 for the next send request";
BA_ "UserSigValidity" SG_ 2189467649 WHL_AlvCnt1Val 3;
BA_ "RoutingFactor" SG_ 2189467649 WHL_AlvCnt1Val 5;
BA_ "Version" SG_ 2189467649 WHL_AlvCnt1Val "18.11.08";
BA_ "Description" SG_ 2189467649 WHL_PlsFLVal "This signal indicates accumulated pulse counter of ABS^ESC wheel speed sensor (FL^FR^RL^RR)

Receiver unit uses this signal for calculation of vehicle movement distance.

Requested resolution of this signal is 0.5 pulses and refer to below (wheel sensor signal).";
BA_ "UserSigValidity" SG_ 2189467649 WHL_PlsFLVal 3;
BA_ "RoutingFactor" SG_ 2189467649 WHL_PlsFLVal 5;
BA_ "Version" SG_ 2189467649 WHL_PlsFLVal "17.12.00";
BA_ "Description" SG_ 2189467649 WHL_PlsFRVal "This signal indicates accumulated pulse counter of ABS^ESC wheel speed sensor (FL^FR^RL^RR)

Receiver unit uses this signal for calculation of vehicle movement distance.

Requested resolution of this signal is 0.5 pulses and refer to below (wheel sensor signal).";
BA_ "UserSigValidity" SG_ 2189467649 WHL_PlsFRVal 3;
BA_ "RoutingFactor" SG_ 2189467649 WHL_PlsFRVal 5;
BA_ "Version" SG_ 2189467649 WHL_PlsFRVal "17.12.00";
BA_ "Description" SG_ 2189467649 WHL_PlsRLVal "This signal indicates accumulated pulse counter of ABS^ESC wheel speed sensor (FL^FR^RL^RR)

Receiver unit uses this signal for calculation of vehicle movement distance.

Requested resolution of this signal is 0.5 pulses and refer to below (wheel sensor signal).";
BA_ "UserSigValidity" SG_ 2189467649 WHL_PlsRLVal 3;
BA_ "RoutingFactor" SG_ 2189467649 WHL_PlsRLVal 5;
BA_ "Version" SG_ 2189467649 WHL_PlsRLVal "17.12.00";
BA_ "Description" SG_ 2189467649 WHL_PlsRRVal "This signal indicates accumulated pulse counter of ABS^ESC wheel speed sensor (FL^FR^RL^RR)

Receiver unit uses this signal for calculation of vehicle movement distance.

Requested resolution of this signal is 0.5 pulses and refer to below (wheel sensor signal).";
BA_ "UserSigValidity" SG_ 2189467649 WHL_PlsRRVal 3;
BA_ "RoutingFactor" SG_ 2189467649 WHL_PlsRRVal 5;
BA_ "Version" SG_ 2189467649 WHL_PlsRRVal "17.12.00";
BA_ "Description" SG_ 2189467649 WHL_DirFLVal "This signal is used to check the moving direction of WHL_PUL_FL signal.";
BA_ "UserSigValidity" SG_ 2189467649 WHL_DirFLVal 3;
BA_ "RoutingFactor" SG_ 2189467649 WHL_DirFLVal 5;
BA_ "Version" SG_ 2189467649 WHL_DirFLVal "17.12.00";
BA_ "Description" SG_ 2189467649 WHL_DirFRVal "This signal is used to check the moving direction of WHL_PUL_FR signal.";
BA_ "UserSigValidity" SG_ 2189467649 WHL_DirFRVal 3;
BA_ "RoutingFactor" SG_ 2189467649 WHL_DirFRVal 5;
BA_ "Version" SG_ 2189467649 WHL_DirFRVal "17.12.00";
BA_ "Description" SG_ 2189467649 WHL_DirRLVal "This signal is used to check the moving direction of WHL_PUL_RL signal.";
BA_ "UserSigValidity" SG_ 2189467649 WHL_DirRLVal 3;
BA_ "RoutingFactor" SG_ 2189467649 WHL_DirRLVal 5;
BA_ "Version" SG_ 2189467649 WHL_DirRLVal "17.12.00";
BA_ "Description" SG_ 2189467649 WHL_DirRRVal "This signal is used to check the moving direction of WHL_PUL_RR signal.";
BA_ "UserSigValidity" SG_ 2189467649 WHL_DirRRVal 3;
BA_ "RoutingFactor" SG_ 2189467649 WHL_DirRRVal 5;
BA_ "Version" SG_ 2189467649 WHL_DirRRVal "17.12.00";
BA_ "GenMsgSendType" BO_ 2189467650 0;
BA_ "GenMsgCycleTime" BO_ 2189467650 50;
BA_ "GenMsgCycleTimeFast" BO_ 2189467650 0;
BA_ "GenMsgNrOfRepetition" BO_ 2189467650 0;
BA_ "VFrameFormat" BO_ 2189467650 1;
BA_ "Description" SG_ 2189467650 WHL_SpdFLVal "This signal provides the wheel velocity of each wheel and have 14 bits length and a resolution of 0.03125 km^h.(This resolution is higher than that of signal in TCS5).

In case of failure of one wheel speed sensor, the value 3FFFH is used as error identifier.";
BA_ "UserSigValidity" SG_ 2189467650 WHL_SpdFLVal 3;
BA_ "RoutingFactor" SG_ 2189467650 WHL_SpdFLVal 5;
BA_ "Version" SG_ 2189467650 WHL_SpdFLVal "17.12.00";
BA_ "Description" SG_ 2189467650 WHL_SpdFRVal "This signal provides the wheel velocity of each wheel and have 14 bits length and a resolution of 0.03125 km^h.(This resolution is higher than that of signal in TCS5).

In case of failure of one wheel speed sensor, the value 3FFFH is used as error identifier.";
BA_ "UserSigValidity" SG_ 2189467650 WHL_SpdFRVal 3;
BA_ "RoutingFactor" SG_ 2189467650 WHL_SpdFRVal 5;
BA_ "Version" SG_ 2189467650 WHL_SpdFRVal "17.12.00";
BA_ "Description" SG_ 2189467650 WHL_SpdRLVal "This signal provides the wheel velocity of each wheel and have 14 bits length and a resolution of 0.03125 km^h.(This resolution is higher than that of signal in TCS5).

In case of failure of one wheel speed sensor, the value 3FFFH is used as error identifier.";
BA_ "UserSigValidity" SG_ 2189467650 WHL_SpdRLVal 3;
BA_ "RoutingFactor" SG_ 2189467650 WHL_SpdRLVal 5;
BA_ "Version" SG_ 2189467650 WHL_SpdRLVal "17.12.00";
BA_ "Description" SG_ 2189467650 WHL_SpdRRVal "This signal provides the wheel velocity of each wheel and have 14 bits length and a resolution of 0.03125 km^h.(This resolution is higher than that of signal in TCS5).

In case of failure of one wheel speed sensor, the value 3FFFH is used as error identifier.";
BA_ "UserSigValidity" SG_ 2189467650 WHL_SpdRRVal 3;
BA_ "RoutingFactor" SG_ 2189467650 WHL_SpdRRVal 5;
BA_ "Version" SG_ 2189467650 WHL_SpdRRVal "17.12.00";
BA_ "GenMsgSendType" BO_ 2189467651 0;
BA_ "GenMsgCycleTime" BO_ 2189467651 50;
BA_ "GenMsgCycleTimeFast" BO_ 2189467651 0;
BA_ "GenMsgNrOfRepetition" BO_ 2189467651 0;
BA_ "VFrameFormat" BO_ 2189467651 1;
BA_ "Description" SG_ 2189467651 WHL_SpdCalParmtr "ÀÌ ½ÅÈ£´Â ABS/ESC ³»ºÎ¿¡¼­ ÈÙ ÆÞ½º °ªÀ» ÈÙ ½ºÇÇµå·Î º¯È¯ÇÏ´Âµ¥ »ç¿ëÇÏ´Â ESC ³»ºÎ ÆÄ¶ó¹ÌÅÍ¸¦ ÀÇ¹ÌÇÔ.

º» ½ÅÈ£´Â ½ÇÁ¦ Å¸ÀÌ¾î µ¿¹Ý°æ°ú ´Ù¸¦ ¼ö ÀÖÀ¸¸ç, ABS/ESCÀÇ Á¦¾î¸¦ À§ÇÑ Â÷¼Ó ÃßÁ¤À» À§ÇØ °³¹ß °úÁ¤ Áß¿¡ ÀÓÀÇ·Î º¯°æÀÌ °¡´ÉÇÑ Calibration Value ÀÓ.

½ÅÈ£ »ç¿ëÀ» À§ÇØ¼­´Â »çÀü¿¡ ÇùÀÇ ÈÄ »ç¿ëÇØ¾ßÇÔ.";
BA_ "UserSigValidity" SG_ 2189467651 WHL_SpdCalParmtr 3;
BA_ "RoutingFactor" SG_ 2189467651 WHL_SpdCalParmtr 5;
BA_ "Version" SG_ 2189467651 WHL_SpdCalParmtr "19.05.02";
VAL_ 287 APSS_LumbarUpSw 0 "Default" 1 "Off" 2 "On" 3 "Invalid" ;
VAL_ 287 APSS_LumbarMidSw 0 "Default" 1 "Off" 2 "On" 3 "Invalid" ;
VAL_ 287 APSS_LumbarLowSw 0 "Default" 1 "Off" 2 "On" 3 "Invalid" ;
VAL_ 287 APSS_LumbarDefSw 0 "Default" 1 "Off" 2 "On" 3 "Invalid" ;
VAL_ 287 APSS_BolsterInfSw 0 "Default" 1 "Off" 2 "On" 3 "Invalid" ;
VAL_ 287 APSS_BolsterDefSw 0 "Default" 1 "Off" 2 "On" 3 "Invalid" ;
VAL_ 287 APSS_ActiveSw 0 "Off" 1 "On" 2 "Not Used" 3 "Error" ;
VAL_ 287 APSS_CushInfSw 0 "Off" 1 "On" 2 "Not Used" 3 "Error" ;
VAL_ 287 APSS_CushDefSw 0 "Off" 1 "On" 2 "Not Used" 3 "Error" ;
VAL_ 287 APSS_CushOnOffTch 0 "Default" 1 "Off" 2 "On(Off State)" 3 "On(Mode1 State)" 4 "On(Mode2 State)" 5 "On(Mode3 State)" 6 "Reserved" 7 "Invalid" ;
VAL_ 271 ASAU_AirSptTimeRValueSet 0 "Default" 1 "Short" 2 "Normal" 3 "Long" 4 "Reserved" 5 "Reserved" 6 "Reserved" 7 "Reserved" ;
VAL_ 271 ASAU_AstSmtAirSptRValueSet 0 "Default" 1 "Off" 2 "On" 3 "Invalid" ;
VAL_ 271 ASAU_CushSoftRValueSet 0 "Default" 1 "Off" 2 "Soft" 3 "Mid" 4 "Hard" 5 "Reserved" 6 "Reserved" 7 "Reserved" ;
VAL_ 271 ASAU_BackSoftRValueSet 0 "Default" 1 "Off" 2 "Soft" 3 "Mid" 4 "Hard" 5 "Reserved" 6 "Reserved" 7 "Reserved" ;
VAL_ 271 ASAU_AirSptModeRValueSet 0 "Default" 1 "Mode 1" 2 "Mode 2" 3 "Mode 3" 4 "Mode 4" 5 "Mode 5" 6 "Reserved" 7 "Reserved" ;
VAL_ 271 ASAU_NotFootMsgOperStaWarnPE 0 "Default" 1 "Off (Disable)" 2 "On (Enable)" 3 "Invalid" ;
VAL_ 271 ASAU_RRFootAirSptRValueSet 0 "Default" 1 "Off" 2 "On" 3 "Invalid" ;
VAL_ 271 ASAU_RRFootAirSptHeatRValueSet 0 "Default" 1 "Off" 2 "On" 3 "Invalid" ;
VAL_ 271 ASAU_MoodTrpyRValueSet 0 "Default" 1 "Off" 2 "On" 3 "Invalid" ;
VAL_ 271 ASAU_MoodTrpyCareSta 0 "Default" 1 "Off" 2 "On" 3 "Invalid" ;
VAL_ 271 ASAU_MoodTrpyComfSta 0 "Default" 1 "Off" 2 "On" 3 "Invalid" ;
VAL_ 271 ASAU_AirSptStrRValueSet 0 "Default" 1 "Low" 2 "Mid" 3 "High" 4 "Off" 5 "Reserved" 6 "Reserved" 7 "Reserved" ;
VAL_ 733 USM_TurnDstLnDispSta 0 "Default" 1 "Off" 2 "On" 3 "Invalid" ;
VAL_ 733 USM_TurnDstLnDispStaRH 0 "Default" 1 "Off" 2 "On" 3 "Invalid" ;
VAL_ 733 USM_RhstaLvlEnaSta 0 "Default" 1 "Off" 2 "On" 3 "Invalid" ;
VAL_ 733 USM_RhstaLvlEnaStaRH 0 "Default" 1 "Off" 2 "On" 3 "Invalid" ;
VAL_ 733 USM_CMSDayBrgtnsLvlLHSta 0 "-5 Level" 1 "-4 Level" 2 "-3 Level" 3 "-2 Level" 4 "-1 Level" 5 "0 Level" 6 "1 Level" 7 "2 Level" 8 "3 Level" 9 "4 Level" 10 "5 Level" 11 "Not Used" 12 "Not Used" 13 "Not Used" 14 "Error Indicator" 15 "Invalid" ;
VAL_ 733 USM_CMSNgtBrgtnsLvlLHSta 0 "-5 Level" 1 "-4 Level" 2 "-3 Level" 3 "-2 Level" 4 "-1 Level" 5 "0 Level" 6 "1 Level" 7 "2 Level" 8 "3 Level" 9 "4 Level" 10 "5 Level" 11 "Not Used" 12 "Not Used" 13 "Not Used" 14 "Error Indicator" 15 "Invalid" ;
VAL_ 733 IMS_CMSPlayBackSta_LH 0 "Stop" 1 "Play 1" 2 "Play 2" 3 "Smart IMS" 4 "Profile 1" 5 "Profile 2" 6 "Guest" 7 "Invalid" ;
VAL_ 733 CMSFldReq 0 "Default" 1 "Folding Request" 2 "Unfolding Request" 3 "Invalid" ;
VAL_ 733 CMS_LH_FoldingSta 0 "Off" 1 "Folding" 2 "Not Used" 3 "Error Indicator" ;
VAL_ 733 CMS_LH_UnfoldingSta 0 "Off" 1 "Unfolding" 2 "Not Used" 3 "Error Indicator" ;
VAL_ 733 CMS_LHVerPosVal 251 "Reserved" 252 "Reserved" 253 "Reserved" 254 "Reserved" 255 "Error Indicator" ;
VAL_ 733 CMS_LHHorPosVal 251 "Reserved" 252 "Reserved" 253 "Reserved" 254 "Reserved" 255 "Error Indicator" ;
VAL_ 733 Monitor_ViewPanningCmd 0 "No Movement" 1 "Move Up" 2 "Move Down" 3 "Move Left" 4 "Move Right" ;
VAL_ 2395189761 DATC_Typ 255 "Error Indicator" ;
VAL_ 2395189761 DATC_Opt1Typ 255 "Error Indicator" ;
VAL_ 2395189761 DATC_Opt3Typ 255 "Error Indicator" ;
VAL_ 2395189761 DATC_Opt2Typ 15 "Error Indicator" ;
VAL_ 2395189761 DATC_TxtPopupReq 0 "Off" 1 "TEXT POP-UP Request On" 2 "reserverd" 3 "Error Indicator" ;
VAL_ 2395189761 DATC_StrWhlUSMSta 0 "NOT APPLY" 1 "OFF" 2 "ON" 3 "Error Indicator" ;
VAL_ 2395189761 DATC_StrWhlHtngReq 0 "Default" 1 "Integrated control OFF" 2 "Steering Wheel heat OFF" 3 "Steering Wheel heat 1st ON" 4 "Steering Wheel heat 1st & 2nd ON" 5 "Reserved" 6 "Reserved" 7 "Invalid" ;
VAL_ 2193667329 EMS_Crc1Val 65535 "Signal Invalid (Message with unused CRC. CRC signal is transmitted fixed value)" ;
VAL_ 2193667329 EMS_AlvCnt1Val 255 "Signal Invalid (Message with unused Alive counter. Alive counter signal is transmitted fixed value)" ;
VAL_ 2193667330 ENG_EngSpdErrSta 0 "No error" 1 "Engine speed sensor defective" 2 "Not used" 3 "Error indicator" ;
VAL_ 2193667330 ENG_MafErrSta 0 "No error" 1 "Error on Torque Measurement" 2 "Not used" 3 "Error indicator" ;
VAL_ 2193667330 ENG_EtcLmphModSta 0 "Engine control is available" 1 "ETC Limphome mode by ECU" 2 "Not used" 3 "Error indicator" ;
VAL_ 2193667330 ENG_SpltInjctnSta 0 "Split injection OFF" 1 "Split injection ON" 2 "Not used" 3 "Error indicator" ;
VAL_ 2193667330 ENG_MaxAirconTqVal 255 "Error indicator" ;
VAL_ 2193667330 ENG_AirconPrsrSnsrVal 255 "Error indicator" ;
VAL_ 2193667330 ENG_IsgSta 0 "ISG is not operating Normal engine operating without ISG" 1 "Idle stop is activated Idle is stopped by ECU during driving" 2 "Automatically started by ECU Engine is automatically started by ECU regardless driver¡¯s volition during idle stop because the condition that ISG function to be prohibited is satisfied, for example SOC is too low." 3 "ISG is prohibited Driver prohibits to activate ISG in order to avoid start lag when he met traffic jam for example." 4 "Fault  existing in ISG. Idle stop is prohibited and engine started automatically if it is idle stop condition." 5 "Idle stop is inhibited by system automatically for safety and  convenient condition related with battery SOC, brake vacuum pressure etc. ISG function check for EOL." 6 "Auto start is deactivated system automatically to keep safety, Such as door open, hood open and seat belt unlock." 7 "If driver shift gear N to D range without braking to make auto starting. (Economy ISG Only)" ;
VAL_ 2193667330 ENG_OilLvlSta 0 "OIL LEVEL LAMP Off" 1 "OIL LEVEL LAMP On" 2 "Not used" 3 "Error indicator" ;
VAL_ 2193667331 ENG_TrgtIdleRpmVal 255 "Error indicator" ;
VAL_ 2193667331 ENG_GearShftDnDis 0 "Gear Shiftdown Display Off" 1 "Gear Shiftdown Display On" 2 "Not used" 3 "Error indicator" ;
VAL_ 2193667331 ENG_DsrGearPosDis 0 "No display" 1 "Gear Position 1 display" 2 "Gear Position 2 display" 3 "Gear Position 3 display" 4 "Gear Position 4 display" 5 "Gear Position 5 display" 6 "Gear Position 6 display" 7 "Gear Position 7 display" 8 "Gear Position 8 display" 9 "Gear Position 9 display" 10 "Gear Position 10 display" 15 "Error indicator" ;
VAL_ 2193667331 ENG_SldFuncSta 0 "Speed limiter function is not active" 1 "Speed limiter function is active" 2 "Not used" 3 "Error indicator" ;
VAL_ 2193667331 ENG_SldActnSta 0 "Positive action is not active" 1 "Positive action is active" 2 "Not used" 3 "Error indicator" ;
VAL_ 2193667331 ENG_FuelTnkPrsrSta 0 "Fuel Tank is not in high Pressure" 1 "Fuel Tank is in high Pressure" 2 "Not used" 3 "Error indicator" ;
VAL_ 2193667331 ENG_IsgBzrReq 0 "Request buzzer OFF" 1 "Request buzzer ON" 2 "Not used" 3 "Error indicator" ;
VAL_ 2193667331 ENG_IsgFuelCnsmptDis 0 "Not fuel consumption" 1 "Fuel consumption(=1mL)" 2 "Not used" 3 "Error indicator" ;
VAL_ 2193667331 ENG_FuelCapOpnSta 0 "Fuel cap isn't opened" 1 "Fuel cap is opened" 2 "Not used" 3 "Error indicator" ;
VAL_ 2193667331 ENG_EcoDrvActvSta 0 "Active Eco Drive is not active" 1 "Active Eco Drive is active" 2 "Not used" 3 "Error indicator" ;
VAL_ 2193667331 ENG_EngRunSta 0 "Engine Stop or Starting Phase" 1 "Engine Running" 2 "Not used" 3 "Error indicator" ;
VAL_ 2193667331 ENG_Isg2Sta 0 "Default" 1 "The condition for not-activated battery sensor. (Except EOL condition.)" 2 "In Auto Start status, when rapidly accelerating before complete gear shift. (Economy ISG Only)" 3 "Error indicator" ;
VAL_ 2193667331 ENG_IgnOnSta 0 "KEY OFF, control unit in self-holding phase" 1 "KEY ON" 2 "Not used" 3 "Error indicator" ;
VAL_ 2193667331 ENG_Ack4TcsSta 0 "TCS message not received within the last 500 ms, or a plausibility error in torque intervention is ON" 1 "TCS message received, and no plausibility error" 2 "Not used" 3 "Error indicator" ;
VAL_ 2193667331 ENG_FuelCutOffSta 0 "Engine not in fuel cut off" 1 "Engine in fuel cut off" 2 "Not used" 3 "Error indicator" ;
VAL_ 2193667331 ENG_CrctTqSta 0 "The desired intervention regarding ignition angle retardation and cylinder shut-off is executed. (Default value)" 1 "The desired intervention regarding ignition angle retardation and cylinder shut-off is executed; however, the requested target torque can not be adjusted precisely (torque steps)" 2 "The torque reduction regarding the ignition angle retardation cannot be completely executed. A cylinder shut-off is not possible at this time." 3 "Due to a failure detected the desired torque intervention for TCS regarding the ignition angle and cylinder shut-off is no longer executed." ;
VAL_ 2193667331 ENG_AirCompRlySta 0 "Air conditioner compressor relay OFF" 1 "Air conditioner compressor relay ON" 2 "Not used" 3 "Error indicator" ;
VAL_ 2193667331 ENG_LnchCntrlSta 0 "Off state" 1 "Standby" 2 "Ready" 3 "Lanch" 4 "Error indicator" ;
VAL_ 2193667331 ENG_GearShftUpDis 0 "Gear Shiftup Display Off" 1 "Gear Shiftup Display On" 2 "Not used" 3 "Error indicator" ;
VAL_ 2193667332 ENG_VehSpdHiVal 511 "Error indicator" ;
VAL_ 2193667332 ENG_EngInhbNCC 0 "NCC Inhibition OFF" 1 "NCC Inhibition ON" 2 "Not used" 3 "Error indicator" ;
VAL_ 2193667332 ENG_SldSwSta 0 "Speed limiter function is OFF" 1 "Speed limiter function is Active(Kickdown)" 2 "Speed limiter function is Pause" 3 "Error indicator" ;
VAL_ 2193667332 ENG_SldDrvAlertDisp 0 "Default" 1 "SldDisengaged" 2 "NoSldEngaged" 3 "ErrorIndicator" ;
VAL_ 2193667332 ENG_VehSpdLimVal 511 "Error indicator" ;
VAL_ 2214659329 EMS_Crc7Val 65535 "Signal Invalid (Message with unused CRC. CRC signal is transmitted fixed value)" ;
VAL_ 2214659329 EMS_AlvCnt7Val 255 "Signal Invalid (Message with unused Alive counter. Alive counter signal is transmitted fixed value)" ;
VAL_ 2214659330 HEV_EngOpSta 0 "ES(Engine Stop)" 1 "ST(Start)" 2 "IS(Idle speed)" 3 "PL(Part Load)" 4 "PU(Pull)" 5 "PUC(Fuel Cut off)" ;
VAL_ 2214659330 HEV_AccelPdlVal 0 "Accelerator Pedal not activated" 1022 "Accelerator Pedal fully activated" 1023 "Accelerator Pedal is defective (fail state) or Non-ETC system (APS is not installed)" ;
VAL_ 2307024129 EMS_Crc8Val 65535 "Signal Invalid (Message with unused CRC. CRC signal is transmitted fixed value)" ;
VAL_ 2307024129 EMS_AlvCnt8Val 255 "Signal Invalid (Message with unused Alive counter. Alive counter signal is transmitted fixed value)" ;
VAL_ 2307024129 HEV_VbOffActSta 0 "VB Off not Act" 1 "VB Off Act" 2 "Not used" 3 "Error indicator" ;
VAL_ 2307024129 HEV_AirCompOffReq 0 "none" 1 "off request" 2 "Not used" 3 "Error indicator" ;
VAL_ 2307024129 HEV_MilConfgVal 0 "No MIL" 1 "MIL/FMY treatment OBD1" 2 "MIL/FMY treatment OBD2" 3 "MIL/FMY treatment OBD2 (US)" 4 "MIL/FMY treatment EOBD" 5 "MIL/FMY treatment KOBD" ;
VAL_ 2307024129 HEV_CF_EMS_LOCKUP 0 "Request Off" 1 "Request On" ;
VAL_ 2307024129 HEV_OilLvlSta 0 "OIL LEVEL LAMP Off" 1 "OIL LEVEL LAMP On" 2 "Not used" 3 "Error indicator" ;
VAL_ 2307024129 HEV_ImmoLmpReq 0 "Off" 1 "Blink" 2 "On" 3 "Error indicator" ;
VAL_ 2307024129 HEV_MilReq 0 "Off" 1 "On" 2 "Not used" 3 "Error indicator" ;
VAL_ 2307024129 HEV_WiperSwSta 0 "Off" 1 "On" 2 "Not used" 3 "Error indicator" ;
VAL_ 2307024129 HEV_FanOpSta 0 "Off" 1 "On" 2 "Not used" 3 "Error indicator" ;
VAL_ 2307024129 HEV_FanSta 0 "Off" 1 "Low" 2 "Middle" 3 "High" ;
VAL_ 2307024129 HEV_BrkLtSwSta 0 "Not Support" 1 "Off" 2 "On" 3 "failure" ;
VAL_ 2307024130 HEV_SoakTimeErrSta 0 "No failure detected" 1 "Failure detected" 2 "Not used" 3 "Error indicator" ;
VAL_ 2307024130 HEV_SoakTimeOvrSta 0 "Engine soaking time < 360 min" 1 "Engine soaking time ¡Ã 360 min" 2 "Not used" 3 "Error indicator" ;
VAL_ 2307024130 HEV_FuelRunOutSta 0 "None" 1 "Fuel RunOut" 2 "Not used" 3 "Error indicator" ;
VAL_ 2307024130 HEV_FuelRunOutDetSta 0 "Inactive" 1 "Active" 2 "Not used" 3 "Error indicator" ;
VAL_ 2307024131 HEV_WarmUpReq_For_DATC 0 "Engine stop request" 1 "No engine stop request" ;
VAL_ 2307024131 HEV_RbmInhbtSta 0 "Enable of standardized vehicle operation and all numerators_denominators for RBM" 1 "Inhibition of standardized vehicle operation and all numerators_denominators for RBM" 2 "Not used" 3 "Error indicator" ;
VAL_ 2307024131 HEV_EhrsTempSta 0 "Normal" 1 "High" 3 "Fault" ;
VAL_ 2307024131 HEV_Aaf_WrnLamp 0 "Lamp OFF" 1 "Lamp ON" ;
VAL_ 2307024131 HEV_OPSFail 0 "Oil Pressure Warning Lamp OFF" 1 "Oil Pressure Warning Lamp ON" ;
VAL_ 2307024131 HEV_EngDsplceTyp 255 "Error indicator" ;
VAL_ 2307024131 HEV_EngTyp2 0 "LPI" 1 "MPI" 2 "GDI" 3 "TGDI" 4 "CVVL" 5 "CVVD" 6 "PDI" 7 "FFV" 8 "TCI" 9 "VGT" 10 "Turbo" 14 "Not used" 15 "Error indicator" ;
VAL_ 2307024131 HEV_EngTyp1 0 "epsilon(¥å)" 1 "gamma(¥ã)" 2 "kappa(¥ê)" 3 "theta(¥è)" 4 "nu(¥í)" 5 "lambda(¥ë)" 6 "tau(¥ó)" 10 "S" 11 "A" 12 "R" 13 "U" 14 "D" 15 "Error indicator" ;
VAL_ 2307024131 HEV_S_F 0 "AMS" 1 "ISG" 2 "Reserved" 3 "Reserved" ;
VAL_ 2307024131 HEV_S_F_GEN 0 "No AMS" 1 "1G Generation AMS" 2 "1.5G Generation AMS" 3 "2G Generation AMS" 4 "Reserved" 5 "Reserved" 6 "Reserved" 7 "Reserved" ;
VAL_ 2307024132 HEV_OilLifeRatio 1 "Engine oil life ratio with % unit" 2 "Engine oil life ratio with % unit" 3 "Engine oil life ratio with % unit" 4 "Engine oil life ratio with % unit" 5 "Engine oil life ratio with % unit" 6 "Engine oil life ratio with % unit" 7 "Engine oil life ratio with % unit" 8 "Engine oil life ratio with % unit" 9 "Engine oil life ratio with % unit" 10 "Engine oil life ratio with % unit" 11 "Engine oil life ratio with % unit" 12 "Engine oil life ratio with % unit" 13 "Engine oil life ratio with % unit" 14 "Engine oil life ratio with % unit" 15 "Engine oil life ratio with % unit" 16 "Engine oil life ratio with % unit" 17 "Engine oil life ratio with % unit" 18 "Engine oil life ratio with % unit" 19 "Engine oil life ratio with % unit" 20 "Engine oil life ratio with % unit" 21 "Engine oil life ratio with % unit" 22 "Engine oil life ratio with % unit" 23 "Engine oil life ratio with % unit" 24 "Engine oil life ratio with % unit" 25 "Engine oil life ratio with % unit" 26 "Engine oil life ratio with % unit" 27 "Engine oil life ratio with % unit" 28 "Engine oil life ratio with % unit" 29 "Engine oil life ratio with % unit" 30 "Engine oil life ratio with % unit" 31 "Engine oil life ratio with % unit" 32 "Engine oil life ratio with % unit" 33 "Engine oil life ratio with % unit" 34 "Engine oil life ratio with % unit" 35 "Engine oil life ratio with % unit" 36 "Engine oil life ratio with % unit" 37 "Engine oil life ratio with % unit" 38 "Engine oil life ratio with % unit" 39 "Engine oil life ratio with % unit" 40 "Engine oil life ratio with % unit" 41 "Engine oil life ratio with % unit" 42 "Engine oil life ratio with % unit" 43 "Engine oil life ratio with % unit" 44 "Engine oil life ratio with % unit" 45 "Engine oil life ratio with % unit" 46 "Engine oil life ratio with % unit" 47 "Engine oil life ratio with % unit" 48 "Engine oil life ratio with % unit" 49 "Engine oil life ratio with % unit" 50 "Engine oil life ratio with % unit" 51 "Engine oil life ratio with % unit" 52 "Engine oil life ratio with % unit" 53 "Engine oil life ratio with % unit" 54 "Engine oil life ratio with % unit" 55 "Engine oil life ratio with % unit" 56 "Engine oil life ratio with % unit" 57 "Engine oil life ratio with % unit" 58 "Engine oil life ratio with % unit" 59 "Engine oil life ratio with % unit" 60 "Engine oil life ratio with % unit" 61 "Engine oil life ratio with % unit" 62 "Engine oil life ratio with % unit" 63 "Engine oil life ratio with % unit" 64 "Engine oil life ratio with % unit" 65 "Engine oil life ratio with % unit" 66 "Engine oil life ratio with % unit" 67 "Engine oil life ratio with % unit" 68 "Engine oil life ratio with % unit" 69 "Engine oil life ratio with % unit" 70 "Engine oil life ratio with % unit" 71 "Engine oil life ratio with % unit" 72 "Engine oil life ratio with % unit" 73 "Engine oil life ratio with % unit" 74 "Engine oil life ratio with % unit" 75 "Engine oil life ratio with % unit" 76 "Engine oil life ratio with % unit" 77 "Engine oil life ratio with % unit" 78 "Engine oil life ratio with % unit" 79 "Engine oil life ratio with % unit" 80 "Engine oil life ratio with % unit" 81 "Engine oil life ratio with % unit" 82 "Engine oil life ratio with % unit" 83 "Engine oil life ratio with % unit" 84 "Engine oil life ratio with % unit" 85 "Engine oil life ratio with % unit" 86 "Engine oil life ratio with % unit" 87 "Engine oil life ratio with % unit" 88 "Engine oil life ratio with % unit" 89 "Engine oil life ratio with % unit" 90 "Engine oil life ratio with % unit" 91 "Engine oil life ratio with % unit" 92 "Engine oil life ratio with % unit" 93 "Engine oil life ratio with % unit" 94 "Engine oil life ratio with % unit" 95 "Engine oil life ratio with % unit" 96 "Engine oil life ratio with % unit" 97 "Engine oil life ratio with % unit" 98 "Engine oil life ratio with % unit" 99 "Engine oil life ratio with % unit" 100 "Engine oil life ratio with % unit" 101 "Not used" 102 "Not used" 103 "Not used" 104 "Not used" 105 "Not used" 106 "Not used" 107 "Not used" 108 "Not used" 109 "Not used" 110 "Not used" 111 "Not used" 112 "Not used" 113 "Not used" 114 "Not used" 115 "Not used" 116 "Not used" 117 "Not used" 118 "Not used" 119 "Not used" 120 "Not used" 121 "Not used" 122 "Not used" 123 "Not used" 124 "Not used" 125 "Not used" 126 "Not used" 127 "Error" ;
VAL_ 2307024132 HEV_OilLifeEna 0 "Oil life monitoring Not applied" 1 "Oil life monitoring Applied" 2 "Reserved" 3 "Error" ;
VAL_ 2307024132 HEV_OilLifeWarn 0 "No display" 1 "'Change engine oil' warning, 1st step (Low urgency)" 2 "'Change engine oil' warning, 2nd step (High urgency)" 3 "Oil change question based on oil temperature" 4 "Oil change confirm based on oil temperature" 5 "Reserved" 6 "Reserved" 7 "Error" ;
VAL_ 2307024132 HEV_RECTrigSta 0 "No detected" 1 "REC detected" ;
VAL_ 2307024132 HEV_PendingTrigSta 0 "No detected" 1 "Pending detected" ;
VAL_ 2244048129 ESC_VehAccelVal 2047 "Error" ;
VAL_ 2244048129 ESC_AccelBasisVal 2047 "Error" ;
VAL_ 2244048129 PWI_STATE 0 "nomarl" 1 "pad wear" 2 "reserved" 3 "invaild or Error" ;
VAL_ 2244048130 SCC_OptTyp 0 "SCC is not equipped" 1 "SCC is equipped" 2 "Not used" 3 "Not Coded" ;
VAL_ 2244048130 ESC_BrkLtReq 0 "No request" 1 "Activate brake lights" 2 "Not used" 3 "Error Indicator" ;
VAL_ 2244048130 ESC_DclEnblReq 0 "Disable deceleration control" 1 "Enable deceleration control" 2 "Not used" 3 "Error Indicator" ;
VAL_ 2244048130 ESC_DrvOvrdSta 0 "No override" 1 "Override by acceleration pedal" 2 "Override by deceleration" 3 "Error Indicator" ;
VAL_ 2244048130 ESC_DrvBrkSta 0 "Driver is not braking / failure" 1 "Driver is braking" 2 "Not used" 3 "Error Indicator" ;
VAL_ 2244048130 SCC_EnblReq 0 "SCC enabled" 1 "SCC disabled reversible" 2 "SCC disabled irreversible" 3 "SCC disabled irreversible due to communication error" ;
VAL_ 2244048130 ESC_DrvBrkActvSta 0 "Brake pedal not pressed" 1 "Brake pedal pressed" 2 "Not used" 3 "Error Indicator" ;
VAL_ 2244048130 ESC_PrkBrkActvSta 0 "Parking brake is not activated" 1 "Parking brake is activated" 2 "Not used" 3 "Error Indicator" ;
VAL_ 2244048130 ESC_HDP_FltMonSta 0 "No Fault" 1 "Main Controller Fault Detected (ADAS_DRV 2)" 2 "Sub Controller Fault Detected (FR_CMR)" 3 "Main & Sub Controller Fault Detected (ADAS_DRV 2 & FR_CMR)" 4 "Reserved" 5 "Reserved" 6 "Reserved" 7 "Reserved" ;
VAL_ 2244048130 FCA_EquipSta 0 "FCA is not equipped" 1 "FCA is equipped" 2 "Not used" 3 "Not Coded" ;
VAL_ 2244048130 FCA_AvlblSta 0 "Available" 1 "Temporarily not available" 2 "Permanently not available" 3 "FCA Communication Error" ;
VAL_ 2244048130 ESC_FCA_ActvSta 0 "FCA Brake is not in activation" 1 "FCA Pre-Brake" 2 "FCA Full-Brake" 3 "Invalid" ;
VAL_ 2244048130 ESC_DBS_ActvSta 0 "DBS control is inactive" 1 "DBS control is active" 2 "Not used" 3 "Not used" ;
VAL_ 2244048130 SCC_TqReq 0 "No request" 1 "Enable SCC torque request" 2 "Not used" 3 "Error Indicator" ;
VAL_ 2244048130 ESC_HDP_EgSta 0 "Not engaged" 1 "Engaged in main controller by IEB (ESC)" 2 "Engaged in sub controller by IEB (ESC)" 3 "MRM with IEB (ESC) alone" 4 "Engaged in main controller by RCU" 5 "Engaged in sub controller by RCU" 6 "MRM with RCU alone" 7 "Reserved" ;
VAL_ 2244048130 ESC_HDP_EnblReq 0 "No Fault" 1 "Req. longitudinal control normal, Functional Fault" 2 "Req. longitudinal control normal, Partial performance degradation" 3 "Req. longitudinal control abnormal, Brake control possible" 4 "Req. longitudinal control abnormal, Brake control impossible" 5 "Req. longitudinal control normal, Acceleration control Fault (eg. Engine Fault)" 6 "Reserved" 7 "Reserved" ;
VAL_ 2244048130 ESC_BrkdFltStndstill 0 "Undetected" 1 "Detected" 2 "Not used" 3 "Not used" ;
VAL_ 2244048130 SCC_ReqLimSta 0 "No request" 1 "Limited No Limitation" 2 "Acceleration Limited" 3 "Deceleration Limited" ;
VAL_ 2244048130 ESC_StdStillVal 0 "No stand still detected" 1 "stand still detected" 2 "Not used" 3 "Error Indicator" ;
VAL_ 2244048131 ESC_RccaSta 0 "RCCA availble" 1 "RCCA brake started" 2 "RCCA braking is ended" 3 "RCCA braking error" ;
VAL_ 2244048131 ESC_RspaCanFlFlag 0 "ESC received RSPA CAN message successfully" 1 "ESC failed to receive RSPA CAN message successfully" 2 "Not used" 3 "Error Indicator" ;
VAL_ 2244048131 ESC_RspaDclActv 0 "Inactive" 1 "Active" 2 "Not used" 3 "Error Indicator" ;
VAL_ 2244048131 ESC_RspaStandStill 0 "Initial" 1 "ESC stopped the vehicle by RSPA request" 2 "Not used" 3 "Error Indicator" ;
VAL_ 2244048131 ESC_PcaSta 0 "PCA available" 1 "PCA brake started" 2 "PCA brake ended" 3 "PCA disable" ;
VAL_ 2244048131 MCB_ReqBrkAck 0 "Wait Status for Crash" 1 "Received ACU Crash Information" 2 "Not used" 3 "Not used" ;
VAL_ 2244048131 MCB_CtlSta 0 "Not Activation" 1 "Activation" ;
VAL_ 2244048131 MCB_DefSta 0 "Normal state" 1 "Fail" ;
VAL_ 2244048131 ESC_DiffBrkFuncSta 0 "Differential braking available without error" 1 "Differential braking disable" 2 "Differential braking is activated" 3 "Error Indicator" ;
VAL_ 2244048131 ESC_LsdLimMod 0 "Maximum limitation mode" 1 "Minimum limitation mode" ;
VAL_ 2244048131 ESC_LsdOpn 0 "Passive" 1 "Fast Open" 2 "Slow Open" 3 "Torque Limit" 4 "eLSD Fail OPEN" 5 "Reserved" 6 "Reserved" 7 "Error" ;
VAL_ 2244048131 ESC_BcaRPlusSta 0 "BCA-R+ available" 1 "BCA-R+ braking is started" 2 "BCA-R+ braking is ended" 3 "BCA-R+ braking error" ;
VAL_ 2244048131 ESC_RspaSta 0 "Not used" 1 "ESC Initial" 2 "ESC New Start" 3 "ESC Ready" 4 "Not used" 5 "ESC Assist" 6 "ESC Assist Fail" 7 "ESC Abort" 8 "ESC Ready Fail" ;
VAL_ 721 HU_DR_Position_Status 1 "Valid" ;
VAL_ 721 HU_DR_Altitude_Status 1 "valid" ;
VAL_ 721 HU_DR_Heading_Status 1 "Valid" ;
VAL_ 721 HU_DR_Speed_Status 1 "Valid" ;
VAL_ 721 HU_DR_DirectionSwitch_Sta 1 "Valid" ;
VAL_ 721 HU_DR_Direction 1 "Backward" ;
VAL_ 721 HU_DR_GyroCalib_Sta 1 "Calibrated" ;
VAL_ 721 HU_DR_TachoCalib_Sta 1 "Calibrated" ;
VAL_ 721 HU_DR_Solution_Sta 0 "invalid" 1 "DR valid" ;
VAL_ 721 HU_DR_GNSS_Fix_Age 1 "0x0x1~0xFE:time since last GNSS fix" 254 "0x0x1~0xFE:time since last GNSS fix" 255 "No GNSS fix yet" ;
VAL_ 2164277249 TCU_GearSlctDis 0 "P" 1 "L" 2 "2" 3 "3" 4 "DS Mode" 5 "D" 6 "N" 7 "R" 8 "sports mode / manual shift / paddle shift" 9 "Not Display at Cluster" 10 "Sub-Rom Communication" 11 "Sub-Rom Communication Error" 12 "Paddle shift (D-position)" 13 "Reserved" 14 "Intermediate Position" 15 "fault" ;
VAL_ 2164277249 TCU_Typ 0 "Reserved" 1 "Step A" 2 "CVT" 3 "DCT" 4 "AMT" 5 "eClutch (2pedal)" 6 "eClutch (3pedal)" ;
VAL_ 2164277249 TCU_TqRdctnVal 0 "Max. reduction" 2047 "No reduction" 2048 "reduction to 0 torque" ;
VAL_ 2164277249 TCU_GearStepTyp 3 "3 - Speed AT or DCT" 4 "4 - Speed AT or DCT" 5 "5 - Speed AT or DCT" 6 "6 - Speed AT or DCT" 7 "7- Speed AT or DCT" 8 "8 - Speed AT or DCT" ;
VAL_ 2164277249 TCU_GearShftSta 0 "no gear change" 1 "gear change is active" 2 "Not used" 3 "Error Indicator" ;
VAL_ 2164277249 TCU_TqCnvrtrSta 0 "No lock up control" 1 "Slip lock up" 2 "Fully lock up" 3 "Off slip lock up" ;
VAL_ 2164277250 TCU_CurrGearSta 0 "if N or P are detected (no frictional connection)" 1 "1st speed" 2 "2nd speed" 3 "3rd speed" 4 "4th speed" 5 "5th speed" 6 "6th speed" 7 "7th speed" 8 "8th speed" 14 "Reverse speed" ;
VAL_ 2164277250 TCH_EngTrgtGearSta 0 "if N or P are detected (no frictional connection)" 1 "1st speed" 2 "2nd speed" 3 "3rd speed" 4 "4th speed" 5 "5th speed" 6 "6th speed" 7 "7th speed" 8 "8th speed" 14 "Reverse speed" ;
VAL_ 2164277250 TCU_EngTqLimVal 0 "Max. reduction" 2047 "No reduction" 2048 "reduction to 0 torque" ;
VAL_ 2164277250 TCU_CluTrgtGearConfg 0 "TCU_TrgtGearSta" 1 "TCU_CluTrgtGearSta" 2 "Not Used" 3 "Error Indicator" ;
VAL_ 2164277250 TCU_VehSpdKphVal 255 "Error Indicator" ;
VAL_ 2164277250 TCU_TrgtGearSta 0 "if N or P are detected (no frictional connection)" 1 "1st speed" 2 "2nd speed" 3 "3rd speed" 4 "4th speed" 5 "5th speed" 6 "6th speed" 7 "7th speed" 8 "8th speed" 14 "Reverse speed" ;
VAL_ 2164277250 TCU_DcmlVehSpdKphVal 0 "Error Indicator" ;
VAL_ 2164277250 TCU_GearLmpBlnkngReq 0 "No blink" 1 "Request lamp blinking" 2 "Not used" 3 "Error Indicator" ;
VAL_ 2164277250 TCU_FuelCutInhbtReq 0 "No request" 1 "Fuel cut inhibition request from TCU" 2 "Not used" 3 "Error Indicator" ;
VAL_ 2164277250 TCU_IdleUpReq 0 "No IDLE UP request" 1 "IDLE UP request" 2 "Not used" 3 "Error Indicator" ;
VAL_ 2164277250 TCU_CluTrgtGearSta 0 "if N or P are detected (no frictional connection)" 1 "1st speed" 2 "2nd speed" 3 "3rd speed" 4 "4th speed" 5 "5th speed" 6 "6th speed" 7 "7th speed" 8 "8th speed" 14 "Reverse speed" ;
VAL_ 2164277251 TCU_EngRpmDis 65535 "Error Indicator" ;
VAL_ 2164277251 TCU_EngSpdIncReq 0 "No request" 1 "Engine speed increase is requested" 2 "Not used" 3 "Error Indicator" ;
VAL_ 2164277251 TCU_ObdSta 0 "Default" 2 "Failure information of TCU" 3 "Failure information of TCU" 4 "MIL on request" 5 "MIL on request" 6 "Failure information of TCU & MIL on request" 7 "Failure information of TCU & MIL on request" ;
VAL_ 2164277251 TCU_SprtyIndxSta 0 "Invalid" 1 "Step 1" 2 "Step 2" 3 "Step 3" 4 "Step 4" 5 "Step 5" 6 "Step 6" 7 "Step 7" 8 "Step 8" 9 "Step 9" 10 "Step 10" 11 "Step 11" 12 "Step 12" 13 "Step 13" 14 "Step 14" 15 "Step 15" 16 "Step 16" 17 "Step 17" 18 "Step 18" 19 "Step 19" 20 "Step 20" 21 "Step 21" 22 "Step 22" 23 "Step 23" 24 "Step 24" 25 "Step 25" 26 "Invalid" 27 "Invalid" 28 "Invalid" 29 "Invalid" 30 "Invalid" 31 "Invalid" ;
VAL_ 2164277251 TCU_DrvngModDis 0 "Inactive" 1 "Normal" 2 "Eco" 3 "Eco+" 4 "Sport" 5 "Sport+" 6 "Snow" 7 "Reserved" ;
VAL_ 2164277251 TCU_DrvngModReq 0 "Inactive" 1 "Normal" 2 "Eco" 3 "Eco+" 4 "Sport" 5 "Sport+" 6 "Snow" 7 "Reserved" ;
VAL_ 2164277251 TCU_SmrtShftSta 0 "Smart Shift not Applied" 1 "Smart Shift Applied" 2 "Not used" 3 "Error Indicator" ;
VAL_ 2164277251 TCU_FrtStcShftSta 0 "First static shift function is not activated." 1 "First static shift function is activated" 2 "Not used" 3 "Error Indicator" ;
VAL_ 2164277251 TCU_IsgInhbtReq 0 "TCU inhibits the ISG function" 1 "ISG is available" 2 "Not used" 3 "Error Indicator" ;
VAL_ 2164277251 TCU_CdaInhbtReq 0 "CDA transition is available" 1 "TCU prohibits CDA transition" 2 "Not used" 3 "Error Indicator" ;
VAL_ 2164277251 TCU_BrkOnReq 0 "No request" 1 "Brake On Request" 2 "Not used" 3 "Error Indicator" ;
VAL_ 2164277251 TCU_TqGrdntLimVal 255 "No torque gradient limitation" ;
VAL_ 2164277252 TCU_NetrlCtrlSta 0 "No NC" 1 "NC Entry" 2 "NC Applied" 3 "NC Exit" ;
VAL_ 2164277252 TCU_ShftPtrnSta 0 "Normal (ECO)" 1 "Uphill 1 (Optional)" 2 "Uphill 2 (Optional)" 3 "Reserved" 4 "Downhill 1 (Optional)" 5 "Cruise (Optional)" 6 "Cruise_Uphill 1 (Optional)" 7 "Cruise_Uphill 2 (Optional)" 8 "Active ECO (Optional)" 9 "Sport Drive (Optional)" 15 "None of the above" ;
VAL_ 2164277252 TCU_EPBReq 0 "No Request (default)" 1 "EPB Request" ;
VAL_ 2164277252 IMT_EOLstate 0 "display gear info using 'TCU_GearSlctDis'" 1 "display gear info by alphabet 'E'" ;
VAL_ 2164277252 IMT_DisCmd 0 "Not Display" 1 "Display (Not blinking)" 2 "Display (blinking)" 3 "Reserved" ;
VAL_ 2164277252 DCT_RegenInhbt 0 "No Inhibit" 1 "Regen. Inhibit" 2 "Not Used" 3 "Error Indicator" ;
VAL_ 2164277252 DCT_EngIdleReq 0 "No Request" 1 "Idle Request" 2 "Not Used" 3 "Error Indicator" ;
VAL_ 2164277252 DCT_CltchState 0 "Drivetrain (Both Clutch) Open" 1 "Odd Clutch Slipping" 2 "Even Clutch Slipping" 3 "Clutch Locked" ;
VAL_ 2164277252 DCT_FuelCutReq 0 "No request" 1 "Fuel Cut Request" 2 "Not Used" 3 "Error Indicator" ;
VAL_ 2164277252 DCT_TqIncReq 0 "No Request" 1 "Torque increase Request" 2 "Not Used" 3 "Error Indicator" ;
VAL_ 2164277252 DCT_ShftTqReq 0 "No request" 2047 "Max. Increase" 2048 "reduction to 0 torque" ;
VAL_ 2164277252 TCU_VgisInhbtReq 0 "There¡¯s no request from TCU" 1 "TCU inhibits ECU from changing VGIS status" 2 "Not used" 3 "Error Indicator" ;
VAL_ 2164277252 TCU_EngTqIncReqVal 0 "No request" 2047 "Max. Increase" 2048 "reduction to 0 torque" ;
VAL_ 2189467649 WHL_PlsFLVal 255 "Error" ;
VAL_ 2189467649 WHL_PlsFRVal 255 "Error" ;
VAL_ 2189467649 WHL_PlsRLVal 255 "Error" ;
VAL_ 2189467649 WHL_PlsRRVal 255 "Error" ;
VAL_ 2189467649 WHL_DirFLVal 0 "Unknown (Wheel moving stop state or Not applied wheel sensor for direction)" 1 "Forward direction" 2 "Backward direction" 3 "Error identifier" ;
VAL_ 2189467649 WHL_DirFRVal 0 "Unknown (Wheel moving stop state or Not applied wheel sensor for direction)" 1 "Forward direction" 2 "Backward direction" 3 "Error identifier" ;
VAL_ 2189467649 WHL_DirRLVal 0 "Unknown (Wheel moving stop state or Not applied wheel sensor for direction)" 1 "Forward direction" 2 "Backward direction" 3 "Error identifier" ;
VAL_ 2189467649 WHL_DirRRVal 0 "Unknown (Wheel moving stop state or Not applied wheel sensor for direction)" 1 "Forward direction" 2 "Backward direction" 3 "Error identifier" ;
VAL_ 2189467650 WHL_SpdFLVal 16383 "Error" ;
VAL_ 2189467650 WHL_SpdFRVal 16383 "Error" ;
VAL_ 2189467650 WHL_SpdRLVal 16383 "Error" ;
VAL_ 2189467650 WHL_SpdRRVal 16383 "Error" ;
